VERSION "dbc-export 1 2025.20.8"

NS_ :

BS_:

BU_: ADSP APB APP APS APSB BB BMS CC CMP CMPD CP DAS DI DIF DIR DPB EPAS3P EPAS3S EPASTP EPASTS EPBL EPBR ESP GTW HVP IBST ICR IDB OCS1P ODIN PARK PCS PLG PM PMF PMR PTC RADC RCM RCM2 RCU SCCM SDCR TAS TCU TPMS TRCM UDS UI UIS UMC USM VC VCFRONT VCLEFT VCRIGHT VCSEC

BO_ 1803 VCRIGHT_logging0point1Hz: 8 VCRIGHT
 SG_ VCRIGHT_logging0point1HzIndex M : 0|4@1+ (1,0) [0|15] "" Vector__XXX
 SG_ VCRIGHT_cabinAirFilterLifeRemain m2 : 8|7@1+ (1,0) [0|127] "%" Vector__XXX
 SG_ VCRIGHT_HEPAAirFilterLifeRemaini m2 : 16|7@1+ (1,0) [0|127] "%" Vector__XXX
 SG_ VCRIGHT_leftPTCCompromisedRod m2 : 24|3@1+ (1,0) [0|7] "" Vector__XXX
 SG_ VCRIGHT_rightPTCCompromisedRod m2 : 27|3@1+ (1,0) [0|7] "" Vector__XXX
 SG_ VCRIGHT_hepaFilterHealthScore m2 : 32|7@1+ (1,0) [0|127] "%" Vector__XXX
 SG_ VCRIGHT_cabinFilterHealthScore m2 : 40|7@1+ (1,0) [0|127] "%" Vector__XXX
 SG_ VCRIGHT_cabinTempBreathLevelFOff m2 : 47|8@1+ (0.5,-40) [-40|80] "degC" Vector__XXX
 SG_ VCRIGHT_airDistributionModeAdjus m2 : 55|9@1+ (0.001,1) [1|1.5] "-" Vector__XXX
 SG_ VCRIGHT_hvacLHBleedEndStop m3 : 8|8@1+ (0.02,0) [0|5] "V" Vector__XXX
 SG_ VCRIGHT_hvacRHBleedEndStop m3 : 16|8@1+ (0.02,0) [0|5] "V" Vector__XXX
 SG_ VCRIGHT_hvacLHVaneEndStop m3 : 24|8@1+ (0.02,0) [0|5] "V" Vector__XXX
 SG_ VCRIGHT_hvacRHVaneEndStop m3 : 32|8@1+ (0.02,0) [0|5] "V" Vector__XXX
 SG_ VCRIGHT_hvacUpperModeEndStop m3 : 40|8@1+ (0.02,0) [0|5] "V" Vector__XXX
 SG_ VCRIGHT_hvacLowerModeEndStop m3 : 48|8@1+ (0.02,0) [0|5] "V" Vector__XXX
 SG_ VCRIGHT_hvacIntakeEndStop m3 : 56|8@1+ (0.02,0) [0|5] "V" Vector__XXX
 SG_ VCRIGHT_hvacLHBleedZeroStop m4 : 8|8@1+ (0.02,0) [0|5] "V" Vector__XXX
 SG_ VCRIGHT_hvacRHBleedZeroStop m4 : 16|8@1+ (0.02,0) [0|5] "V" Vector__XXX
 SG_ VCRIGHT_hvacLHVaneZeroStop m4 : 24|8@1+ (0.02,0) [0|5] "V" Vector__XXX
 SG_ VCRIGHT_hvacRHVaneZeroStop m4 : 32|8@1+ (0.02,0) [0|5] "V" Vector__XXX
 SG_ VCRIGHT_hvacUpperModeZeroStop m4 : 40|8@1+ (0.02,0) [0|5] "V" Vector__XXX
 SG_ VCRIGHT_hvacLowerModeZeroStop m4 : 48|8@1+ (0.02,0) [0|5] "V" Vector__XXX
 SG_ VCRIGHT_hvacIntakeZeroStop m4 : 56|8@1+ (0.02,0) [0|5] "V" Vector__XXX
 SG_ VCRIGHT_ambientTempLimp m6 : 8|8@1+ (0.5,-40) [-40|80] "degC" Vector__XXX
 SG_ VCRIGHT_cabinProbeTempLimp m6 : 16|8@1+ (0.5,-40) [-40|80] "degC" Vector__XXX
 SG_ VCRIGHT_thsTempLimp m6 : 24|8@1+ (0.5,-40) [-40|80] "degC" Vector__XXX
 SG_ VCRIGHT_thsCabinWaterMassLimp m6 : 32|8@1+ (0.5,0) [0|124] "g/kg" Vector__XXX
 SG_ VCRIGHT_thsSolarIrradianceLimp m6 : 40|8@1+ (5,0) [0|1270] "W/m2" Vector__XXX
 SG_ VCRIGHT_silentWakeRecordCount m6 : 48|5@1+ (1,0) [0|31] "" Vector__XXX
 SG_ VCRIGHT_evapCondensateMass m7 : 8|8@1+ (2,0) [0|500] "g" Vector__XXX
 SG_ VCRIGHT_airwaveRightLateralTotal m7 : 16|16@1+ (6100,0) [0|399763500] "deg" Vector__XXX
 SG_ VCRIGHT_airwaveLeftLateralTotalT m7 : 32|16@1+ (6100,0) [0|399763500] "deg" Vector__XXX

BO_ 611 VCRIGHT_logging10Hz: 8 VCRIGHT
 SG_ VCRIGHT_logging10HzIndex M : 0|3@1+ (1,0) [0|7] "" Vector__XXX
 SG_ VCRIGHT_hvacLHBleedTarget m0 : 8|8@1+ (0.4,0) [0|100] "%" Vector__XXX
 SG_ VCRIGHT_hvacRHBleedTarget m0 : 16|8@1+ (0.4,0) [0|100] "%" Vector__XXX
 SG_ VCRIGHT_hvacLHVaneTarget m0 : 24|8@1+ (0.4,0) [0|100] "%" Vector__XXX
 SG_ VCRIGHT_hvacRHVaneTarget m0 : 32|8@1+ (0.4,0) [0|100] "%" Vector__XXX
 SG_ VCRIGHT_hvacUpperModeTarget m0 : 40|8@1+ (0.4,0) [0|100] "%" Vector__XXX
 SG_ VCRIGHT_hvacLowerModeTarget m0 : 48|8@1+ (0.4,0) [0|100] "%" Vector__XXX
 SG_ VCRIGHT_hvacIntakeTarget m0 : 56|8@1+ (0.4,0) [0|100] "%" Vector__XXX
 SG_ VCRIGHT_hvacLHBleedPosition m1 : 8|8@1+ (0.4,0) [0|100] "%" Vector__XXX
 SG_ VCRIGHT_hvacRHBleedPosition m1 : 16|8@1+ (0.4,0) [0|100] "%" Vector__XXX
 SG_ VCRIGHT_hvacLHVanePosition m1 : 24|8@1+ (0.4,0) [0|100] "%" Vector__XXX
 SG_ VCRIGHT_hvacRHVanePosition m1 : 32|8@1+ (0.4,0) [0|100] "%" Vector__XXX
 SG_ VCRIGHT_hvacUpperModePosition m1 : 40|8@1+ (0.4,0) [0|100] "%" Vector__XXX
 SG_ VCRIGHT_hvacLowerModePosition m1 : 48|8@1+ (0.4,0) [0|100] "%" Vector__XXX
 SG_ VCRIGHT_hvacIntakePosition m1 : 56|8@1+ (0.4,0) [0|100] "%" Vector__XXX
 SG_ VCRIGHT_hvacLHBleedActuatorState m2 : 3|2@1+ (1,0) [0|3] "" Vector__XXX
 SG_ VCRIGHT_hvacRHBleedActuatorState m2 : 5|2@1+ (1,0) [0|3] "" Vector__XXX
 SG_ VCRIGHT_hvacLHVaneActuatorState m2 : 8|2@1+ (1,0) [0|3] "" Vector__XXX
 SG_ VCRIGHT_hvacRHVaneActuatorState m2 : 10|2@1+ (1,0) [0|3] "" Vector__XXX
 SG_ VCRIGHT_hvacUpperModeActState m2 : 12|2@1+ (1,0) [0|3] "" Vector__XXX
 SG_ VCRIGHT_hvacLowerModeActState m2 : 14|2@1+ (1,0) [0|3] "" Vector__XXX
 SG_ VCRIGHT_hvacIntakeActuatorState m2 : 16|2@1+ (1,0) [0|3] "" Vector__XXX
 SG_ VCRIGHT_EvapPulldownBiasActive m2 : 20|1@1+ (1,0) [0|1] "" Vector__XXX
 SG_ VCRIGHT_tempDatLeftEst m2 : 21|9@1+ (0.5,-22) [-22|200] "degC" Vector__XXX
 SG_ VCRIGHT_tempDatRightEst m2 : 30|9@1+ (0.5,-22) [-22|200] "degC" Vector__XXX
 SG_ VCRIGHT_tempDuctLeftEst m2 : 40|8@1+ (0.5,-22) [-22|105] "degC" Vector__XXX
 SG_ VCRIGHT_tempDuctRightEst m2 : 48|8@1+ (0.5,-22) [-22|105] "degC" Vector__XXX
 SG_ VCRIGHT_ptcHeaterBadRodDetection m2 : 56|4@1+ (1,0) [0|15] "" Vector__XXX
 SG_ VCRIGHT_leftVerticalActuatorDuty m4 : 8|6@1- (4,0) [-100|100] "%" Vector__XXX
 SG_ VCRIGHT_leftLateralActuatorDuty m4 : 16|6@1- (4,0) [-100|100] "%" Vector__XXX
 SG_ VCRIGHT_rightVerticalActuatorDut m4 : 24|6@1- (4,0) [-100|100] "%" Vector__XXX
 SG_ VCRIGHT_rightLateralActuatorDuty m4 : 30|6@1- (4,0) [-100|100] "%" Vector__XXX
 SG_ VCRIGHT_frontLeftSeatTempTargetQ m4 : 36|6@1+ (0.75,20) [20|60] "degC" Vector__XXX
 SG_ VCRIGHT_frontRightSeatTempTarget m4 : 42|6@1+ (1,20) [20|60] "degC" Vector__XXX

BO_ 691 VCRIGHT_logging1Hz: 8 VCRIGHT
 SG_ VCRIGHT_logging1HzIndex M : 0|5@1+ (1,0) [0|31] "" Vector__XXX
 SG_ VCRIGHT_tempIncarCabinProbe m0 : 8|8@1+ (0.5,-40) [-40|85] "degC" Vector__XXX
 SG_ VCRIGHT_tempIncarCabinDeep m0 : 16|8@1+ (0.5,-40) [-40|85] "degC" Vector__XXX
 SG_ VCRIGHT_cabinTempInteriorL2 m0 : 24|8@1+ (0.5,-40) [-40|80] "degC" Vector__XXX
 SG_ VCRIGHT_tempIncarCabinMid m0 : 32|8@1+ (0.5,-40) [-40|85] "degC" Vector__XXX
 SG_ VCRIGHT_cabinTempInteriorSunnyL2 m0 : 40|8@1+ (0.6,-40) [-40|100] "degC" Vector__XXX
 SG_ VCRIGHT_cabinTempInteriorL3 m0 : 48|8@1+ (0.5,-40) [-40|80] "degC" Vector__XXX
 SG_ VCRIGHT_cabinTempInteriorSunnyL3 m0 : 56|8@1+ (0.6,-40) [-40|100] "degC" Vector__XXX
 SG_ VCRIGHT_cabinTempGlassRoof m1 : 8|8@1+ (0.5,-40) [-40|80] "degC" Vector__XXX
 SG_ VCRIGHT_cabinTempWindshield m1 : 16|8@1+ (0.5,-40) [-40|80] "degC" Vector__XXX
 SG_ VCRIGHT_cabinTempInterior m1 : 24|8@1+ (0.5,-40) [-40|80] "degC" Vector__XXX
 SG_ VCRIGHT_cabinTempInteriorSunny m1 : 32|8@1+ (0.6,-40) [-40|100] "degC" Vector__XXX
 SG_ VCRIGHT_cabinTempSideGlassLeft m1 : 40|8@1+ (0.5,-40) [-40|80] "degC" Vector__XXX
 SG_ VCRIGHT_cabinTempSideGlassRight m1 : 48|8@1+ (0.5,-40) [-40|80] "degC" Vector__XXX
 SG_ VCRIGHT_cabinTempBreathLevel m1 : 56|8@1+ (0.5,-40) [-40|80] "degC" Vector__XXX
 SG_ VCRIGHT_pcbaTemperature m2 : 5|11@1+ (0.125,-40) [-40|150] "degC" Vector__XXX
 SG_ VCRIGHT_wattsHeaterLeftTotal m2 : 16|10@1+ (5,0) [0|4000] "W" Vector__XXX
 SG_ VCRIGHT_wattsHeaterRightTotal m2 : 26|10@1+ (5,0) [0|4000] "W" Vector__XXX
 SG_ VCRIGHT_qdotLeftFFUnsat m2 : 36|9@1- (10,0) [-1500|1500] "W" Vector__XXX
 SG_ VCRIGHT_qdotRightFFUnsat m2 : 45|9@1- (10,0) [-1500|1500] "W" Vector__XXX
 SG_ VCRIGHT_nvhLevelDb m2 : 54|9@1+ (0.1,30) [30|80] "dB" Vector__XXX
 SG_ VCRIGHT_hvacSetTempActualLeft m3 : 8|8@1+ (0.1,15) [15|28] "degC" Vector__XXX
 SG_ VCRIGHT_hvacSetTempActualRight m3 : 16|8@1+ (0.1,15) [15|28] "degC" Vector__XXX
 SG_ VCRIGHT_hvacAutoTransitionReason m3 : 24|5@1+ (1,0) [0|31] "" Vector__XXX
 SG_ VCRIGHT_hvacMassflowTarget m3 : 29|8@1+ (1,0) [0|200] "g/s" Vector__XXX
 SG_ VCRIGHT_hvacQdotLimitedLeft m3 : 37|1@1+ (1,0) [0|1] "" Vector__XXX
 SG_ VCRIGHT_hvacQdotLimitedRight m3 : 38|1@1+ (1,0) [0|1] "" Vector__XXX
 SG_ VCRIGHT_LHPanelAirflowBlocked m3 : 39|1@1+ (1,0) [0|1] "" Vector__XXX
 SG_ VCRIGHT_RHPanelAirflowBlocked m3 : 40|1@1+ (1,0) [0|1] "" Vector__XXX
 SG_ VCRIGHT_floorAirflowBlocked m3 : 41|1@1+ (1,0) [0|1] "" Vector__XXX
 SG_ VCRIGHT_defrostAirflowBlocked m3 : 42|1@1+ (1,0) [0|1] "" Vector__XXX
 SG_ VCRIGHT_hvacFilterLifeDetectActi m3 : 43|1@1+ (1,0) [0|1] "" Vector__XXX
 SG_ VCRIGHT_hvacLHBleedOperationMode m3 : 44|1@1+ (1,0) [0|1] "" Vector__XXX
 SG_ VCRIGHT_hvacRHBleedOperationMode m3 : 45|1@1+ (1,0) [0|1] "" Vector__XXX
 SG_ VCRIGHT_hvacLHVaneOperationMode m3 : 46|1@1+ (1,0) [0|1] "" Vector__XXX
 SG_ VCRIGHT_hvacRHVaneOperationMode m3 : 47|1@1+ (1,0) [0|1] "" Vector__XXX
 SG_ VCRIGHT_hvacUpperModeOpMode m3 : 48|1@1+ (1,0) [0|1] "" Vector__XXX
 SG_ VCRIGHT_hvacLowerModeOpMode m3 : 49|1@1+ (1,0) [0|1] "" Vector__XXX
 SG_ VCRIGHT_hvacIntakeOperationMode m3 : 50|1@1+ (1,0) [0|1] "" Vector__XXX
 SG_ VCRIGHT_isProbeFeedbackApplied m3 : 52|3@1+ (1,0) [0|7] "" Vector__XXX
 SG_ VCRIGHT_feedbackPullDownScalar m3 : 55|2@1+ (30,70) [70|130] "-" Vector__XXX
 SG_ VCRIGHT_feedForwardPullDownScala m3 : 57|6@1+ (1,70) [70|130] "-" Vector__XXX
 SG_ VCRIGHT_convectionTargetLeft m4 : 5|9@1+ (4,-1000) [-1000|1000] "W/m2" Vector__XXX
 SG_ VCRIGHT_convectionTargetRight m4 : 14|9@1+ (4,-1000) [-1000|1000] "W/m2" Vector__XXX
 SG_ VCRIGHT_convectionDeliveredLeft m4 : 23|9@1+ (4,-1000) [-1000|1000] "W/m2" Vector__XXX
 SG_ VCRIGHT_convectionDeliveredRight m4 : 32|9@1+ (4,-1000) [-1000|1000] "W/m2" Vector__XXX
 SG_ VCRIGHT_solarLoadRightOccupant m4 : 41|7@1+ (2,0) [0|252] "W/m2" Vector__XXX
 SG_ VCRIGHT_solarLoadLeftOccupant m4 : 48|7@1+ (2,0) [0|252] "W/m2" Vector__XXX
 SG_ VCRIGHT_ptcShutOutletMitigationA m4 : 55|1@1+ (1,0) [0|1] "" Vector__XXX
 SG_ VCRIGHT_solarLoadFromThsTemp m4 : 56|8@1+ (8,-1020) [-1020|1012] "W/m2" Vector__XXX
 SG_ VCRIGHT_ptcHeaterTempDuctHigh m5 : 5|1@1+ (1,0) [0|1] "" Vector__XXX
 SG_ VCRIGHT_ptcHeaterTempDuctFault m5 : 6|1@1+ (1,0) [0|1] "" Vector__XXX
 SG_ VCRIGHT_ptcHeaterNoAirflow m5 : 7|1@1+ (1,0) [0|1] "" Vector__XXX
 SG_ VCRIGHT_ptcHeaterHvacActNotReady m5 : 8|1@1+ (1,0) [0|1] "" Vector__XXX
 SG_ VCRIGHT_ptcHeaterNoUiRequest m5 : 9|1@1+ (1,0) [0|1] "" Vector__XXX
 SG_ VCRIGHT_ptcHeaterNoHighVoltage m5 : 10|1@1+ (1,0) [0|1] "" Vector__XXX
 SG_ VCRIGHT_ptcHeaterLAirPathBlocked m5 : 11|1@1+ (1,0) [0|1] "" Vector__XXX
 SG_ VCRIGHT_ptcHeaterRAirPathBlocked m5 : 12|1@1+ (1,0) [0|1] "" Vector__XXX
 SG_ VCRIGHT_ptcHeaterReqAirpathBlock m5 : 13|1@1+ (1,0) [0|1] "" Vector__XXX
 SG_ VCRIGHT_hvacQdotFeedforward m5 : 16|16@1+ (1,-32767) [-32767|32767] "W" Vector__XXX
 SG_ VCRIGHT_evapLoadInFresh m5 : 32|8@1+ (35,0) [0|8000] "W" Vector__XXX
 SG_ VCRIGHT_evapLoadInRecirc m5 : 40|8@1+ (35,0) [0|8000] "W" Vector__XXX
 SG_ VCRIGHT_cabinTempWshldDefog m5 : 48|8@1+ (0.5,-40) [-40|80] "degC" Vector__XXX
 SG_ VCRIGHT_cabinTempWshldDefogTop m5 : 56|8@1+ (0.5,-40) [-40|80] "degC" Vector__XXX
 SG_ VCRIGHT_hvacLHBleedVoltage m6 : 8|8@1+ (0.02,0) [0|5] "V" Vector__XXX
 SG_ VCRIGHT_hvacRHBleedVoltage m6 : 16|8@1+ (0.02,0) [0|5] "V" Vector__XXX
 SG_ VCRIGHT_hvacLHVaneVoltage m6 : 24|8@1+ (0.02,0) [0|5] "V" Vector__XXX
 SG_ VCRIGHT_hvacRHVaneVoltage m6 : 32|8@1+ (0.02,0) [0|5] "V" Vector__XXX
 SG_ VCRIGHT_hvacUpperModeVoltage m6 : 40|8@1+ (0.02,0) [0|5] "V" Vector__XXX
 SG_ VCRIGHT_hvacLowerModeVoltage m6 : 48|8@1+ (0.02,0) [0|5] "V" Vector__XXX
 SG_ VCRIGHT_hvacIntakeVoltage m6 : 56|8@1+ (0.02,0) [0|5] "V" Vector__XXX
 SG_ VCRIGHT_cabinTempBreathLevelFHea m7 : 8|8@1+ (0.5,-40) [-40|80] "degC" Vector__XXX
 SG_ VCRIGHT_cabinTempBreathLevelFCoo m7 : 16|8@1+ (0.5,-40) [-40|80] "degC" Vector__XXX
 SG_ VCRIGHT_cabinTempBreathLeve_0002 m7 : 24|8@1+ (0.5,-40) [-40|80] "degC" Vector__XXX
 SG_ VCRIGHT_cabinTempBreathLevelF5mi m7 : 32|8@1+ (0.5,-40) [-40|80] "degC" Vector__XXX
 SG_ VCRIGHT_cabinTempBreathLeve_0001 m7 : 40|8@1+ (0.5,-40) [-40|80] "degC" Vector__XXX
 SG_ VCRIGHT_cabinTempBreathLevelF10m m7 : 48|8@1+ (0.5,-40) [-40|80] "degC" Vector__XXX
 SG_ VCRIGHT_cabinTempInteriorFHeatin m7 : 56|8@1+ (0.5,-40) [-40|80] "degC" Vector__XXX
 SG_ VCRIGHT_hvacCabOvrheatProtActive m8 : 5|1@1+ (1,0) [0|1] "" Vector__XXX
 SG_ VCRIGHT_hvacCabinPurgeAllowed m8 : 6|1@1+ (1,0) [0|1] "" Vector__XXX
 SG_ VCRIGHT_hvacCabOvrheatProtAllowe m8 : 7|1@1+ (1,0) [0|1] "" Vector__XXX
 SG_ VCRIGHT_filterLifeBlowerTorque m8 : 8|10@1+ (0.006,-1.5) [-1.5|4.5] "Nm" Vector__XXX
 SG_ VCRIGHT_cabinTempFanCurrent m8 : 18|6@1+ (0.001,-0.01) [-0.01|0.05] "A" Vector__XXX
 SG_ VCRIGHT_cabinTempFanOutput m8 : 24|1@1+ (1,0) [0|1] "" Vector__XXX
 SG_ VCRIGHT_cloudinessEstimatedPct m8 : 25|7@1+ (1,0) [0|100] "%" Vector__XXX
 SG_ VCRIGHT_solarLoadOnVehFiltered m8 : 32|8@1+ (4,0) [0|1016] "W/m2" Vector__XXX
 SG_ VCRIGHT_cabinTempProbeEstimate m8 : 40|8@1+ (0.5,-40) [-40|80] "degC" Vector__XXX
 SG_ VCRIGHT_cabinTempThs m8 : 48|8@1+ (0.5,-40) [-40|80] "degC" Vector__XXX
 SG_ VCRIGHT_cabinTempThsBracket m8 : 56|8@1+ (0.5,-40) [-40|80] "degC" Vector__XXX
 SG_ VCRIGHT_leftHeatOvertempProtect m9 : 5|1@1+ (1,0) [0|1] "" Vector__XXX
 SG_ VCRIGHT_rightHeatOvertempProtect m9 : 6|1@1+ (1,0) [0|1] "" Vector__XXX
 SG_ VCRIGHT_CO2ppm m9 : 7|10@1+ (5,0) [0|4000] "-" Vector__XXX
 SG_ VCRIGHT_timeLeftToCabinModelInit m9 : 17|7@1+ (1,0) [0|127] "" Vector__XXX
 SG_ VCRIGHT_hvacEstimateWindshieldRH m9 : 24|8@1+ (1,0) [0|150] "%" Vector__XXX
 SG_ VCRIGHT_hvacFoggingRiskLevel m9 : 32|7@1+ (1,0) [0|100] "%" Vector__XXX
 SG_ VCRIGHT_hvacCabinHumidityLevel m9 : 39|7@1+ (1,0) [0|100] "%" Vector__XXX
 SG_ VCRIGHT_hvacFlashFoggingDetected m9 : 47|1@1+ (1,0) [0|1] "" Vector__XXX
 SG_ VCRIGHT_solarSensitivityInfr m9 : 48|7@1+ (1,0) [0|100] "-" Vector__XXX
 SG_ VCRIGHT_solarSensitivityInfrCorr m9 : 55|7@1+ (1,0) [0|100] "-" Vector__XXX
 SG_ VCRIGHT_lumbarCurrent m10 : 5|4@1+ (0.2,0) [0|3] "A" Vector__XXX
 SG_ VCRIGHT_ocsCurrent m10 : 9|3@1+ (0.01,0) [0|0.07] "A" Vector__XXX
 SG_ VCRIGHT_rcmCurrent m10 : 12|5@1+ (0.1,0) [0|3.1] "A" Vector__XXX
 SG_ VCRIGHT_radioTunerCurrent m10 : 17|4@1+ (0.1,0) [0|1.5] "A" Vector__XXX
 SG_ VCRIGHT_rearOilPumpCurrent m10 : 21|5@1+ (0.5,0) [0|15.5] "A" Vector__XXX
 SG_ VCRIGHT_rearDefrostCurrent m10 : 26|5@1+ (2,0) [0|62] "A" Vector__XXX
 SG_ VCRIGHT_tailLightCurrent m10 : 31|4@1+ (0.1,0) [0|1.5] "A" Vector__XXX
 SG_ VCRIGHT_turnTailStopLightCurrent m10 : 35|4@1+ (0.1,0) [0|1.5] "A" Vector__XXX
 SG_ VCRIGHT_reverseFogLightsCurrent m10 : 39|4@1+ (0.1,0) [0|1.4] "A" Vector__XXX
 SG_ VCRIGHT_stopReverseTurnLightCurr m10 : 43|4@1+ (0.1,0) [0|1.5] "A" Vector__XXX
 SG_ VCRIGHT_sideMirrorCurrent m10 : 47|5@1+ (0.2,0) [0|6.2] "A" Vector__XXX
 SG_ VCRIGHT_sideMirrorHeaterCurrent m10 : 52|5@1+ (0.2,0) [0|6] "A" Vector__XXX
 SG_ VCRIGHT_frontSeatHeatCushionPwr m10 : 57|7@1+ (1,0) [0|127] "W" Vector__XXX
 SG_ VCRIGHT_trunkInteriorLEDCurrent m11 : 8|4@1+ (5,0) [0|70] "mA" Vector__XXX
 SG_ VCRIGHT_mapPocketLEDsCurrent m11 : 12|4@1+ (5,0) [0|70] "mA" Vector__XXX
 SG_ VCRIGHT_miscEFuseCurrent m11 : 16|5@1+ (0.05,0) [0|1.5] "A" Vector__XXX
 SG_ VCRIGHT_interiorHandleLEDCurrent m11 : 21|4@1+ (2,0) [0|30] "mA" Vector__XXX
 SG_ VCRIGHT_miscInteriorLightsCurren m11 : 25|3@1+ (5,0) [0|30] "mA" Vector__XXX
 SG_ VCRIGHT_frontPuddleLEDCurrent m11 : 28|3@1+ (0.05,0) [0|0.3] "A" Vector__XXX
 SG_ VCRIGHT_rearPuddleLEDCurrent m11 : 31|3@1+ (0.05,0) [0|0.3] "A" Vector__XXX
 SG_ VCRIGHT_liftgateShutfaceLEDCurre m11 : 34|3@1+ (5,0) [0|30] "mA" Vector__XXX
 SG_ VCRIGHT_3rSeatTOSCurrent m11 : 37|4@1+ (5,0) [0|70] "mA" Vector__XXX
 SG_ VCRIGHT_vbatFusedCurrent m11 : 41|4@1+ (0.1,0) [0|1.4] "A" Vector__XXX
 SG_ VCRIGHT_cabinTempGlassGridHeater m11 : 45|8@1+ (0.5,-40) [-40|80] "degC" Vector__XXX
 SG_ VCRIGHT_hvacAirflowReasonRight m11 : 53|5@1+ (1,0) [0|31] "" Vector__XXX
 SG_ VCRIGHT_hvacAirflowReasonLeft m11 : 58|5@1+ (1,0) [0|31] "" Vector__XXX
 SG_ VCRIGHT_hvacMassflowTargetLeft m12 : 5|8@1+ (1,0) [0|200] "g/s" Vector__XXX
 SG_ VCRIGHT_hvacMassflowTargetRight m12 : 13|8@1+ (1,0) [0|200] "g/s" Vector__XXX
 SG_ VCRIGHT_solarLoadLeftOccupantFil m12 : 21|7@1+ (2,0) [0|252] "W/m2" Vector__XXX
 SG_ VCRIGHT_solarLoadRightOccupantFi m12 : 28|7@1+ (2,0) [0|252] "W/m2" Vector__XXX
 SG_ VCRIGHT_windshieldRHCapped m12 : 35|8@1+ (1,0) [0|150] "%" Vector__XXX
 SG_ VCRIGHT_feedbackWarmUpScalar m12 : 43|2@1+ (16,84) [84|116] "-" Vector__XXX
 SG_ VCRIGHT_maxMassflowScalarWarmUp m12 : 45|5@1+ (1,74) [74|100] "-" Vector__XXX
 SG_ VCRIGHT_feedforwardWarmUpScalar m12 : 50|6@1+ (1,80) [80|120] "-" Vector__XXX
 SG_ VCRIGHT_frontSeatHeatBackrestPwr m12 : 56|7@1+ (1,0) [0|127] "W" Vector__XXX
 SG_ VCRIGHT_maxMassflowScalar m13 : 5|6@1+ (1,60) [60|100] "-" Vector__XXX
 SG_ VCRIGHT_massflowTargetAutoInManu m13 : 11|8@1+ (1,0) [0|250] "g/s" Vector__XXX
 SG_ VCRIGHT_airflowReasonAutoInManua m13 : 19|5@1+ (1,0) [0|31] "" Vector__XXX
 SG_ VCRIGHT_airflowReasonAutoIn_0001 m13 : 24|5@1+ (1,0) [0|31] "" Vector__XXX
 SG_ VCRIGHT_airflowReasonAutoIn_0002 m13 : 29|5@1+ (1,0) [0|31] "" Vector__XXX
 SG_ VCRIGHT_cabinTempInteriorFCoolin m13 : 34|8@1+ (0.5,-40) [-40|80] "degC" Vector__XXX
 SG_ VCRIGHT_averageDuctTempFHeating m13 : 42|8@1+ (0.5,-40) [-40|80] "degC" Vector__XXX
 SG_ VCRIGHT_averageDuctTempFCooling m13 : 50|8@1+ (0.5,-40) [-40|80] "degC" Vector__XXX
 SG_ VCRIGHT_hvacBiLevelWhsldRhEst m13 : 58|6@1+ (2,20) [20|120] "%" Vector__XXX
 SG_ VCRIGHT_steeringWheelSurfaceTemp m14 : 5|10@1+ (0.1,-35) [-35|65] "degC" Vector__XXX
 SG_ VCRIGHT_steeringWheelSurfac_0001 m14 : 16|10@1+ (0.1,-35) [-35|65] "degC" Vector__XXX
 SG_ VCRIGHT_timeToComfortHeating m14 : 26|6@1+ (15,-15) [-15|930] "s" Vector__XXX
 SG_ VCRIGHT_timeToComfortCooling m14 : 32|6@1+ (15,-15) [-15|930] "s" Vector__XXX
 SG_ VCRIGHT_cabinWaterMassRaw m14 : 40|8@1+ (0.1,0) [0|25] "g/kg" Vector__XXX
 SG_ VCRIGHT_massflowSingleZoneSplit m14 : 48|7@1+ (1,0) [0|100] "-" Vector__XXX
 SG_ VCRIGHT_VOCPurgeState m14 : 56|3@1+ (1,0) [0|7] "" Vector__XXX
 SG_ VCRIGHT_cameraFoggingMonitorStat m14 : 59|3@1+ (1,0) [0|7] "" Vector__XXX
 SG_ VCRIGHT_cabinOverheatProtectNotR m15 : 5|14@1+ (1,0) [0|16383] "" Vector__XXX
 SG_ VCRIGHT_hvacIntakeReason m15 : 19|5@1+ (1,0) [0|31] "" Vector__XXX
 SG_ VCRIGHT_hvacCabinPurgeActive m15 : 24|1@1+ (1,0) [0|1] "" Vector__XXX
 SG_ VCRIGHT_solarAzimuthCarRef m15 : 25|11@1- (0.5,0) [-511|511.5] "deg" Vector__XXX
 SG_ VCRIGHT_massflowPulldownBias m15 : 36|4@1+ (7,0) [0|100] "%" Vector__XXX
 SG_ VCRIGHT_evapPulldownBias m15 : 40|4@1+ (7,0) [0|100] "%" Vector__XXX
 SG_ VCRIGHT_modeledMassflowFresh m15 : 44|8@1+ (1,0) [0|255] "g/s" Vector__XXX
 SG_ VCRIGHT_modeledMassflowRecirc m15 : 52|8@1+ (1,0) [0|255] "g/s" Vector__XXX
 SG_ VCRIGHT_hvacLimpModeStatus m15 : 60|3@1+ (1,0) [0|7] "" Vector__XXX
 SG_ VCRIGHT_hvacEstimatedCameraWinds m16 : 8|8@1+ (1,0) [0|150] "%" Vector__XXX

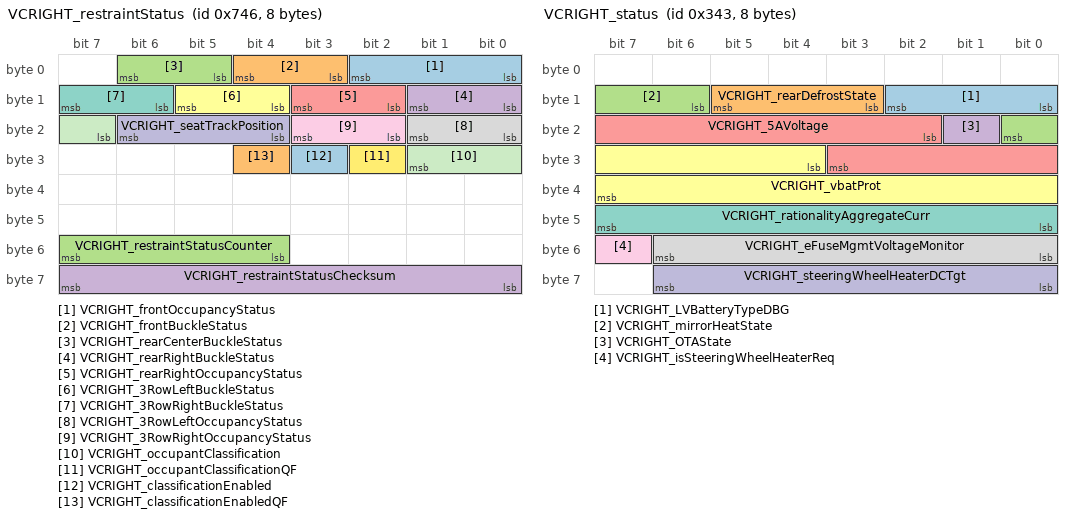
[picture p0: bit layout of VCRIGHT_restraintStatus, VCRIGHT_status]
BO_ 1862 VCRIGHT_restraintStatus: 8 VCRIGHT
 SG_ VCRIGHT_frontOccupancyStatus : 0|3@1+ (1,0) [0|6] "" Vector__XXX
 SG_ VCRIGHT_frontBuckleStatus : 3|2@1+ (1,0) [0|2] "" Vector__XXX
 SG_ VCRIGHT_rearCenterBuckleStatus : 5|2@1+ (1,0) [0|2] "" Vector__XXX
 SG_ VCRIGHT_rearRightBuckleStatus : 8|2@1+ (1,0) [0|2] "" Vector__XXX
 SG_ VCRIGHT_rearRightOccupancyStatus : 10|2@1+ (1,0) [0|2] "" Vector__XXX
 SG_ VCRIGHT_3RowLeftBuckleStatus : 12|2@1+ (1,0) [0|2] "" Vector__XXX
 SG_ VCRIGHT_3RowRightBuckleStatus : 14|2@1+ (1,0) [0|2] "" Vector__XXX
 SG_ VCRIGHT_3RowLeftOccupancyStatus : 16|2@1+ (1,0) [0|2] "" Vector__XXX
 SG_ VCRIGHT_3RowRightOccupancyStatus : 18|2@1+ (1,0) [0|2] "" Vector__XXX
 SG_ VCRIGHT_seatTrackPosition : 20|3@1+ (1,0) [0|6] "" Vector__XXX
 SG_ VCRIGHT_occupantClassification : 23|3@1+ (1,0) [0|6] "" Vector__XXX
 SG_ VCRIGHT_occupantClassificationQF : 26|1@1+ (1,0) [0|1] "" Vector__XXX
 SG_ VCRIGHT_classificationEnabled : 27|1@1+ (1,0) [0|1] "" Vector__XXX
 SG_ VCRIGHT_classificationEnabledQF : 28|1@1+ (1,0) [0|1] "" Vector__XXX
 SG_ VCRIGHT_restraintStatusCounter : 52|4@1+ (1,0) [0|15] "" Vector__XXX
 SG_ VCRIGHT_restraintStatusChecksum : 56|8@1+ (1,0) [0|255] "" Vector__XXX

BO_ 1251 VCRIGHT_seatStatus: 8 VCRIGHT
 SG_ VCRIGHT_seatStatusIndex M : 0|3@1+ (1,0) [0|7] "" Vector__XXX
 SG_ VCRIGHT_frontSeatTrackPos m0 : 8|16@1- (1,0) [-32768|32767] "" Vector__XXX
 SG_ VCRIGHT_frontSeatTrackCurrent m0 : 24|12@1- (0.01,0) [-20.48|20.47] "A" Vector__XXX
 SG_ VCRIGHT_frontSeatTrackDuty m0 : 36|12@1- (0.1,0) [-204.8|204.7] "%" Vector__XXX
 SG_ VCRIGHT_frontSeatTrackState m0 : 48|3@1+ (1,0) [0|7] "" Vector__XXX
 SG_ VCRIGHT_frontSeatTrackCalibrated m0 : 51|1@1+ (1,0) [0|1] "" Vector__XXX
 SG_ VCRIGHT_frontSeatTrackLog m0 : 52|1@1+ (1,0) [0|1] "" Vector__XXX
 SG_ VCRIGHT_frontSeatTrackBridgeSt m0 : 53|2@1+ (1,0) [0|3] "" Vector__XXX
 SG_ VCRIGHT_frontSeatBackPos m1 : 8|16@1- (1,0) [-32768|32767] "" Vector__XXX
 SG_ VCRIGHT_frontSeatBackCurrent m1 : 24|12@1- (0.01,0) [-20.48|20.47] "A" Vector__XXX
 SG_ VCRIGHT_frontSeatBackDuty m1 : 36|12@1- (0.1,0) [-204.8|204.7] "%" Vector__XXX
 SG_ VCRIGHT_frontSeatBackState m1 : 48|3@1+ (1,0) [0|7] "" Vector__XXX
 SG_ VCRIGHT_frontSeatBackCalibrated m1 : 51|1@1+ (1,0) [0|1] "" Vector__XXX
 SG_ VCRIGHT_frontSeatBackLog m1 : 52|1@1+ (1,0) [0|1] "" Vector__XXX
 SG_ VCRIGHT_frontSeatBackBridgeSt m1 : 53|2@1+ (1,0) [0|3] "" Vector__XXX
 SG_ VCRIGHT_frontSeatLiftPos m2 : 8|16@1- (1,0) [-32768|32767] "" Vector__XXX
 SG_ VCRIGHT_frontSeatLiftCurrent m2 : 24|12@1- (0.01,0) [-20.48|20.47] "A" Vector__XXX
 SG_ VCRIGHT_frontSeatLiftDuty m2 : 36|12@1- (0.1,0) [-204.8|204.7] "%" Vector__XXX
 SG_ VCRIGHT_frontSeatLiftState m2 : 48|3@1+ (1,0) [0|7] "" Vector__XXX
 SG_ VCRIGHT_frontSeatLiftCalibrated m2 : 51|1@1+ (1,0) [0|1] "" Vector__XXX
 SG_ VCRIGHT_frontSeatLiftLog m2 : 52|1@1+ (1,0) [0|1] "" Vector__XXX
 SG_ VCRIGHT_frontSeatLiftBridgeSt m2 : 53|2@1+ (1,0) [0|3] "" Vector__XXX
 SG_ VCRIGHT_frontSeatTiltPos m3 : 8|16@1- (1,0) [-32768|32767] "" Vector__XXX
 SG_ VCRIGHT_frontSeatTiltCurrent m3 : 24|12@1- (0.01,0) [-20.48|20.47] "A" Vector__XXX
 SG_ VCRIGHT_frontSeatTiltDuty m3 : 36|12@1- (0.1,0) [-204.8|204.7] "%" Vector__XXX
 SG_ VCRIGHT_frontSeatTiltState m3 : 48|3@1+ (1,0) [0|7] "" Vector__XXX
 SG_ VCRIGHT_frontSeatTiltCalibrated m3 : 51|1@1+ (1,0) [0|1] "" Vector__XXX
 SG_ VCRIGHT_frontSeatTiltLog m3 : 52|1@1+ (1,0) [0|1] "" Vector__XXX
 SG_ VCRIGHT_frontSeatTiltBridgeSt m3 : 53|2@1+ (1,0) [0|3] "" Vector__XXX
 SG_ VCRIGHT_lumbarAState m4 : 3|3@1+ (1,0) [0|7] "" Vector__XXX
 SG_ VCRIGHT_lumbarBState m4 : 6|3@1+ (1,0) [0|7] "" Vector__XXX
 SG_ VCRIGHT_lumbarAPressureHpa m4 : 9|12@1+ (1,0) [0|4095] "" Vector__XXX
 SG_ VCRIGHT_lumbarAPressureHpaFilt m4 : 21|10@1+ (1,0) [0|1023] "" Vector__XXX
 SG_ VCRIGHT_lumbarBPressureHpa m4 : 31|12@1+ (1,0) [0|4095] "" Vector__XXX
 SG_ VCRIGHT_lumbarBPressureHpaFilt m4 : 43|10@1+ (1,0) [0|1023] "" Vector__XXX
 SG_ VCRIGHT_lumbarActiveTooLongErr m4 : 53|1@1+ (1,0) [0|1] "" Vector__XXX
 SG_ VCRIGHT_lumbarMaxPErr m4 : 54|1@1+ (1,0) [0|1] "" Vector__XXX
 SG_ VCRIGHT_lumbarOvercurrentErr m4 : 55|1@1+ (1,0) [0|1] "" Vector__XXX
 SG_ VCRIGHT_lumbarMaxOperatingPErr m4 : 56|1@1+ (1,0) [0|1] "" Vector__XXX
 SG_ VCRIGHT_lumbarMinPErr m4 : 57|1@1+ (1,0) [0|1] "" Vector__XXX
 SG_ VCRIGHT_lumbarGeneralErr m4 : 58|1@1+ (1,0) [0|1] "" Vector__XXX
 SG_ VCRIGHT_lumbarDevMaxPumpPressA m4 : 59|1@1+ (1,0) [0|1] "" Vector__XXX
 SG_ VCRIGHT_lumbarDevMaxPumpPressB m4 : 60|1@1+ (1,0) [0|1] "" Vector__XXX
 SG_ VCRIGHT_frontSeatTrackPosReal m5 : 3|12@1- (1,0) [-2048|2047] "mm" Vector__XXX
 SG_ VCRIGHT_frontSeatBackPosReal m5 : 16|12@1- (0.1,0) [-204.8|204.7] "deg" Vector__XXX
 SG_ VCRIGHT_frontSeatLiftPosReal m5 : 28|12@1- (1,0) [-2048|2047] "mm" Vector__XXX
 SG_ VCRIGHT_frontSeatTiltPosReal m5 : 40|12@1- (0.1,0) [-204.8|204.7] "deg" Vector__XXX
 SG_ VCRIGHT_frontSeatTrackPosOffset m6 : 3|12@1- (1,0) [-2048|2047] "mm" Vector__XXX
 SG_ VCRIGHT_frontSeatBackPosOffset m6 : 16|12@1- (0.1,0) [-204.8|204.7] "deg" Vector__XXX
 SG_ VCRIGHT_frontSeatLiftPosOffset m6 : 28|12@1- (1,0) [-2048|2047] "mm" Vector__XXX
 SG_ VCRIGHT_frontSeatTiltPosOffset m6 : 40|12@1- (0.1,0) [-204.8|204.7] "deg" Vector__XXX

BO_ 739 VCRIGHT_seatStatus2: 7 VCRIGHT
 SG_ VCRIGHT_seatStatus2Index M : 0|4@1+ (1,0) [0|15] "" Vector__XXX
 SG_ VCRIGHT_frontSeatHeatCurrent m0 : 4|12@1+ (0.01,0) [0|40.95] "A" Vector__XXX
 SG_ VCRIGHT_frontSeatHeatDuty m0 : 16|8@1+ (1,0) [0|255] "%" Vector__XXX
 SG_ VCRIGHT_frontSeatHeatTmp m0 : 24|12@1- (0.05,0) [-40|80] "degC" Vector__XXX
 SG_ VCRIGHT_frontSeatHeatTmpTarget m0 : 36|8@1- (0.5,0) [0|60] "degC" Vector__XXX
 SG_ VCRIGHT_frontSeatHeatInhibited m0 : 44|1@1+ (1,0) [0|1] "" Vector__XXX
 SG_ VCRIGHT_frontSeatHeatPowered m0 : 45|1@1+ (1,0) [0|1] "" Vector__XXX
 SG_ VCRIGHT_rearLSeatHeatCurrent m1 : 4|12@1+ (0.01,0) [0|40.95] "A" Vector__XXX
 SG_ VCRIGHT_rearLSeatHeatDuty m1 : 16|8@1+ (1,0) [0|255] "%" Vector__XXX
 SG_ VCRIGHT_rearLSeatHeatTmp m1 : 24|12@1- (0.05,0) [-40|80] "degC" Vector__XXX
 SG_ VCRIGHT_rearLSeatHeatTmpTarget m1 : 36|8@1- (0.5,0) [0|60] "degC" Vector__XXX
 SG_ VCRIGHT_rearLSeatHeatInhibited m1 : 44|1@1+ (1,0) [0|1] "" Vector__XXX
 SG_ VCRIGHT_rearLSeatHeatPowered m1 : 45|1@1+ (1,0) [0|1] "" Vector__XXX
 SG_ VCRIGHT_rearCSeatHeatCurrent m2 : 4|12@1+ (0.01,0) [0|40.95] "A" Vector__XXX
 SG_ VCRIGHT_rearCSeatHeatDuty m2 : 16|8@1+ (1,0) [0|255] "%" Vector__XXX
 SG_ VCRIGHT_rearCSeatHeatTmp m2 : 24|12@1- (0.05,0) [-40|80] "degC" Vector__XXX
 SG_ VCRIGHT_rearCSeatHeatTmpTarget m2 : 36|8@1- (0.5,0) [0|60] "degC" Vector__XXX
 SG_ VCRIGHT_rearCSeatHeatInhibited m2 : 44|1@1+ (1,0) [0|1] "" Vector__XXX
 SG_ VCRIGHT_rearCSeatHeatPowered m2 : 45|1@1+ (1,0) [0|1] "" Vector__XXX
 SG_ VCRIGHT_rearRSeatHeatCurrent m3 : 4|12@1+ (0.01,0) [0|40.95] "A" Vector__XXX
 SG_ VCRIGHT_rearRSeatHeatDuty m3 : 16|8@1+ (1,0) [0|255] "%" Vector__XXX
 SG_ VCRIGHT_rearRSeatHeatTmp m3 : 24|12@1- (0.05,0) [-40|80] "degC" Vector__XXX
 SG_ VCRIGHT_rearRSeatHeatTmpTarget m3 : 36|8@1- (0.5,0) [0|60] "degC" Vector__XXX
 SG_ VCRIGHT_rearRSeatHeatInhibited m3 : 44|1@1+ (1,0) [0|1] "" Vector__XXX
 SG_ VCRIGHT_rearRSeatHeatPowered m3 : 45|1@1+ (1,0) [0|1] "" Vector__XXX
 SG_ VCRIGHT_2RowSeatReclineState m11 : 4|4@1+ (1,0) [0|14] "" Vector__XXX
 SG_ VCRIGHT_2RowSeatReclineDuty m11 : 8|8@1- (1,0) [-100|100] "%" Vector__XXX
 SG_ VCRIGHT_2RowSeatReclineCurrent m11 : 16|12@1- (0.05,0) [-100|100] "A" Vector__XXX
 SG_ VCRIGHT_2RowSeatReclineCalibrate m11 : 28|1@1+ (1,0) [0|1] "" Vector__XXX
 SG_ VCRIGHT_2RowSeatReclinePositionR m11 : 29|12@1- (1,0) [-2048|2047] "" Vector__XXX
 SG_ VCRIGHT_2RowSeatReclineAngle m11 : 41|12@1- (0.1,0) [-204.8|204.7] "deg" Vector__XXX
 SG_ VCRIGHT_2RowSeatReclineAbsPosSwi m11 : 53|2@1+ (1,0) [1|3] "" Vector__XXX
 SG_ VCRIGHT_2RowSeatReclinePositionS m12 : 4|3@1+ (1,0) [0|7] "" Vector__XXX
 SG_ VCRIGHT_2RowSeatReclineAdjustmen m12 : 7|1@1+ (1,0) [0|1] "" Vector__XXX
 SG_ VCRIGHT_2RowSeatReclineFoldAllow m12 : 8|1@1+ (1,0) [0|1] "" Vector__XXX
 SG_ VCRIGHT_2RowSeatReclineUnfoldAll m12 : 9|1@1+ (1,0) [0|1] "" Vector__XXX
 SG_ VCRIGHT_2RowSeatReclineNextToggl m12 : 10|2@1+ (1,0) [0|3] "" Vector__XXX
 SG_ VCRIGHT_2RowSeatReclineChoreoBlo m12 : 12|1@1+ (1,0) [0|1] "" Vector__XXX
 SG_ VCRIGHT_2RowSeat1RClashAvoidance m12 : 13|3@1+ (1,0) [0|7] "" Vector__XXX
 SG_ VCRIGHT_2RowSeat1RClashAvoi_0001 m12 : 16|2@1+ (1,0) [0|3] "" Vector__XXX
 SG_ VCRIGHT_2RowSeatReclineAbsP_0001 m12 : 18|12@1- (0.1,0) [-204.8|204.7] "deg" Vector__XXX

BO_ 835 VCRIGHT_status: 8 VCRIGHT
 SG_ VCRIGHT_LVBatteryTypeDBG : 8|3@1+ (1,0) [0|7] "" Vector__XXX
 SG_ VCRIGHT_rearDefrostState : 11|3@1+ (1,0) [1|7] "" Vector__XXX
 SG_ VCRIGHT_mirrorHeatState : 14|3@1+ (1,0) [1|7] "" Vector__XXX
 SG_ VCRIGHT_OTAState : 17|1@1+ (1,0) [0|1] "" Vector__XXX
 SG_ VCRIGHT_5AVoltage : 18|10@1+ (0.005443676,0) [0|5.568880548] "V" Vector__XXX
 SG_ VCRIGHT_vbatProt : 28|12@1+ (0.005443676,0) [0|22.29185322] "V" Vector__XXX
 SG_ VCRIGHT_rationalityAggregateCurr : 40|8@1+ (0.5,0) [0|127.5] "A" Vector__XXX
 SG_ VCRIGHT_eFuseMgmtVoltageMonitor : 48|7@1+ (0.125,0) [0|15.875] "V" Vector__XXX
 SG_ VCRIGHT_isSteeringWheelHeaterReq : 55|1@1+ (1,0) [0|1] "" Vector__XXX
 SG_ VCRIGHT_steeringWheelHeaterDCTgt : 56|7@1+ (0.01,0) [0|1] "-" Vector__XXX

BO_ 963 VCRIGHT_switchStatus: 8 VCRIGHT
 SG_ VCRIGHT_switchStatusIndex M : 0|1@1+ (1,0) [0|1] "" Vector__XXX
 SG_ VCRIGHT_frontBuckleSwitch m0 : 40|2@1+ (1,0) [0|3] "" Vector__XXX
 SG_ VCRIGHT_rearCenterBuckleSwitch m0 : 44|2@1+ (1,0) [0|3] "" Vector__XXX
 SG_ VCRIGHT_rearRightBuckleSwitch m0 : 46|2@1+ (1,0) [0|3] "" Vector__XXX
 SG_ VCRIGHT_trunkExtReleasePressedPe m1 : 1|1@1+ (1,0) [0|1] "" Vector__XXX
 SG_ VCRIGHT_frontSeatTrackBack m1 : 2|2@1+ (1,0) [1|3] "" Vector__XXX
 SG_ VCRIGHT_frontSeatTrackForward m1 : 4|2@1+ (1,0) [1|3] "" Vector__XXX
 SG_ VCRIGHT_frontSeatTiltDown m1 : 6|2@1+ (1,0) [1|3] "" Vector__XXX
 SG_ VCRIGHT_frontSeatTiltUp m1 : 8|2@1+ (1,0) [1|3] "" Vector__XXX
 SG_ VCRIGHT_frontSeatLiftDown m1 : 10|2@1+ (1,0) [1|3] "" Vector__XXX
 SG_ VCRIGHT_frontSeatLiftUp m1 : 12|2@1+ (1,0) [1|3] "" Vector__XXX
 SG_ VCRIGHT_frontSeatBackrestBack m1 : 14|2@1+ (1,0) [1|3] "" Vector__XXX
 SG_ VCRIGHT_frontSeatBackrestForward m1 : 16|2@1+ (1,0) [1|3] "" Vector__XXX
 SG_ VCRIGHT_frontSeatLumbarDown m1 : 18|2@1+ (1,0) [1|3] "" Vector__XXX
 SG_ VCRIGHT_frontSeatLumbarUp m1 : 20|2@1+ (1,0) [1|3] "" Vector__XXX
 SG_ VCRIGHT_frontSeatLumbarIn m1 : 22|2@1+ (1,0) [1|3] "" Vector__XXX
 SG_ VCRIGHT_frontSeatLumbarOut m1 : 24|2@1+ (1,0) [1|3] "" Vector__XXX
 SG_ VCRIGHT_2RowSeatReclineSwitch m1 : 26|1@1+ (1,0) [0|1] "" Vector__XXX
 SG_ VCRIGHT_2RowSeatBackrestFoldSwit m1 : 27|1@1+ (1,0) [0|1] "" Vector__XXX
 SG_ VCRIGHT_frontHandlePWM m1 : 32|7@1+ (1,0) [0|100] "%" Vector__XXX
 SG_ VCRIGHT_rearHandlePWM m1 : 40|7@1+ (1,0) [0|100] "%" Vector__XXX
 SG_ VCRIGHT_gloveboxLightCurrent m1 : 47|5@1+ (2,0) [0|62] "mA" Vector__XXX
 SG_ VCRIGHT_frontSeatALR m1 : 52|2@1+ (1,0) [1|3] "" Vector__XXX
 SG_ VCRIGHT_frontSeatResistiveOccupa m1 : 54|2@1+ (1,0) [1|3] "" Vector__XXX
 SG_ VCRIGHT_2RowSeatReclineSwitchpac m1 : 56|3@1+ (1,0) [0|7] "" Vector__XXX

BO_ 1545 VCRIGHT_udsResponse: 8 VCRIGHT
 SG_ VCRIGHT_udsResponseData_H : 7|32@0+ (1,0) [0|4294967295] "" Vector__XXX
 SG_ VCRIGHT_udsResponseData_L : 39|32@0+ (1,0) [0|4294967295] "" Vector__XXX

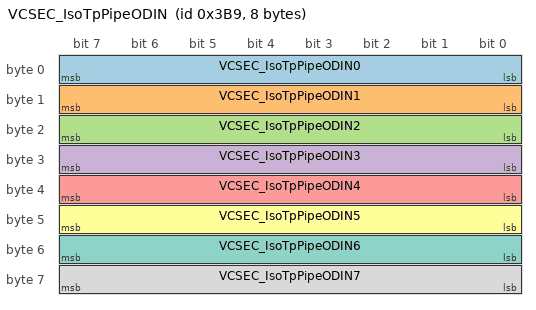
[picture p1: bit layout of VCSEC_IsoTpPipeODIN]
BO_ 953 VCSEC_IsoTpPipeODIN: 8 VCSEC
 SG_ VCSEC_IsoTpPipeODIN0 : 0|8@1+ (1,0) [0|255] "" Vector__XXX
 SG_ VCSEC_IsoTpPipeODIN1 : 8|8@1+ (1,0) [0|255] "" Vector__XXX
 SG_ VCSEC_IsoTpPipeODIN2 : 16|8@1+ (1,0) [0|255] "" Vector__XXX
 SG_ VCSEC_IsoTpPipeODIN3 : 24|8@1+ (1,0) [0|255] "" Vector__XXX
 SG_ VCSEC_IsoTpPipeODIN4 : 32|8@1+ (1,0) [0|255] "" Vector__XXX
 SG_ VCSEC_IsoTpPipeODIN5 : 40|8@1+ (1,0) [0|255] "" Vector__XXX
 SG_ VCSEC_IsoTpPipeODIN6 : 48|8@1+ (1,0) [0|255] "" Vector__XXX
 SG_ VCSEC_IsoTpPipeODIN7 : 56|8@1+ (1,0) [0|255] "" Vector__XXX

BO_ 537 VCSEC_TPMSData: 7 VCSEC
 SG_ VCSEC_TPMSDataIndex M : 0|3@1+ (1,0) [0|7] "" Vector__XXX
 SG_ VCSEC_TPMSCapabilityPressureInAd m0 : 3|1@1+ (1,0) [0|1] "" Vector__XXX
 SG_ VCSEC_TPMSCapabilityConfigurable m0 : 4|1@1+ (1,0) [0|1] "" Vector__XXX
 SG_ VCSEC_TPMSPressureRateOfChange0 m0 : 5|10@1- (0.02,0) [-10.24|10.22] "kPa/S" Vector__XXX
 SG_ VCSEC_TPMSPressure0 m0 : 15|9@1+ (0.025,0) [0|12.75] "bar" Vector__XXX
 SG_ VCSEC_TPMSTemperature0 m0 : 24|8@1+ (1,-40) [-40|214] "degC" Vector__XXX
 SG_ VCSEC_TPMSBatVoltage0 m0 : 32|8@1+ (0.01,1.5) [1.5|4.04] "V" Vector__XXX
 SG_ VCSEC_TPMSLocation0 m0 : 40|3@1+ (1,0) [0|7] "" Vector__XXX
 SG_ VCSEC_TPMSTemperatureCompensated m0 : 43|9@1+ (0.025,0) [0|12.75] "bar" Vector__XXX
 SG_ VCSEC_TPMSCapabilityPressur_0001 m1 : 3|1@1+ (1,0) [0|1] "" Vector__XXX
 SG_ VCSEC_TPMSCapabilityConfigu_0001 m1 : 4|1@1+ (1,0) [0|1] "" Vector__XXX
 SG_ VCSEC_TPMSPressureRateOfChange1 m1 : 5|10@1- (0.02,0) [-10.24|10.22] "kPa/S" Vector__XXX
 SG_ VCSEC_TPMSPressure1 m1 : 15|9@1+ (0.025,0) [0|12.75] "bar" Vector__XXX
 SG_ VCSEC_TPMSTemperature1 m1 : 24|8@1+ (1,-40) [-40|214] "degC" Vector__XXX
 SG_ VCSEC_TPMSBatVoltage1 m1 : 32|8@1+ (0.01,1.5) [1.5|4.04] "V" Vector__XXX
 SG_ VCSEC_TPMSLocation1 m1 : 40|3@1+ (1,0) [0|7] "" Vector__XXX
 SG_ VCSEC_TPMSTemperatureCompen_0001 m1 : 43|9@1+ (0.025,0) [0|12.75] "bar" Vector__XXX
 SG_ VCSEC_TPMSCapabilityPressur_0002 m2 : 3|1@1+ (1,0) [0|1] "" Vector__XXX
 SG_ VCSEC_TPMSCapabilityConfigu_0002 m2 : 4|1@1+ (1,0) [0|1] "" Vector__XXX
 SG_ VCSEC_TPMSPressureRateOfChange2 m2 : 5|10@1- (0.02,0) [-10.24|10.22] "kPa/S" Vector__XXX
 SG_ VCSEC_TPMSPressure2 m2 : 15|9@1+ (0.025,0) [0|12.75] "bar" Vector__XXX
 SG_ VCSEC_TPMSTemperature2 m2 : 24|8@1+ (1,-40) [-40|214] "degC" Vector__XXX
 SG_ VCSEC_TPMSBatVoltage2 m2 : 32|8@1+ (0.01,1.5) [1.5|4.04] "V" Vector__XXX
 SG_ VCSEC_TPMSLocation2 m2 : 40|3@1+ (1,0) [0|7] "" Vector__XXX
 SG_ VCSEC_TPMSTemperatureCompen_0002 m2 : 43|9@1+ (0.025,0) [0|12.75] "bar" Vector__XXX
 SG_ VCSEC_TPMSCapabilityPressur_0003 m3 : 3|1@1+ (1,0) [0|1] "" Vector__XXX
 SG_ VCSEC_TPMSCapabilityConfigu_0003 m3 : 4|1@1+ (1,0) [0|1] "" Vector__XXX
 SG_ VCSEC_TPMSPressureRateOfChange3 m3 : 5|10@1- (0.02,0) [-10.24|10.22] "kPa/S" Vector__XXX
 SG_ VCSEC_TPMSPressure3 m3 : 15|9@1+ (0.025,0) [0|12.75] "bar" Vector__XXX
 SG_ VCSEC_TPMSTemperature3 m3 : 24|8@1+ (1,-40) [-40|214] "degC" Vector__XXX
 SG_ VCSEC_TPMSBatVoltage3 m3 : 32|8@1+ (0.01,1.5) [1.5|4.04] "V" Vector__XXX
 SG_ VCSEC_TPMSLocation3 m3 : 40|3@1+ (1,0) [0|7] "" Vector__XXX
 SG_ VCSEC_TPMSTemperatureCompen_0003 m3 : 43|9@1+ (0.025,0) [0|12.75] "bar" Vector__XXX
 SG_ VCSEC_TPMSRecommendedColdPressur m4 : 8|8@1+ (0.025,0) [0|6.35] "bar" Vector__XXX
 SG_ VCSEC_TPMSRecommendedColdPr_0001 m4 : 16|8@1+ (0.025,0) [0|6.35] "bar" Vector__XXX
 SG_ VCSEC_TPMSFeature0 m4 : 24|3@1+ (1,0) [0|7] "" Vector__XXX
 SG_ VCSEC_TPMSFeature1 m4 : 27|3@1+ (1,0) [0|7] "" Vector__XXX
 SG_ VCSEC_TPMSFeature0Count m4 : 32|4@1+ (1,0) [0|15] "" Vector__XXX
 SG_ VCSEC_TPMSFeature0TimeS m4 : 36|11@1+ (1,0) [0|2047] "" Vector__XXX

BO_ 570 VCSEC_TPMSStatus: 8 VCSEC
 SG_ VCSEC_TPMSStatusIndex M : 0|5@1+ (1,0) [0|31] "" Vector__XXX
 SG_ VCSEC_TPMSSystemState : 5|1@1+ (1,0) [0|1] "" Vector__XXX
 SG_ VCSEC_TPMSSensorMACAddress0 m0 : 8|48@1+ (1,0) [0|281474976710655] "" Vector__XXX
 SG_ VCSEC_TPMSSensorMACAddress1 m1 : 8|48@1+ (1,0) [0|281474976710655] "" Vector__XXX
 SG_ VCSEC_TPMSSensorMACAddress2 m2 : 8|48@1+ (1,0) [0|281474976710655] "" Vector__XXX
 SG_ VCSEC_TPMSSensorMACAddress3 m3 : 8|48@1+ (1,0) [0|281474976710655] "" Vector__XXX
 SG_ VCSEC_BLESuccessfulConnEventCoun m4 : 6|15@1+ (1,0) [0|32767] "" Vector__XXX
 SG_ VCSEC_BLEMissedConnEventCount0 m4 : 21|14@1+ (1,0) [0|16383] "" Vector__XXX
 SG_ VCSEC_BLECRCErrorConnEventCount0 m4 : 35|14@1+ (1,0) [0|16383] "" Vector__XXX
 SG_ VCSEC_BLEOtherFailuresCount0 m4 : 49|5@1+ (1,0) [0|31] "" Vector__XXX
 SG_ VCSEC_BLEUnsuccessfulConnEventRa m4 : 54|10@1+ (0.08,0) [0|81.76] "%" Vector__XXX
 SG_ VCSEC_BLESuccessfulConnEven_0001 m5 : 6|15@1+ (1,0) [0|32767] "" Vector__XXX
 SG_ VCSEC_BLEMissedConnEventCount1 m5 : 21|14@1+ (1,0) [0|16383] "" Vector__XXX
 SG_ VCSEC_BLECRCErrorConnEventCount1 m5 : 35|14@1+ (1,0) [0|16383] "" Vector__XXX
 SG_ VCSEC_BLEOtherFailuresCount1 m5 : 49|5@1+ (1,0) [0|31] "" Vector__XXX
 SG_ VCSEC_BLEUnsuccessfulConnEv_0001 m5 : 54|10@1+ (0.08,0) [0|81.76] "%" Vector__XXX
 SG_ VCSEC_BLESuccessfulConnEven_0002 m6 : 6|15@1+ (1,0) [0|32767] "" Vector__XXX
 SG_ VCSEC_BLEMissedConnEventCount2 m6 : 21|14@1+ (1,0) [0|16383] "" Vector__XXX
 SG_ VCSEC_BLECRCErrorConnEventCount2 m6 : 35|14@1+ (1,0) [0|16383] "" Vector__XXX
 SG_ VCSEC_BLEOtherFailuresCount2 m6 : 49|5@1+ (1,0) [0|31] "" Vector__XXX
 SG_ VCSEC_BLEUnsuccessfulConnEv_0002 m6 : 54|10@1+ (0.08,0) [0|81.76] "%" Vector__XXX
 SG_ VCSEC_BLESuccessfulConnEven_0003 m7 : 6|15@1+ (1,0) [0|32767] "" Vector__XXX
 SG_ VCSEC_BLEMissedConnEventCount3 m7 : 21|14@1+ (1,0) [0|16383] "" Vector__XXX
 SG_ VCSEC_BLECRCErrorConnEventCount3 m7 : 35|14@1+ (1,0) [0|16383] "" Vector__XXX
 SG_ VCSEC_BLEOtherFailuresCount3 m7 : 49|5@1+ (1,0) [0|31] "" Vector__XXX
 SG_ VCSEC_BLEUnsuccessfulConnEv_0003 m7 : 54|10@1+ (0.08,0) [0|81.76] "%" Vector__XXX
 SG_ VCSEC_TPMSSensorTIAppCRC0 m8 : 8|32@1+ (1,0) [1|4294967295] "" Vector__XXX
 SG_ VCSEC_TPMSSensorMLXAppCRC0 m8 : 40|24@1+ (1,0) [1|16777215] "" Vector__XXX
 SG_ VCSEC_TPMSSensorTIAppCRC1 m9 : 8|32@1+ (1,0) [1|4294967295] "" Vector__XXX
 SG_ VCSEC_TPMSSensorMLXAppCRC1 m9 : 40|24@1+ (1,0) [1|16777215] "" Vector__XXX
 SG_ VCSEC_TPMSSensorTIAppCRC2 m10 : 8|32@1+ (1,0) [1|4294967295] "" Vector__XXX
 SG_ VCSEC_TPMSSensorMLXAppCRC2 m10 : 40|24@1+ (1,0) [1|16777215] "" Vector__XXX
 SG_ VCSEC_TPMSSensorTIAppCRC3 m11 : 8|32@1+ (1,0) [1|4294967295] "" Vector__XXX
 SG_ VCSEC_TPMSSensorMLXAppCRC3 m11 : 40|24@1+ (1,0) [1|16777215] "" Vector__XXX
 SG_ VCSEC_TPMStotalAwakeTime0 m16 : 8|32@1+ (1,0) [0|4294967295] "" Vector__XXX
 SG_ VCSEC_TPMSTrimAdjusted0 m16 : 40|1@1+ (1,0) [0|1] "" Vector__XXX
 SG_ VCSEC_TPMSGenealogySensorState0 m16 : 41|3@1+ (1,0) [0|7] "" Vector__XXX
 SG_ VCSEC_TPMSSensorType0 m16 : 44|3@1+ (1,0) [0|7] "" Vector__XXX
 SG_ VCSEC_TPMStotalAwakeTime1 m17 : 8|32@1+ (1,0) [0|4294967295] "" Vector__XXX
 SG_ VCSEC_TPMSTrimAdjusted1 m17 : 40|1@1+ (1,0) [0|1] "" Vector__XXX
 SG_ VCSEC_TPMSGenealogySensorState1 m17 : 41|3@1+ (1,0) [0|7] "" Vector__XXX
 SG_ VCSEC_TPMSSensorType1 m17 : 44|3@1+ (1,0) [0|7] "" Vector__XXX
 SG_ VCSEC_TPMStotalAwakeTime2 m18 : 8|32@1+ (1,0) [0|4294967295] "" Vector__XXX
 SG_ VCSEC_TPMSTrimAdjusted2 m18 : 40|1@1+ (1,0) [0|1] "" Vector__XXX
 SG_ VCSEC_TPMSGenealogySensorState2 m18 : 41|3@1+ (1,0) [0|7] "" Vector__XXX
 SG_ VCSEC_TPMSSensorType2 m18 : 44|3@1+ (1,0) [0|7] "" Vector__XXX
 SG_ VCSEC_TPMStotalAwakeTime3 m19 : 8|32@1+ (1,0) [0|4294967295] "" Vector__XXX
 SG_ VCSEC_TPMSTrimAdjusted3 m19 : 40|1@1+ (1,0) [0|1] "" Vector__XXX
 SG_ VCSEC_TPMSGenealogySensorState3 m19 : 41|3@1+ (1,0) [0|7] "" Vector__XXX
 SG_ VCSEC_TPMSSensorType3 m19 : 44|3@1+ (1,0) [0|7] "" Vector__XXX

BO_ 1067 VCSEC_UWBData: 8 VCSEC
 SG_ VCSEC_UWBEndpointIndex M : 0|2@1+ (1,0) [0|3] "" Vector__XXX
 SG_ VCSEC_UWBRearRightDistance0 m0 : 2|12@1+ (1,0) [0|4094] "cm" Vector__XXX
 SG_ VCSEC_UWBRearRightDistance1 m0 : 16|12@1+ (1,0) [0|4094] "cm" Vector__XXX
 SG_ VCSEC_UWBRearRightDistance2 m0 : 28|12@1+ (1,0) [0|4094] "cm" Vector__XXX
 SG_ VCSEC_UWBLeftDistance2 m1 : 2|12@1+ (1,0) [0|4094] "cm" Vector__XXX
 SG_ VCSEC_UWBRightDistance2 m1 : 16|12@1+ (1,0) [0|4094] "cm" Vector__XXX
 SG_ VCSEC_UWBRearDistance2 m1 : 28|12@1+ (1,0) [0|4094] "cm" Vector__XXX
 SG_ VCSEC_UWBRearLeftDistance2 m1 : 40|12@1+ (1,0) [0|4094] "cm" Vector__XXX
 SG_ VCSEC_UWBCenterDistance2 m1 : 52|12@1+ (1,0) [0|4094] "cm" Vector__XXX
 SG_ VCSEC_UWBLeftDistance1 m2 : 2|12@1+ (1,0) [0|4094] "cm" Vector__XXX
 SG_ VCSEC_UWBRightDistance1 m2 : 16|12@1+ (1,0) [0|4094] "cm" Vector__XXX
 SG_ VCSEC_UWBRearDistance1 m2 : 28|12@1+ (1,0) [0|4094] "cm" Vector__XXX
 SG_ VCSEC_UWBRearLeftDistance1 m2 : 40|12@1+ (1,0) [0|4094] "cm" Vector__XXX
 SG_ VCSEC_UWBCenterDistance1 m2 : 52|12@1+ (1,0) [0|4094] "cm" Vector__XXX
 SG_ VCSEC_UWBLeftDistance0 m3 : 2|12@1+ (1,0) [0|4094] "cm" Vector__XXX
 SG_ VCSEC_UWBRightDistance0 m3 : 16|12@1+ (1,0) [0|4094] "cm" Vector__XXX
 SG_ VCSEC_UWBRearDistance0 m3 : 28|12@1+ (1,0) [0|4094] "cm" Vector__XXX
 SG_ VCSEC_UWBRearLeftDistance0 m3 : 40|12@1+ (1,0) [0|4094] "cm" Vector__XXX
 SG_ VCSEC_UWBCenterDistance0 m3 : 52|12@1+ (1,0) [0|4094] "cm" Vector__XXX

BO_ 761 VCSEC_additionalAuthInfo: 8 VCSEC
 SG_ VCSEC_activeKeyDebug : 2|5@1+ (1,0) [0|31] "" Vector__XXX
 SG_ VCSEC_bleChannelDisconnected : 7|4@1+ (1,0) [0|15] "" Vector__XXX
 SG_ VCSEC_bleDisconnectionReason : 11|8@1+ (1,0) [0|255] "" Vector__XXX
 SG_ VCSEC_bleConnetionAttemptWLEntry : 19|5@1+ (1,0) [0|31] "" Vector__XXX
 SG_ VCSEC_AdditionalAuthInfoIndex M : 27|3@1+ (1,0) [0|7] "" Vector__XXX
 SG_ VCSEC_unsecureNotificationStatus : 30|2@1+ (1,0) [0|3] "" Vector__XXX
 SG_ VCSEC_activeKeyReason m0 : 24|3@1+ (1,0) [0|7] "" Vector__XXX
 SG_ VCSEC_activeKeySHA1 m0 : 32|32@1+ (1,0) [0|4294967295] "" Vector__XXX
 SG_ VCSEC_algoUsedForSummonRange0 m1 : 0|1@1+ (1,0) [0|1] "" Vector__XXX
 SG_ VCSEC_keyWithinSummonRange0 m1 : 32|32@1+ (1,0) [0|4294967295] "" Vector__XXX
 SG_ VCSEC_algoUsedForSummonRange1 m2 : 0|1@1+ (1,0) [0|1] "" Vector__XXX
 SG_ VCSEC_keyWithinSummonRange1 m2 : 32|32@1+ (1,0) [0|4294967295] "" Vector__XXX
 SG_ VCSEC_algoUsedForSummonRange2 m3 : 0|1@1+ (1,0) [0|1] "" Vector__XXX
 SG_ VCSEC_keyWithinSummonRange2 m3 : 32|32@1+ (1,0) [0|4294967295] "" Vector__XXX
 SG_ VCSEC_BLEDeviceWithinSummonRange m4 : 32|32@1+ (1,0) [0|4294967295] "" Vector__XXX
 SG_ VCSEC_WalkupUnlockMitigationKeyI m5 : 32|5@1+ (1,0) [0|31] "" Vector__XXX
 SG_ VCSEC_WalkupUnlockMitigatio_0003 m5 : 37|5@1+ (1,0) [0|31] "" Vector__XXX
 SG_ VCSEC_WalkupUnlockMitigatio_0004 m5 : 42|5@1+ (1,0) [0|31] "" Vector__XXX
 SG_ VCSEC_WalkupUnlockMitigationDesi m5 : 47|2@1+ (1,0) [0|3] "" Vector__XXX
 SG_ VCSEC_WalkupUnlockMitigationReas m5 : 49|1@1+ (1,0) [0|1] "" Vector__XXX
 SG_ VCSEC_WalkupUnlockMitigatio_0001 m5 : 50|2@1+ (1,0) [0|3] "" Vector__XXX
 SG_ VCSEC_WalkupUnlockMitigatio_0005 m5 : 52|1@1+ (1,0) [0|1] "" Vector__XXX
 SG_ VCSEC_WalkupUnlockMitigatio_0002 m5 : 53|2@1+ (1,0) [0|3] "" Vector__XXX
 SG_ VCSEC_WalkupUnlockMitigatio_0006 m5 : 55|1@1+ (1,0) [0|1] "" Vector__XXX
 SG_ VCSEC_NFCAuthFromBPillarFormFact m5 : 56|3@1+ (1,0) [0|7] "" Vector__XXX
 SG_ VCSEC_NFCAuthFromCenterConsoleFo m5 : 59|3@1+ (1,0) [0|7] "" Vector__XXX

BO_TX_BU_ 1803 : VCRIGHT;
BO_TX_BU_ 611 : VCRIGHT;
BO_TX_BU_ 691 : VCRIGHT;
BO_TX_BU_ 1862 : VCRIGHT;
BO_TX_BU_ 1251 : VCRIGHT;
BO_TX_BU_ 739 : VCRIGHT;
BO_TX_BU_ 835 : VCRIGHT;
BO_TX_BU_ 963 : VCRIGHT;
BO_TX_BU_ 1545 : VCRIGHT;
BO_TX_BU_ 953 : VCSEC;
BO_TX_BU_ 537 : VCSEC;
BO_TX_BU_ 570 : VCSEC;
BO_TX_BU_ 1067 : VCSEC;
BO_TX_BU_ 761 : VCSEC;
CM_ BO_ 1803 "Right body controller message: logging0point1 hz";
CM_ SG_ 1803 VCRIGHT_logging0point1HzIndex "Right body controller: logging0point1 hz index";
CM_ SG_ 1803 VCRIGHT_cabinAirFilterLifeRemain "Life remaining on the cabin air filter";
CM_ SG_ 1803 VCRIGHT_HEPAAirFilterLifeRemaini "Life remaining on the cabin air filter";
CM_ SG_ 1803 VCRIGHT_leftPTCCompromisedRod "Right body controller: left PTC compromised rod";
CM_ SG_ 1803 VCRIGHT_rightPTCCompromisedRod "Right body controller: right PTC compromised rod";
CM_ SG_ 1803 VCRIGHT_hepaFilterHealthScore "Right body controller: hepa filter health score";
CM_ SG_ 1803 VCRIGHT_cabinFilterHealthScore "Right body controller: cabin filter health score";
CM_ SG_ 1803 VCRIGHT_cabinTempBreathLevelFOff "Right body controller: cabin temp breath level f off; raw 255 = signal not available (SNA)";
CM_ SG_ 1803 VCRIGHT_airDistributionModeAdjus "Right body controller: air distribution mode adjustment factor";
CM_ SG_ 1803 VCRIGHT_hvacLHBleedEndStop "Right body controller: hvac LH bleed end stop";
CM_ SG_ 1803 VCRIGHT_hvacRHBleedEndStop "Right body controller: hvac RH bleed end stop";
CM_ SG_ 1803 VCRIGHT_hvacLHVaneEndStop "Right body controller: hvac LH vane end stop";
CM_ SG_ 1803 VCRIGHT_hvacRHVaneEndStop "Right body controller: hvac RH vane end stop";
CM_ SG_ 1803 VCRIGHT_hvacUpperModeEndStop "Right body controller: hvac upper mode end stop";
CM_ SG_ 1803 VCRIGHT_hvacLowerModeEndStop "Right body controller: hvac lower mode end stop";
CM_ SG_ 1803 VCRIGHT_hvacIntakeEndStop "Right body controller: hvac intake end stop";
CM_ SG_ 1803 VCRIGHT_hvacLHBleedZeroStop "Right body controller: hvac LH bleed zero stop";
CM_ SG_ 1803 VCRIGHT_hvacRHBleedZeroStop "Right body controller: hvac RH bleed zero stop";
CM_ SG_ 1803 VCRIGHT_hvacLHVaneZeroStop "Right body controller: hvac LH vane zero stop";
CM_ SG_ 1803 VCRIGHT_hvacRHVaneZeroStop "Right body controller: hvac RH vane zero stop";
CM_ SG_ 1803 VCRIGHT_hvacUpperModeZeroStop "Right body controller: hvac upper mode zero stop";
CM_ SG_ 1803 VCRIGHT_hvacLowerModeZeroStop "Right body controller: hvac lower mode zero stop";
CM_ SG_ 1803 VCRIGHT_hvacIntakeZeroStop "Right body controller: hvac intake zero stop";
CM_ SG_ 1803 VCRIGHT_ambientTempLimp "Reports the estimated ambient temperature in limp mode; raw 255 = signal not available (SNA)";
CM_ SG_ 1803 VCRIGHT_cabinProbeTempLimp "Reports the estimated cabin probe temperature in limp mode; raw 255 = signal not available (SNA)";
CM_ SG_ 1803 VCRIGHT_thsTempLimp "Reports the estimated Tesla HVAC Sensor (THS) temperature in limp mode; raw 255 = signal not available (SNA)";
CM_ SG_ 1803 VCRIGHT_thsCabinWaterMassLimp "Reports the estimated Tesla HVAC Sensor (THS) humidity cabin water mass backup in limp mode.";
CM_ SG_ 1803 VCRIGHT_thsSolarIrradianceLimp "Reports the estimated Tesla HVAC Sensor (THS) solar irradiance backup in limp mode; raw 255 = signal not available (SNA)";
CM_ SG_ 1803 VCRIGHT_silentWakeRecordCount "Reports the number of records recorded during silent wake events.";
CM_ SG_ 1803 VCRIGHT_evapCondensateMass "Right body controller: evap condensate mass";
CM_ SG_ 1803 VCRIGHT_airwaveRightLateralTotal "Right body controller: airwave right lateral total travel";
CM_ SG_ 1803 VCRIGHT_airwaveLeftLateralTotalT "Right body controller: airwave left lateral total travel";
CM_ BO_ 611 "Right body controller message: logging10 hz";
CM_ SG_ 611 VCRIGHT_logging10HzIndex "Right body controller: logging10 hz index";
CM_ SG_ 611 VCRIGHT_hvacLHBleedTarget "Right body controller: hvac LH bleed target";
CM_ SG_ 611 VCRIGHT_hvacRHBleedTarget "Right body controller: hvac RH bleed target";
CM_ SG_ 611 VCRIGHT_hvacLHVaneTarget "Right body controller: hvac LH vane target";
CM_ SG_ 611 VCRIGHT_hvacRHVaneTarget "Right body controller: hvac RH vane target";
CM_ SG_ 611 VCRIGHT_hvacUpperModeTarget "Right body controller: hvac upper mode target";
CM_ SG_ 611 VCRIGHT_hvacLowerModeTarget "Right body controller: hvac lower mode target";
CM_ SG_ 611 VCRIGHT_hvacIntakeTarget "Right body controller: hvac intake target";
CM_ SG_ 611 VCRIGHT_hvacLHBleedPosition "Right body controller: hvac LH bleed position";
CM_ SG_ 611 VCRIGHT_hvacRHBleedPosition "Right body controller: hvac RH bleed position";
CM_ SG_ 611 VCRIGHT_hvacLHVanePosition "Right body controller: hvac LH vane position";
CM_ SG_ 611 VCRIGHT_hvacRHVanePosition "Right body controller: hvac RH vane position";
CM_ SG_ 611 VCRIGHT_hvacUpperModePosition "Right body controller: hvac upper mode position";
CM_ SG_ 611 VCRIGHT_hvacLowerModePosition "Right body controller: hvac lower mode position";
CM_ SG_ 611 VCRIGHT_hvacIntakePosition "Right body controller: hvac intake position";
CM_ SG_ 611 VCRIGHT_hvacLHBleedActuatorState "Right body controller: hvac LH bleed actuator state";
CM_ SG_ 611 VCRIGHT_hvacRHBleedActuatorState "Right body controller: hvac RH bleed actuator state";
CM_ SG_ 611 VCRIGHT_hvacLHVaneActuatorState "Right body controller: hvac LH vane actuator state";
CM_ SG_ 611 VCRIGHT_hvacRHVaneActuatorState "Right body controller: hvac RH vane actuator state";
CM_ SG_ 611 VCRIGHT_hvacUpperModeActState "Right body controller: hvac upper mode act state";
CM_ SG_ 611 VCRIGHT_hvacLowerModeActState "Right body controller: hvac lower mode act state";
CM_ SG_ 611 VCRIGHT_hvacIntakeActuatorState "Right body controller: hvac intake actuator state";
CM_ SG_ 611 VCRIGHT_EvapPulldownBiasActive "Indicates if an evap pulldown smell mitigation is active";
CM_ SG_ 611 VCRIGHT_tempDatLeftEst "Right body controller: temp dat left est; raw 255 = signal not available (SNA)";
CM_ SG_ 611 VCRIGHT_tempDatRightEst "Right body controller: temp dat right est; raw 255 = signal not available (SNA)";
CM_ SG_ 611 VCRIGHT_tempDuctLeftEst "Right body controller: temp duct left est; raw 255 = signal not available (SNA)";
CM_ SG_ 611 VCRIGHT_tempDuctRightEst "Right body controller: temp duct right est; raw 255 = signal not available (SNA)";
CM_ SG_ 611 VCRIGHT_ptcHeaterBadRodDetection "Right body controller: ptc heater bad rod detection state";
CM_ SG_ 611 VCRIGHT_leftVerticalActuatorDuty "Reports the HVAC motor duty cycle";
CM_ SG_ 611 VCRIGHT_leftLateralActuatorDuty "Reports the HVAC motor duty cycle";
CM_ SG_ 611 VCRIGHT_rightVerticalActuatorDut "Reports the HVAC motor duty cycle";
CM_ SG_ 611 VCRIGHT_rightLateralActuatorDuty "Reports the HVAC motor duty cycle";
CM_ SG_ 611 VCRIGHT_frontLeftSeatTempTargetQ "Reports the front left seat heating target temperature.";
CM_ SG_ 611 VCRIGHT_frontRightSeatTempTarget "Reports the front right seat heating target temperature.";
CM_ BO_ 691 "Right body controller message: logging1 hz";
CM_ SG_ 691 VCRIGHT_logging1HzIndex "Right body controller: logging1 hz index";
CM_ SG_ 691 VCRIGHT_tempIncarCabinProbe "Right body controller: temp incar cabin probe; raw 255 = signal not available (SNA)";
CM_ SG_ 691 VCRIGHT_tempIncarCabinDeep "Right body controller: temp incar cabin deep; raw 255 = signal not available (SNA)";
CM_ SG_ 691 VCRIGHT_cabinTempInteriorL2 "Right body controller: cabin temp interior L2; raw 255 = signal not available (SNA)";
CM_ SG_ 691 VCRIGHT_tempIncarCabinMid "Right body controller: temp incar cabin mid; raw 250 = signal not available (SNA)";
CM_ SG_ 691 VCRIGHT_cabinTempInteriorSunnyL2 "Right body controller: cabin temp interior sunny L2; raw 255 = signal not available (SNA)";
CM_ SG_ 691 VCRIGHT_cabinTempInteriorL3 "Right body controller: cabin temp interior L3; raw 255 = signal not available (SNA)";
CM_ SG_ 691 VCRIGHT_cabinTempInteriorSunnyL3 "Right body controller: cabin temp interior sunny L3; raw 255 = signal not available (SNA)";
CM_ SG_ 691 VCRIGHT_cabinTempGlassRoof "Modeled cabin temperature near the glass roof; raw 255 = signal not available (SNA)";
CM_ SG_ 691 VCRIGHT_cabinTempWindshield "Windshield temperature estimate; raw 255 = signal not available (SNA)";
CM_ SG_ 691 VCRIGHT_cabinTempInterior "Modeled interior cabin temperature; raw 255 = signal not available (SNA)";
CM_ SG_ 691 VCRIGHT_cabinTempInteriorSunny "Modeled interior surface temperature exposed to direct sunlight; raw 255 = signal not available (SNA)";
CM_ SG_ 691 VCRIGHT_cabinTempSideGlassLeft "Modeled glass temperature left; raw 255 = signal not available (SNA)";
CM_ SG_ 691 VCRIGHT_cabinTempSideGlassRight "Modeled glass temperature right; raw 255 = signal not available (SNA)";
CM_ SG_ 691 VCRIGHT_cabinTempBreathLevel "Modeled cabin temperature near occupant breathing level; raw 255 = signal not available (SNA)";
CM_ SG_ 691 VCRIGHT_pcbaTemperature "Right body controller: pcba temperature";
CM_ SG_ 691 VCRIGHT_wattsHeaterLeftTotal "Right body controller: watts heater left total";
CM_ SG_ 691 VCRIGHT_wattsHeaterRightTotal "Right body controller: watts heater right total";
CM_ SG_ 691 VCRIGHT_qdotLeftFFUnsat "Right body controller: qdot left FF unsat";
CM_ SG_ 691 VCRIGHT_qdotRightFFUnsat "Right body controller: qdot right FF unsat";
CM_ SG_ 691 VCRIGHT_nvhLevelDb "Right body controller: nvh level db";
CM_ SG_ 691 VCRIGHT_hvacSetTempActualLeft "HVAC internal left temperature set point";
CM_ SG_ 691 VCRIGHT_hvacSetTempActualRight "HVAC internal right temperature set point";
CM_ SG_ 691 VCRIGHT_hvacAutoTransitionReason "Reason for airflow mode change when system is operating in auto";
CM_ SG_ 691 VCRIGHT_hvacMassflowTarget "Right body controller: hvac massflow target";
CM_ SG_ 691 VCRIGHT_hvacQdotLimitedLeft "Right body controller: hvac qdot limited left";
CM_ SG_ 691 VCRIGHT_hvacQdotLimitedRight "Right body controller: hvac qdot limited right";
CM_ SG_ 691 VCRIGHT_LHPanelAirflowBlocked "Right body controller: LH panel airflow blocked";
CM_ SG_ 691 VCRIGHT_RHPanelAirflowBlocked "Right body controller: RH panel airflow blocked";
CM_ SG_ 691 VCRIGHT_floorAirflowBlocked "Right body controller: floor airflow blocked";
CM_ SG_ 691 VCRIGHT_defrostAirflowBlocked "Right body controller: defrost airflow blocked";
CM_ SG_ 691 VCRIGHT_hvacFilterLifeDetectActi "Indicates when filter life detection is active";
CM_ SG_ 691 VCRIGHT_hvacLHBleedOperationMode "Right body controller: hvac LH bleed operation mode";
CM_ SG_ 691 VCRIGHT_hvacRHBleedOperationMode "Right body controller: hvac RH bleed operation mode";
CM_ SG_ 691 VCRIGHT_hvacLHVaneOperationMode "Right body controller: hvac LH vane operation mode";
CM_ SG_ 691 VCRIGHT_hvacRHVaneOperationMode "Right body controller: hvac RH vane operation mode";
CM_ SG_ 691 VCRIGHT_hvacUpperModeOpMode "Right body controller: hvac upper mode op mode";
CM_ SG_ 691 VCRIGHT_hvacLowerModeOpMode "Right body controller: hvac lower mode op mode";
CM_ SG_ 691 VCRIGHT_hvacIntakeOperationMode "Right body controller: hvac intake operation mode";
CM_ SG_ 691 VCRIGHT_isProbeFeedbackApplied "Right body controller: is probe feedback applied";
CM_ SG_ 691 VCRIGHT_feedbackPullDownScalar "Right body controller: feedback pull down scalar";
CM_ SG_ 691 VCRIGHT_feedForwardPullDownScala "Right body controller: feed forward pull down scalar";
CM_ SG_ 691 VCRIGHT_convectionTargetLeft "Right body controller: convection target left; raw 511 = signal not available (SNA)";
CM_ SG_ 691 VCRIGHT_convectionTargetRight "Right body controller: convection target right; raw 511 = signal not available (SNA)";
CM_ SG_ 691 VCRIGHT_convectionDeliveredLeft "Right body controller: convection delivered left; raw 511 = signal not available (SNA)";
CM_ SG_ 691 VCRIGHT_convectionDeliveredRight "Right body controller: convection delivered right; raw 511 = signal not available (SNA)";
CM_ SG_ 691 VCRIGHT_solarLoadRightOccupant "Right body controller: solar load right occupant; raw 127 = signal not available (SNA)";
CM_ SG_ 691 VCRIGHT_solarLoadLeftOccupant "Right body controller: solar load left occupant; raw 127 = signal not available (SNA)";
CM_ SG_ 691 VCRIGHT_ptcShutOutletMitigationA "Right body controller: ptc shut outlet mitigation active";
CM_ SG_ 691 VCRIGHT_solarLoadFromThsTemp "Right body controller: solar load from ths temp; raw 255 = signal not available (SNA)";
CM_ SG_ 691 VCRIGHT_ptcHeaterTempDuctHigh "Right body controller: ptc heater temp duct high";
CM_ SG_ 691 VCRIGHT_ptcHeaterTempDuctFault "Right body controller: ptc heater temp duct fault";
CM_ SG_ 691 VCRIGHT_ptcHeaterNoAirflow "Right body controller: ptc heater no airflow";
CM_ SG_ 691 VCRIGHT_ptcHeaterHvacActNotReady "Right body controller: ptc heater hvac act not ready";
CM_ SG_ 691 VCRIGHT_ptcHeaterNoUiRequest "Right body controller: ptc heater no ui request";
CM_ SG_ 691 VCRIGHT_ptcHeaterNoHighVoltage "Right body controller: ptc heater no high voltage";
CM_ SG_ 691 VCRIGHT_ptcHeaterLAirPathBlocked "Right body controller: ptc heater l air path blocked";
CM_ SG_ 691 VCRIGHT_ptcHeaterRAirPathBlocked "Right body controller: ptc heater r air path blocked";
CM_ SG_ 691 VCRIGHT_ptcHeaterReqAirpathBlock "Right body controller: ptc heater req airpath blocked";
CM_ SG_ 691 VCRIGHT_hvacQdotFeedforward "Right body controller: hvac qdot feedforward";
CM_ SG_ 691 VCRIGHT_evapLoadInFresh "Right body controller: evap load in fresh";
CM_ SG_ 691 VCRIGHT_evapLoadInRecirc "Right body controller: evap load in recirc";
CM_ SG_ 691 VCRIGHT_cabinTempWshldDefog "Windshield temperature estimate used for defogging; raw 255 = signal not available (SNA)";
CM_ SG_ 691 VCRIGHT_cabinTempWshldDefogTop "Right body controller: cabin temp wshld defog top; raw 255 = signal not available (SNA)";
CM_ SG_ 691 VCRIGHT_hvacLHBleedVoltage "Right body controller: hvac LH bleed voltage";
CM_ SG_ 691 VCRIGHT_hvacRHBleedVoltage "Right body controller: hvac RH bleed voltage";
CM_ SG_ 691 VCRIGHT_hvacLHVaneVoltage "Right body controller: hvac LH vane voltage";
CM_ SG_ 691 VCRIGHT_hvacRHVaneVoltage "Right body controller: hvac RH vane voltage";
CM_ SG_ 691 VCRIGHT_hvacUpperModeVoltage "Right body controller: hvac upper mode voltage";
CM_ SG_ 691 VCRIGHT_hvacLowerModeVoltage "Right body controller: hvac lower mode voltage";
CM_ SG_ 691 VCRIGHT_hvacIntakeVoltage "Right body controller: hvac intake voltage";
CM_ SG_ 691 VCRIGHT_cabinTempBreathLevelFHea "Right body controller: cabin temp breath level f heating; raw 255 = signal not available (SNA)";
CM_ SG_ 691 VCRIGHT_cabinTempBreathLevelFCoo "Right body controller: cabin temp breath level f cooling; raw 255 = signal not available (SNA)";
CM_ SG_ 691 VCRIGHT_cabinTempBreathLeve_0002 "Right body controller: cabin temp breath level f5min heating; raw 255 = signal not available (SNA)";
CM_ SG_ 691 VCRIGHT_cabinTempBreathLevelF5mi "Right body controller: cabin temp breath level f5min cooling; raw 255 = signal not available (SNA)";
CM_ SG_ 691 VCRIGHT_cabinTempBreathLeve_0001 "Right body controller: cabin temp breath level f10min heating; raw 255 = signal not available (SNA)";
CM_ SG_ 691 VCRIGHT_cabinTempBreathLevelF10m "Right body controller: cabin temp breath level f10min cooling; raw 255 = signal not available (SNA)";
CM_ SG_ 691 VCRIGHT_cabinTempInteriorFHeatin "Right body controller: cabin temp interior f heating; raw 255 = signal not available (SNA)";
CM_ SG_ 691 VCRIGHT_hvacCabOvrheatProtActive "Status of cabin overheat protection";
CM_ SG_ 691 VCRIGHT_hvacCabinPurgeAllowed "Right body controller: hvac cabin purge allowed";
CM_ SG_ 691 VCRIGHT_hvacCabOvrheatProtAllowe "Cabin overheat protection is allowed to run";
CM_ SG_ 691 VCRIGHT_filterLifeBlowerTorque "Right body controller: filter life blower torque; raw 1023 = signal not available (SNA)";
CM_ SG_ 691 VCRIGHT_cabinTempFanCurrent "Right body controller: cabin temp fan current";
CM_ SG_ 691 VCRIGHT_cabinTempFanOutput "Right body controller: cabin temp fan output";
CM_ SG_ 691 VCRIGHT_cloudinessEstimatedPct "Right body controller: cloudiness estimated pct";
CM_ SG_ 691 VCRIGHT_solarLoadOnVehFiltered "Right body controller: solar load on veh filtered; raw 255 = signal not available (SNA)";
CM_ SG_ 691 VCRIGHT_cabinTempProbeEstimate "Right body controller: cabin temp probe estimate; raw 255 = signal not available (SNA)";
CM_ SG_ 691 VCRIGHT_cabinTempThs "Estimated temperature from Tesla HVAC Sensor; raw 255 = signal not available (SNA)";
CM_ SG_ 691 VCRIGHT_cabinTempThsBracket "Right body controller: cabin temp ths bracket; raw 255 = signal not available (SNA)";
CM_ SG_ 691 VCRIGHT_leftHeatOvertempProtect "Right body controller: left heat overtemp protect";
CM_ SG_ 691 VCRIGHT_rightHeatOvertempProtect "Right body controller: right heat overtemp protect";
CM_ SG_ 691 VCRIGHT_CO2ppm "Right body controller: co2ppm; raw 1023 = signal not available (SNA)";
CM_ SG_ 691 VCRIGHT_timeLeftToCabinModelInit "Right body controller: time left to cabin model init";
CM_ SG_ 691 VCRIGHT_hvacEstimateWindshieldRH "Estimated windshield relative humidity";
CM_ SG_ 691 VCRIGHT_hvacFoggingRiskLevel "Control signal of the windshield fogging risk controller";
CM_ SG_ 691 VCRIGHT_hvacCabinHumidityLevel "Control signal of the cabin humidity controller";
CM_ SG_ 691 VCRIGHT_hvacFlashFoggingDetected "Windshield flash fogging risk detected";
CM_ SG_ 691 VCRIGHT_solarSensitivityInfr "Right body controller: solar sensitivity infr";
CM_ SG_ 691 VCRIGHT_solarSensitivityInfrCorr "Right body controller: solar sensitivity infr corr";
CM_ SG_ 691 VCRIGHT_lumbarCurrent "Electrical current of the lumbar ECU";
CM_ SG_ 691 VCRIGHT_ocsCurrent "Electrical current of the OCS ECU";
CM_ SG_ 691 VCRIGHT_rcmCurrent "Electrical current of the RCM ECU";
CM_ SG_ 691 VCRIGHT_radioTunerCurrent "Electrical current of the Radio Tuner";
CM_ SG_ 691 VCRIGHT_rearOilPumpCurrent "Right body controller: rear oil pump current";
CM_ SG_ 691 VCRIGHT_rearDefrostCurrent "Right body controller: rear defrost current";
CM_ SG_ 691 VCRIGHT_tailLightCurrent "Electrical current of the tail and license plate lights";
CM_ SG_ 691 VCRIGHT_turnTailStopLightCurrent "Reports the electrical current of the right rear turn indicator, right rear tail light, or right rear brake light";
CM_ SG_ 691 VCRIGHT_reverseFogLightsCurrent "Electrical current of the trunk fog light; raw 15 = signal not available (SNA)";
CM_ SG_ 691 VCRIGHT_stopReverseTurnLightCurr "Reports the electrical current of the right rear brake light, right rear reverse light, or right rear turn indicator";
CM_ SG_ 691 VCRIGHT_sideMirrorCurrent "Electrical current of side mirror tilt and fold";
CM_ SG_ 691 VCRIGHT_sideMirrorHeaterCurrent "Electrical current of the mirror heater; raw 31 = signal not available (SNA)";
CM_ SG_ 691 VCRIGHT_frontSeatHeatCushionPwr "Right body controller: front seat heat cushion pwr";
CM_ SG_ 691 VCRIGHT_trunkInteriorLEDCurrent "Electrical current of the trunk interior light; raw 15 = signal not available (SNA)";
CM_ SG_ 691 VCRIGHT_mapPocketLEDsCurrent "Electrical current of the map pocket lights; raw 15 = signal not available (SNA)";
CM_ SG_ 691 VCRIGHT_miscEFuseCurrent "Right body controller: misc e fuse current; raw 31 = signal not available (SNA)";
CM_ SG_ 691 VCRIGHT_interiorHandleLEDCurrent "Electrical current of the interior handle LED";
CM_ SG_ 691 VCRIGHT_miscInteriorLightsCurren "Electrical current of the misc interior lights; raw 7 = signal not available (SNA)";
CM_ SG_ 691 VCRIGHT_frontPuddleLEDCurrent "Electrical current of the front puddle LED; raw 7 = signal not available (SNA)";
CM_ SG_ 691 VCRIGHT_rearPuddleLEDCurrent "Electrical current of the rear puddle LED; raw 7 = signal not available (SNA)";
CM_ SG_ 691 VCRIGHT_liftgateShutfaceLEDCurre "Electrical current of the liftgate shutface LED; raw 7 = signal not available (SNA)";
CM_ SG_ 691 VCRIGHT_3rSeatTOSCurrent "Electrical current of the 3R TOS; raw 15 = signal not available (SNA)";
CM_ SG_ 691 VCRIGHT_vbatFusedCurrent "Right body controller: vbat fused current; raw 15 = signal not available (SNA)";
CM_ SG_ 691 VCRIGHT_cabinTempGlassGridHeater "Right body controller: cabin temp glass grid heater; raw 255 = signal not available (SNA)";
CM_ SG_ 691 VCRIGHT_hvacAirflowReasonRight "Right body controller: hvac airflow reason right";
CM_ SG_ 691 VCRIGHT_hvacAirflowReasonLeft "Right body controller: hvac airflow reason left";
CM_ SG_ 691 VCRIGHT_hvacMassflowTargetLeft "Right body controller: hvac massflow target left";
CM_ SG_ 691 VCRIGHT_hvacMassflowTargetRight "Right body controller: hvac massflow target right";
CM_ SG_ 691 VCRIGHT_solarLoadLeftOccupantFil "Right body controller: solar load left occupant filt; raw 127 = signal not available (SNA)";
CM_ SG_ 691 VCRIGHT_solarLoadRightOccupantFi "Right body controller: solar load right occupant filt; raw 127 = signal not available (SNA)";
CM_ SG_ 691 VCRIGHT_windshieldRHCapped "Estimated windshield relative humidity";
CM_ SG_ 691 VCRIGHT_feedbackWarmUpScalar "Right body controller: feedback warm up scalar";
CM_ SG_ 691 VCRIGHT_maxMassflowScalarWarmUp "Right body controller: max massflow scalar warm up";
CM_ SG_ 691 VCRIGHT_feedforwardWarmUpScalar "Right body controller: feedforward warm up scalar";
CM_ SG_ 691 VCRIGHT_frontSeatHeatBackrestPwr "Right body controller: front seat heat backrest pwr";
CM_ SG_ 691 VCRIGHT_maxMassflowScalar "Right body controller: max massflow scalar";
CM_ SG_ 691 VCRIGHT_massflowTargetAutoInManu "Right body controller: massflow target auto in manual mode";
CM_ SG_ 691 VCRIGHT_airflowReasonAutoInManua "Right body controller: airflow reason auto in manual mode";
CM_ SG_ 691 VCRIGHT_airflowReasonAutoIn_0001 "Right body controller: airflow reason auto in manual mode left";
CM_ SG_ 691 VCRIGHT_airflowReasonAutoIn_0002 "Right body controller: airflow reason auto in manual mode right";
CM_ SG_ 691 VCRIGHT_cabinTempInteriorFCoolin "Right body controller: cabin temp interior f cooling; raw 255 = signal not available (SNA)";
CM_ SG_ 691 VCRIGHT_averageDuctTempFHeating "Estimated average duct temp temp 15 min into the drive; raw 255 = signal not available (SNA)";
CM_ SG_ 691 VCRIGHT_averageDuctTempFCooling "Estimated average duct temp temp 15 min into the drive; raw 255 = signal not available (SNA)";
CM_ SG_ 691 VCRIGHT_hvacBiLevelWhsldRhEst "Right body controller: hvac bi level whsld rh est";
CM_ SG_ 691 VCRIGHT_steeringWheelSurfaceTemp "Right body controller: steering wheel surface temp est; raw 1023 = signal not available (SNA)";
CM_ SG_ 691 VCRIGHT_steeringWheelSurfac_0001 "Right body controller: steering wheel surface temp tgt; raw 1023 = signal not available (SNA)";
CM_ SG_ 691 VCRIGHT_timeToComfortHeating "Right body controller: time to comfort heating";
CM_ SG_ 691 VCRIGHT_timeToComfortCooling "Right body controller: time to comfort cooling";
CM_ SG_ 691 VCRIGHT_cabinWaterMassRaw "Right body controller: cabin water mass raw; raw 255 = signal not available (SNA)";
CM_ SG_ 691 VCRIGHT_massflowSingleZoneSplit "Right body controller: massflow single zone split";
CM_ SG_ 691 VCRIGHT_VOCPurgeState "Right body controller: VOC purge state";
CM_ SG_ 691 VCRIGHT_cameraFoggingMonitorStat "Right body controller: camera fogging monitor state";
CM_ SG_ 691 VCRIGHT_cabinOverheatProtectNotR "Reports all reasons cabin overheat protection is not running.";
CM_ SG_ 691 VCRIGHT_hvacIntakeReason "Reason for current intake door position";
CM_ SG_ 691 VCRIGHT_hvacCabinPurgeActive "Indicates if cabin purge is active";
CM_ SG_ 691 VCRIGHT_solarAzimuthCarRef "Right body controller: solar azimuth car ref; raw 1025 = signal not available (SNA)";
CM_ SG_ 691 VCRIGHT_massflowPulldownBias "Right body controller: massflow pulldown bias";
CM_ SG_ 691 VCRIGHT_evapPulldownBias "Right body controller: evap pulldown bias";
CM_ SG_ 691 VCRIGHT_modeledMassflowFresh "Right body controller: modeled massflow fresh";
CM_ SG_ 691 VCRIGHT_modeledMassflowRecirc "Right body controller: modeled massflow recirc";
CM_ SG_ 691 VCRIGHT_hvacLimpModeStatus "Reports the cabin model limp mode status.";
CM_ SG_ 691 VCRIGHT_hvacEstimatedCameraWinds "Right body controller: hvac estimated camera windshield RH";
CM_ BO_ 1862 "Right body controller message: restraint status";
CM_ SG_ 1862 VCRIGHT_frontOccupancyStatus "Right body controller: front occupancy status; raw 7 = signal not available (SNA)";
CM_ SG_ 1862 VCRIGHT_frontBuckleStatus "Status of front right seatbelt buckle; raw 3 = signal not available (SNA)";
CM_ SG_ 1862 VCRIGHT_rearCenterBuckleStatus "Right body controller: rear center buckle status; raw 3 = signal not available (SNA)";
CM_ SG_ 1862 VCRIGHT_rearRightBuckleStatus "Right body controller: rear right buckle status; raw 3 = signal not available (SNA)";
CM_ SG_ 1862 VCRIGHT_rearRightOccupancyStatus "Right body controller: rear right occupancy status; raw 3 = signal not available (SNA)";
CM_ SG_ 1862 VCRIGHT_3RowLeftBuckleStatus "Status of third row left seatbelt buckle; raw 3 = signal not available (SNA)";
CM_ SG_ 1862 VCRIGHT_3RowRightBuckleStatus "Right body controller: 3 row right buckle status; raw 3 = signal not available (SNA)";
CM_ SG_ 1862 VCRIGHT_3RowLeftOccupancyStatus "Right body controller: 3 row left occupancy status; raw 3 = signal not available (SNA)";
CM_ SG_ 1862 VCRIGHT_3RowRightOccupancyStatus "Right body controller: 3 row right occupancy status; raw 3 = signal not available (SNA)";
CM_ SG_ 1862 VCRIGHT_seatTrackPosition "Right body controller: seat track position; raw 7 = signal not available (SNA)";
CM_ SG_ 1862 VCRIGHT_occupantClassification "Right body controller: occupant classification; raw 7 = signal not available (SNA)";
CM_ SG_ 1862 VCRIGHT_occupantClassificationQF "Right body controller: occupant classification QF";
CM_ SG_ 1862 VCRIGHT_classificationEnabled "Indicates whether the RCM should consume VCRIGHT occupant classification rather than another source such as OCS1P";
CM_ SG_ 1862 VCRIGHT_classificationEnabledQF "Indicates whether the VCRIGHT_classificationEnabled signal is valid";
CM_ SG_ 1862 VCRIGHT_restraintStatusCounter "Right body controller: restraint status counter";
CM_ SG_ 1862 VCRIGHT_restraintStatusChecksum "Right body controller: restraint status checksum";
CM_ BO_ 1251 "Right body controller message: seat status";
CM_ SG_ 1251 VCRIGHT_seatStatusIndex "Right body controller: seat status index";
CM_ SG_ 1251 VCRIGHT_frontSeatTrackPos "Motor encoder value representing front left seat track position";
CM_ SG_ 1251 VCRIGHT_frontSeatTrackCurrent "Current drawn by front left seat track motor";
CM_ SG_ 1251 VCRIGHT_frontSeatTrackDuty "Front left seat track motor duty cycle";
CM_ SG_ 1251 VCRIGHT_frontSeatTrackState "State of front right seat track motor";
CM_ SG_ 1251 VCRIGHT_frontSeatTrackCalibrated "Right body controller: front seat track calibrated";
CM_ SG_ 1251 VCRIGHT_frontSeatTrackLog "Right body controller: front seat track log";
CM_ SG_ 1251 VCRIGHT_frontSeatTrackBridgeSt "Bridge state";
CM_ SG_ 1251 VCRIGHT_frontSeatBackPos "Motor encoder value representing front right seat backrest position";
CM_ SG_ 1251 VCRIGHT_frontSeatBackCurrent "Current drawn by front right seat backrest motor";
CM_ SG_ 1251 VCRIGHT_frontSeatBackDuty "Front right seat backrest motor duty cycle";
CM_ SG_ 1251 VCRIGHT_frontSeatBackState "Active state of front right seat backrest";
CM_ SG_ 1251 VCRIGHT_frontSeatBackCalibrated "Right body controller: front seat back calibrated";
CM_ SG_ 1251 VCRIGHT_frontSeatBackLog "Right body controller: front seat back log";
CM_ SG_ 1251 VCRIGHT_frontSeatBackBridgeSt "Bridge state";
CM_ SG_ 1251 VCRIGHT_frontSeatLiftPos "Motor encoder value representing front left seat lift position";
CM_ SG_ 1251 VCRIGHT_frontSeatLiftCurrent "Current drawn by front left seat lift motor";
CM_ SG_ 1251 VCRIGHT_frontSeatLiftDuty "Front left seat lift motor duty cycle";
CM_ SG_ 1251 VCRIGHT_frontSeatLiftState "Status of front left seat motor";
CM_ SG_ 1251 VCRIGHT_frontSeatLiftCalibrated "Right body controller: front seat lift calibrated";
CM_ SG_ 1251 VCRIGHT_frontSeatLiftLog "Right body controller: front seat lift log";
CM_ SG_ 1251 VCRIGHT_frontSeatLiftBridgeSt "Bridge state";
CM_ SG_ 1251 VCRIGHT_frontSeatTiltPos "Motor encoder value representing front left seat tilt position";
CM_ SG_ 1251 VCRIGHT_frontSeatTiltCurrent "Current drawn by front left seat tilt motor";
CM_ SG_ 1251 VCRIGHT_frontSeatTiltDuty "Front left seat tilt motor duty cycle";
CM_ SG_ 1251 VCRIGHT_frontSeatTiltState "State of front right seat tilt motor";
CM_ SG_ 1251 VCRIGHT_frontSeatTiltCalibrated "Right body controller: front seat tilt calibrated";
CM_ SG_ 1251 VCRIGHT_frontSeatTiltLog "Right body controller: front seat tilt log";
CM_ SG_ 1251 VCRIGHT_frontSeatTiltBridgeSt "Bridge state";
CM_ SG_ 1251 VCRIGHT_lumbarAState "State of front right seat lumbar bladder A";
CM_ SG_ 1251 VCRIGHT_lumbarBState "State of front right lumbar bladder B";
CM_ SG_ 1251 VCRIGHT_lumbarAPressureHpa "Right body controller: lumbar a pressure hpa";
CM_ SG_ 1251 VCRIGHT_lumbarAPressureHpaFilt "logs filtered pressure of right seat lumbar bladder A";
CM_ SG_ 1251 VCRIGHT_lumbarBPressureHpa "Right body controller: lumbar b pressure hpa";
CM_ SG_ 1251 VCRIGHT_lumbarBPressureHpaFilt "logs filtered pressure of right seat lumbar bladder B";
CM_ SG_ 1251 VCRIGHT_lumbarActiveTooLongErr "Error reported by lumbar ECU: Valve activated too long";
CM_ SG_ 1251 VCRIGHT_lumbarMaxPErr "Error reported by lumbar ECU: max bladder pressure reached";
CM_ SG_ 1251 VCRIGHT_lumbarOvercurrentErr "Error reported by lumbar ECU: pump overcurrent";
CM_ SG_ 1251 VCRIGHT_lumbarMaxOperatingPErr "Error reported by lumbar ECU: max bladder operating pressure reached";
CM_ SG_ 1251 VCRIGHT_lumbarMinPErr "Error reported by lumbar ECU: min bladder pressure reached";
CM_ SG_ 1251 VCRIGHT_lumbarGeneralErr "Error reported by lumbar ECU: general error";
CM_ SG_ 1251 VCRIGHT_lumbarDevMaxPumpPressA "System has reached Tesla specified maximum pressure for lumbar bladder A";
CM_ SG_ 1251 VCRIGHT_lumbarDevMaxPumpPressB "System has reached Tesla specified maximum pressure for lumbar bladder B";
CM_ SG_ 1251 VCRIGHT_frontSeatTrackPosReal "Front right seat track position in millimeters";
CM_ SG_ 1251 VCRIGHT_frontSeatBackPosReal "Front right seat backrest position in degrees";
CM_ SG_ 1251 VCRIGHT_frontSeatLiftPosReal "Front right seat lift position in millimeters";
CM_ SG_ 1251 VCRIGHT_frontSeatTiltPosReal "Front right seat tilt position in degrees";
CM_ SG_ 1251 VCRIGHT_frontSeatTrackPosOffset "Communicates post calibration position offset of front right seat track in a physical unit";
CM_ SG_ 1251 VCRIGHT_frontSeatBackPosOffset "Communicates post calibration position offset of front right seat backrest in a physical unit";
CM_ SG_ 1251 VCRIGHT_frontSeatLiftPosOffset "Communicates post calibration position offset of front right seat lift in a physical unit";
CM_ SG_ 1251 VCRIGHT_frontSeatTiltPosOffset "Communicates post calibration position offset of front right seat tilt in a physical unit";
CM_ BO_ 739 "Right body controller message: seat status2";
CM_ SG_ 739 VCRIGHT_seatStatus2Index "Right body controller: seat status2 index";
CM_ SG_ 739 VCRIGHT_frontSeatHeatCurrent "Right body controller: front seat heat current; raw 12 = signal not available (SNA)";
CM_ SG_ 739 VCRIGHT_frontSeatHeatDuty "Right body controller: front seat heat duty";
CM_ SG_ 739 VCRIGHT_frontSeatHeatTmp "Right body controller: front seat heat tmp";
CM_ SG_ 739 VCRIGHT_frontSeatHeatTmpTarget "Target temperature for front right seat heater";
CM_ SG_ 739 VCRIGHT_frontSeatHeatInhibited "Front right seat heater duty cycle";
CM_ SG_ 739 VCRIGHT_frontSeatHeatPowered "Right body controller: front seat heat powered";
CM_ SG_ 739 VCRIGHT_rearLSeatHeatCurrent "Current drawn by rear center seat heater";
CM_ SG_ 739 VCRIGHT_rearLSeatHeatDuty "Right body controller: rear l seat heat duty";
CM_ SG_ 739 VCRIGHT_rearLSeatHeatTmp "Right body controller: rear l seat heat tmp";
CM_ SG_ 739 VCRIGHT_rearLSeatHeatTmpTarget "Right body controller: rear l seat heat tmp target";
CM_ SG_ 739 VCRIGHT_rearLSeatHeatInhibited "Right body controller: rear l seat heat inhibited";
CM_ SG_ 739 VCRIGHT_rearLSeatHeatPowered "Right body controller: rear l seat heat powered";
CM_ SG_ 739 VCRIGHT_rearCSeatHeatCurrent "Right body controller: rear c seat heat current";
CM_ SG_ 739 VCRIGHT_rearCSeatHeatDuty "Right body controller: rear c seat heat duty";
CM_ SG_ 739 VCRIGHT_rearCSeatHeatTmp "Right body controller: rear c seat heat tmp";
CM_ SG_ 739 VCRIGHT_rearCSeatHeatTmpTarget "Right body controller: rear c seat heat tmp target";
CM_ SG_ 739 VCRIGHT_rearCSeatHeatInhibited "Right body controller: rear c seat heat inhibited";
CM_ SG_ 739 VCRIGHT_rearCSeatHeatPowered "Right body controller: rear c seat heat powered";
CM_ SG_ 739 VCRIGHT_rearRSeatHeatCurrent "Right body controller: rear r seat heat current";
CM_ SG_ 739 VCRIGHT_rearRSeatHeatDuty "Right body controller: rear r seat heat duty";
CM_ SG_ 739 VCRIGHT_rearRSeatHeatTmp "Right body controller: rear r seat heat tmp";
CM_ SG_ 739 VCRIGHT_rearRSeatHeatTmpTarget "Right body controller: rear r seat heat tmp target";
CM_ SG_ 739 VCRIGHT_rearRSeatHeatInhibited "Right body controller: rear r seat heat inhibited";
CM_ SG_ 739 VCRIGHT_rearRSeatHeatPowered "Right body controller: rear r seat heat powered";
CM_ SG_ 739 VCRIGHT_2RowSeatReclineState "Reports the active state of the 2nd row seat recliner; raw 15 = signal not available (SNA)";
CM_ SG_ 739 VCRIGHT_2RowSeatReclineDuty "Reports the 2nd row seat recliner motor duty cycle";
CM_ SG_ 739 VCRIGHT_2RowSeatReclineCurrent "Reports the 2nd row seat recliner motor current";
CM_ SG_ 739 VCRIGHT_2RowSeatReclineCalibrate "Reports calibration status of the 2nd row seat recliner";
CM_ SG_ 739 VCRIGHT_2RowSeatReclinePositionR "Reports the 2nd row seat recliner raw encoder count";
CM_ SG_ 739 VCRIGHT_2RowSeatReclineAngle "Reports the position of the 2nd row seat recliner in degrees";
CM_ SG_ 739 VCRIGHT_2RowSeatReclineAbsPosSwi "Reports the status of 2nd row seat recline absolute position (comfort zone) switch; raw 0 = signal not available (SNA)";
CM_ SG_ 739 VCRIGHT_2RowSeatReclinePositionS "Reports the active position state of the 2nd row seat recliner; raw 4 = signal not available (SNA)";
CM_ SG_ 739 VCRIGHT_2RowSeatReclineAdjustmen "Indicates whether adjustment requests are currently permitted for the rear seat recliner";
CM_ SG_ 739 VCRIGHT_2RowSeatReclineFoldAllow "Indicates whether auto-fold requests are currently permitted for the rear seat recliner";
CM_ SG_ 739 VCRIGHT_2RowSeatReclineUnfoldAll "Indicates whether auto-unfold requests are currently permitted for the rear seat recliner";
CM_ SG_ 739 VCRIGHT_2RowSeatReclineNextToggl "Right body controller: 2 row seat recline next toggle direction; raw 2 = signal not available (SNA)";
CM_ SG_ 739 VCRIGHT_2RowSeatReclineChoreoBlo "Right body controller: 2 row seat recline choreo blocked by occupancy";
CM_ SG_ 739 VCRIGHT_2RowSeat1RClashAvoidance "Right body controller: 2 row seat1 r clash avoidance blocked reason";
CM_ SG_ 739 VCRIGHT_2RowSeat1RClashAvoi_0001 "Right body controller: 2 row seat1 r clash avoidance state";
CM_ SG_ 739 VCRIGHT_2RowSeatReclineAbsP_0001 "Right body controller: 2 row seat recline abs pos switch trans point";
CM_ BO_ 835 "Right body controller message: status";
CM_ SG_ 835 VCRIGHT_LVBatteryTypeDBG "Right body controller: LV battery type DBG";
CM_ SG_ 835 VCRIGHT_rearDefrostState "Right body controller: rear defrost state; raw 0 = signal not available (SNA)";
CM_ SG_ 835 VCRIGHT_mirrorHeatState "Right body controller: mirror heat state; raw 0 = signal not available (SNA)";
CM_ SG_ 835 VCRIGHT_OTAState "Right body controller: OTA state";
CM_ SG_ 835 VCRIGHT_5AVoltage "Right body controller: 5 a voltage";
CM_ SG_ 835 VCRIGHT_vbatProt "Input voltage monitor to controller";
CM_ SG_ 835 VCRIGHT_rationalityAggregateCurr "Right body controller: rationality aggregate current";
CM_ SG_ 835 VCRIGHT_eFuseMgmtVoltageMonitor "Right body controller: e fuse mgmt voltage monitor";
CM_ SG_ 835 VCRIGHT_isSteeringWheelHeaterReq "Right body controller: is steering wheel heater req";
CM_ SG_ 835 VCRIGHT_steeringWheelHeaterDCTgt "Right body controller: steering wheel heater DC tgt; raw 127 = signal not available (SNA)";
CM_ BO_ 963 "Right body controller message: switch status";
CM_ SG_ 963 VCRIGHT_switchStatusIndex "Right body controller: switch status index";
CM_ SG_ 963 VCRIGHT_frontBuckleSwitch "Right body controller: front buckle switch";
CM_ SG_ 963 VCRIGHT_rearCenterBuckleSwitch "Right body controller: rear center buckle switch";
CM_ SG_ 963 VCRIGHT_rearRightBuckleSwitch "Right body controller: rear right buckle switch";
CM_ SG_ 963 VCRIGHT_trunkExtReleasePressedPe "Right body controller: trunk ext release pressed persist";
CM_ SG_ 963 VCRIGHT_frontSeatTrackBack "Right body controller: front seat track back; raw 0 = signal not available (SNA)";
CM_ SG_ 963 VCRIGHT_frontSeatTrackForward "Right body controller: front seat track forward; raw 0 = signal not available (SNA)";
CM_ SG_ 963 VCRIGHT_frontSeatTiltDown "Right body controller: front seat tilt down; raw 0 = signal not available (SNA)";
CM_ SG_ 963 VCRIGHT_frontSeatTiltUp "Right body controller: front seat tilt up; raw 0 = signal not available (SNA)";
CM_ SG_ 963 VCRIGHT_frontSeatLiftDown "Right body controller: front seat lift down; raw 0 = signal not available (SNA)";
CM_ SG_ 963 VCRIGHT_frontSeatLiftUp "Right body controller: front seat lift up; raw 0 = signal not available (SNA)";
CM_ SG_ 963 VCRIGHT_frontSeatBackrestBack "Right body controller: front seat backrest back; raw 0 = signal not available (SNA)";
CM_ SG_ 963 VCRIGHT_frontSeatBackrestForward "Right body controller: front seat backrest forward; raw 0 = signal not available (SNA)";
CM_ SG_ 963 VCRIGHT_frontSeatLumbarDown "Right body controller: front seat lumbar down; raw 0 = signal not available (SNA)";
CM_ SG_ 963 VCRIGHT_frontSeatLumbarUp "Right body controller: front seat lumbar up; raw 0 = signal not available (SNA)";
CM_ SG_ 963 VCRIGHT_frontSeatLumbarIn "Right body controller: front seat lumbar in; raw 0 = signal not available (SNA)";
CM_ SG_ 963 VCRIGHT_frontSeatLumbarOut "Right body controller: front seat lumbar out; raw 0 = signal not available (SNA)";
CM_ SG_ 963 VCRIGHT_2RowSeatReclineSwitch "Second row seat recline switch";
CM_ SG_ 963 VCRIGHT_2RowSeatBackrestFoldSwit "Second row seat backrest fold switch";
CM_ SG_ 963 VCRIGHT_frontHandlePWM "Right body controller: front handle PWM";
CM_ SG_ 963 VCRIGHT_rearHandlePWM "Right body controller: rear handle PWM";
CM_ SG_ 963 VCRIGHT_gloveboxLightCurrent "Current through the glovebox LED";
CM_ SG_ 963 VCRIGHT_frontSeatALR "Front right seat automatic locking retractor switch; raw 0 = signal not available (SNA)";
CM_ SG_ 963 VCRIGHT_frontSeatResistiveOccupa "Front right seat occupancy status; raw 0 = signal not available (SNA)";
CM_ SG_ 963 VCRIGHT_2RowSeatReclineSwitchpac "State of the right second row powered recline adjustment switchpack";
CM_ BO_ 1545 "Right body controller message: uds response";
CM_ SG_ 1545 VCRIGHT_udsResponseData_H "Right body controller: uds response data h";
CM_ SG_ 1545 VCRIGHT_udsResponseData_L "Right body controller: uds response data l";
CM_ BO_ 953 "Vehicle security controller message";
CM_ SG_ 953 VCSEC_IsoTpPipeODIN0 "Vehicle security controller: iso tp pipe ODIN0";
CM_ SG_ 953 VCSEC_IsoTpPipeODIN1 "Vehicle security controller: iso tp pipe ODIN1";
CM_ SG_ 953 VCSEC_IsoTpPipeODIN2 "Vehicle security controller: iso tp pipe ODIN2";
CM_ SG_ 953 VCSEC_IsoTpPipeODIN3 "Vehicle security controller: iso tp pipe ODIN3";
CM_ SG_ 953 VCSEC_IsoTpPipeODIN4 "Vehicle security controller: iso tp pipe ODIN4";
CM_ SG_ 953 VCSEC_IsoTpPipeODIN5 "Vehicle security controller: iso tp pipe ODIN5";
CM_ SG_ 953 VCSEC_IsoTpPipeODIN6 "Vehicle security controller: iso tp pipe ODIN6";
CM_ SG_ 953 VCSEC_IsoTpPipeODIN7 "Vehicle security controller: iso tp pipe ODIN7";
CM_ BO_ 537 "Vehicle security controller message: TPMS data";
CM_ SG_ 537 VCSEC_TPMSDataIndex "Vehicle security controller: TPMS data index";
CM_ SG_ 537 VCSEC_TPMSCapabilityPressureInAd "Vehicle security controller: TPMS capability pressure in adv0";
CM_ SG_ 537 VCSEC_TPMSCapabilityConfigurable "Vehicle security controller: TPMS capability configurable pressure0";
CM_ SG_ 537 VCSEC_TPMSPressureRateOfChange0 "Reports the raw pressure value of TPMS sensor 0.";
CM_ SG_ 537 VCSEC_TPMSPressure0 "Indicates Absolute pressure measured by wheel unit; raw 511 = signal not available (SNA)";
CM_ SG_ 537 VCSEC_TPMSTemperature0 "Indicates temperature in tire; raw 255 = signal not available (SNA)";
CM_ SG_ 537 VCSEC_TPMSBatVoltage0 "Sensor battery voltage; raw 255 = signal not available (SNA)";
CM_ SG_ 537 VCSEC_TPMSLocation0 "Indicates the localization result";
CM_ SG_ 537 VCSEC_TPMSTemperatureCompensated "Indicates Absolute pressure measured by wheel unit; raw 511 = signal not available (SNA)";
CM_ SG_ 537 VCSEC_TPMSCapabilityPressur_0001 "Vehicle security controller: TPMS capability pressure in adv1";
CM_ SG_ 537 VCSEC_TPMSCapabilityConfigu_0001 "Vehicle security controller: TPMS capability configurable pressure1";
CM_ SG_ 537 VCSEC_TPMSPressureRateOfChange1 "Reports the raw pressure value of TPMS sensor 1.";
CM_ SG_ 537 VCSEC_TPMSPressure1 "Indicates Absolute pressure measured by wheel unit; raw 511 = signal not available (SNA)";
CM_ SG_ 537 VCSEC_TPMSTemperature1 "Indicates temperature in tire; raw 255 = signal not available (SNA)";
CM_ SG_ 537 VCSEC_TPMSBatVoltage1 "Sensor battery voltage; raw 255 = signal not available (SNA)";
CM_ SG_ 537 VCSEC_TPMSLocation1 "Indicates the localization result";
CM_ SG_ 537 VCSEC_TPMSTemperatureCompen_0001 "Indicates Absolute pressure measured by wheel unit; raw 511 = signal not available (SNA)";
CM_ SG_ 537 VCSEC_TPMSCapabilityPressur_0002 "Vehicle security controller: TPMS capability pressure in adv2";
CM_ SG_ 537 VCSEC_TPMSCapabilityConfigu_0002 "Vehicle security controller: TPMS capability configurable pressure2";
CM_ SG_ 537 VCSEC_TPMSPressureRateOfChange2 "Reports the raw pressure value of TPMS sensor 2.";
CM_ SG_ 537 VCSEC_TPMSPressure2 "Indicates Absolute pressure measured by wheel unit; raw 511 = signal not available (SNA)";
CM_ SG_ 537 VCSEC_TPMSTemperature2 "Indicates temperature in tire; raw 255 = signal not available (SNA)";
CM_ SG_ 537 VCSEC_TPMSBatVoltage2 "Sensor battery voltage; raw 255 = signal not available (SNA)";
CM_ SG_ 537 VCSEC_TPMSLocation2 "Indicates the localization result";
CM_ SG_ 537 VCSEC_TPMSTemperatureCompen_0002 "Indicates Absolute pressure measured by wheel unit; raw 511 = signal not available (SNA)";
CM_ SG_ 537 VCSEC_TPMSCapabilityPressur_0003 "Vehicle security controller: TPMS capability pressure in adv3";
CM_ SG_ 537 VCSEC_TPMSCapabilityConfigu_0003 "Vehicle security controller: TPMS capability configurable pressure3";
CM_ SG_ 537 VCSEC_TPMSPressureRateOfChange3 "Reports the raw pressure value of TPMS sensor 3.";
CM_ SG_ 537 VCSEC_TPMSPressure3 "Indicates Absolute pressure measured by wheel unit; raw 511 = signal not available (SNA)";
CM_ SG_ 537 VCSEC_TPMSTemperature3 "Indicates temperature in tire; raw 255 = signal not available (SNA)";
CM_ SG_ 537 VCSEC_TPMSBatVoltage3 "Sensor battery voltage; raw 255 = signal not available (SNA)";
CM_ SG_ 537 VCSEC_TPMSLocation3 "Indicates the localization result";
CM_ SG_ 537 VCSEC_TPMSTemperatureCompen_0003 "Indicates Absolute pressure measured by wheel unit; raw 511 = signal not available (SNA)";
CM_ SG_ 537 VCSEC_TPMSRecommendedColdPressur "Indicates Absolute pressure measured by wheel unit; raw 255 = signal not available (SNA)";
CM_ SG_ 537 VCSEC_TPMSRecommendedColdPr_0001 "Indicates Absolute pressure measured by wheel unit; raw 255 = signal not available (SNA)";
CM_ SG_ 537 VCSEC_TPMSFeature0 "Vehicle security controller: TPMS feature0";
CM_ SG_ 537 VCSEC_TPMSFeature1 "Vehicle security controller: TPMS feature1";
CM_ SG_ 537 VCSEC_TPMSFeature0Count "Vehicle security controller: TPMS feature0 count";
CM_ SG_ 537 VCSEC_TPMSFeature0TimeS "Vehicle security controller: TPMS feature0 time s";
CM_ BO_ 570 "Vehicle security controller message: TPMS status";
CM_ SG_ 570 VCSEC_TPMSStatusIndex "Vehicle security controller: TPMS status index";
CM_ SG_ 570 VCSEC_TPMSSystemState "High level state the TPMS system is in currently";
CM_ SG_ 570 VCSEC_TPMSSensorMACAddress0 "Vehicle security controller: TPMS sensor MAC address0";
CM_ SG_ 570 VCSEC_TPMSSensorMACAddress1 "Vehicle security controller: TPMS sensor MAC address1";
CM_ SG_ 570 VCSEC_TPMSSensorMACAddress2 "Vehicle security controller: TPMS sensor MAC address2";
CM_ SG_ 570 VCSEC_TPMSSensorMACAddress3 "Vehicle security controller: TPMS sensor MAC address3";
CM_ SG_ 570 VCSEC_BLESuccessfulConnEventCoun "Count of successful BLE connection events";
CM_ SG_ 570 VCSEC_BLEMissedConnEventCount0 "Count of missed BLE connection events";
CM_ SG_ 570 VCSEC_BLECRCErrorConnEventCount0 "Count of BLE connection events ended with a CRC error";
CM_ SG_ 570 VCSEC_BLEOtherFailuresCount0 "Count of other radio related failures";
CM_ SG_ 570 VCSEC_BLEUnsuccessfulConnEventRa "Vehicle security controller: BLE unsuccessful conn event rate0; raw 1023 = signal not available (SNA)";
CM_ SG_ 570 VCSEC_BLESuccessfulConnEven_0001 "Count of successful BLE connection events";
CM_ SG_ 570 VCSEC_BLEMissedConnEventCount1 "Count of missed BLE connection events";
CM_ SG_ 570 VCSEC_BLECRCErrorConnEventCount1 "Count of BLE connection events ended with a CRC error";
CM_ SG_ 570 VCSEC_BLEOtherFailuresCount1 "Count of other radio related failures";
CM_ SG_ 570 VCSEC_BLEUnsuccessfulConnEv_0001 "Vehicle security controller: BLE unsuccessful conn event rate1; raw 1023 = signal not available (SNA)";
CM_ SG_ 570 VCSEC_BLESuccessfulConnEven_0002 "Count of successful BLE connection events";
CM_ SG_ 570 VCSEC_BLEMissedConnEventCount2 "Count of missed BLE connection events";
CM_ SG_ 570 VCSEC_BLECRCErrorConnEventCount2 "Count of BLE connection events ended with a CRC error";
CM_ SG_ 570 VCSEC_BLEOtherFailuresCount2 "Count of other radio related failures";
CM_ SG_ 570 VCSEC_BLEUnsuccessfulConnEv_0002 "Vehicle security controller: BLE unsuccessful conn event rate2; raw 1023 = signal not available (SNA)";
CM_ SG_ 570 VCSEC_BLESuccessfulConnEven_0003 "Count of successful BLE connection events";
CM_ SG_ 570 VCSEC_BLEMissedConnEventCount3 "Count of missed BLE connection events";
CM_ SG_ 570 VCSEC_BLECRCErrorConnEventCount3 "Count of BLE connection events ended with a CRC error";
CM_ SG_ 570 VCSEC_BLEOtherFailuresCount3 "Count of other radio related failures";
CM_ SG_ 570 VCSEC_BLEUnsuccessfulConnEv_0003 "Vehicle security controller: BLE unsuccessful conn event rate3; raw 1023 = signal not available (SNA)";
CM_ SG_ 570 VCSEC_TPMSSensorTIAppCRC0 "Vehicle security controller: TPMS sensor TI app CRC0; raw 0 = signal not available (SNA)";
CM_ SG_ 570 VCSEC_TPMSSensorMLXAppCRC0 "Vehicle security controller: TPMS sensor MLX app CRC0; raw 0 = signal not available (SNA)";
CM_ SG_ 570 VCSEC_TPMSSensorTIAppCRC1 "Vehicle security controller: TPMS sensor TI app CRC1; raw 0 = signal not available (SNA)";
CM_ SG_ 570 VCSEC_TPMSSensorMLXAppCRC1 "Vehicle security controller: TPMS sensor MLX app CRC1; raw 0 = signal not available (SNA)";
CM_ SG_ 570 VCSEC_TPMSSensorTIAppCRC2 "Vehicle security controller: TPMS sensor TI app CRC2; raw 0 = signal not available (SNA)";
CM_ SG_ 570 VCSEC_TPMSSensorMLXAppCRC2 "Vehicle security controller: TPMS sensor MLX app CRC2; raw 0 = signal not available (SNA)";
CM_ SG_ 570 VCSEC_TPMSSensorTIAppCRC3 "Vehicle security controller: TPMS sensor TI app CRC3; raw 0 = signal not available (SNA)";
CM_ SG_ 570 VCSEC_TPMSSensorMLXAppCRC3 "Vehicle security controller: TPMS sensor MLX app CRC3; raw 0 = signal not available (SNA)";
CM_ SG_ 570 VCSEC_TPMStotalAwakeTime0 "Sleep and CPU time count";
CM_ SG_ 570 VCSEC_TPMSTrimAdjusted0 "Vehicle security controller: TPMS trim adjusted0";
CM_ SG_ 570 VCSEC_TPMSGenealogySensorState0 "TPMS genealogy state";
CM_ SG_ 570 VCSEC_TPMSSensorType0 "Tesla TPMS type";
CM_ SG_ 570 VCSEC_TPMStotalAwakeTime1 "Sleep and CPU time count";
CM_ SG_ 570 VCSEC_TPMSTrimAdjusted1 "Vehicle security controller: TPMS trim adjusted1";
CM_ SG_ 570 VCSEC_TPMSGenealogySensorState1 "TPMS genealogy state";
CM_ SG_ 570 VCSEC_TPMSSensorType1 "Tesla TPMS type";
CM_ SG_ 570 VCSEC_TPMStotalAwakeTime2 "Sleep and CPU time count";
CM_ SG_ 570 VCSEC_TPMSTrimAdjusted2 "Vehicle security controller: TPMS trim adjusted2";
CM_ SG_ 570 VCSEC_TPMSGenealogySensorState2 "TPMS genealogy state";
CM_ SG_ 570 VCSEC_TPMSSensorType2 "Tesla TPMS type";
CM_ SG_ 570 VCSEC_TPMStotalAwakeTime3 "Sleep and CPU time count";
CM_ SG_ 570 VCSEC_TPMSTrimAdjusted3 "Vehicle security controller: TPMS trim adjusted3";
CM_ SG_ 570 VCSEC_TPMSGenealogySensorState3 "TPMS genealogy state";
CM_ SG_ 570 VCSEC_TPMSSensorType3 "Tesla TPMS type";
CM_ BO_ 1067 "Vehicle security controller message: UWB data";
CM_ SG_ 1067 VCSEC_UWBEndpointIndex "Vehicle security controller: UWB endpoint index";
CM_ SG_ 1067 VCSEC_UWBRearRightDistance0 "Reports distance between the customer's phone and the endpoint; raw 4095 = signal not available (SNA)";
CM_ SG_ 1067 VCSEC_UWBRearRightDistance1 "Reports distance between the customer's phone and the endpoint; raw 4095 = signal not available (SNA)";
CM_ SG_ 1067 VCSEC_UWBRearRightDistance2 "Reports distance between the customer's phone and the endpoint; raw 4095 = signal not available (SNA)";
CM_ SG_ 1067 VCSEC_UWBLeftDistance2 "Reports distance between the customer's phone and the endpoint; raw 4095 = signal not available (SNA)";
CM_ SG_ 1067 VCSEC_UWBRightDistance2 "Reports distance between the customer's phone and the endpoint; raw 4095 = signal not available (SNA)";
CM_ SG_ 1067 VCSEC_UWBRearDistance2 "Reports distance between the customer's phone and the endpoint; raw 4095 = signal not available (SNA)";
CM_ SG_ 1067 VCSEC_UWBRearLeftDistance2 "Reports distance between the customer's phone and the endpoint; raw 4095 = signal not available (SNA)";
CM_ SG_ 1067 VCSEC_UWBCenterDistance2 "Reports distance between the customer's phone and the endpoint; raw 4095 = signal not available (SNA)";
CM_ SG_ 1067 VCSEC_UWBLeftDistance1 "Reports distance between the customer's phone and the endpoint; raw 4095 = signal not available (SNA)";
CM_ SG_ 1067 VCSEC_UWBRightDistance1 "Reports distance between the customer's phone and the endpoint; raw 4095 = signal not available (SNA)";
CM_ SG_ 1067 VCSEC_UWBRearDistance1 "Reports distance between the customer's phone and the endpoint; raw 4095 = signal not available (SNA)";
CM_ SG_ 1067 VCSEC_UWBRearLeftDistance1 "Reports distance between the customer's phone and the endpoint; raw 4095 = signal not available (SNA)";
CM_ SG_ 1067 VCSEC_UWBCenterDistance1 "Reports distance between the customer's phone and the endpoint; raw 4095 = signal not available (SNA)";
CM_ SG_ 1067 VCSEC_UWBLeftDistance0 "Reports distance between the customer's phone and the endpoint; raw 4095 = signal not available (SNA)";
CM_ SG_ 1067 VCSEC_UWBRightDistance0 "Reports distance between the customer's phone and the endpoint; raw 4095 = signal not available (SNA)";
CM_ SG_ 1067 VCSEC_UWBRearDistance0 "Reports distance between the customer's phone and the endpoint; raw 4095 = signal not available (SNA)";
CM_ SG_ 1067 VCSEC_UWBRearLeftDistance0 "Reports distance between the customer's phone and the endpoint; raw 4095 = signal not available (SNA)";
CM_ SG_ 1067 VCSEC_UWBCenterDistance0 "Reports distance between the customer's phone and the endpoint; raw 4095 = signal not available (SNA)";
CM_ BO_ 761 "Vehicle security controller message: additional auth info";
CM_ SG_ 761 VCSEC_activeKeyDebug "Vehicle security controller: active key debug";
CM_ SG_ 761 VCSEC_bleChannelDisconnected "Connection between vehicle and the BLE authentication device is interrupted.";
CM_ SG_ 761 VCSEC_bleDisconnectionReason "Reasons of the disconnection between vehicle and BLE authentication device.";
CM_ SG_ 761 VCSEC_bleConnetionAttemptWLEntry "Vehicle security controller: ble connetion attempt WL entry";
CM_ SG_ 761 VCSEC_AdditionalAuthInfoIndex "Vehicle security controller: additional auth info index";
CM_ SG_ 761 VCSEC_unsecureNotificationStatus "Vehicle security controller: unsecure notification status";
CM_ SG_ 761 VCSEC_activeKeyReason "Reason for picking the currently active key";
CM_ SG_ 761 VCSEC_activeKeySHA1 "Vehicle security controller: active key SHA1";
CM_ SG_ 761 VCSEC_algoUsedForSummonRange0 "Vehicle security controller: algo used for summon range0";
CM_ SG_ 761 VCSEC_keyWithinSummonRange0 "Vehicle security controller: key within summon range0";
CM_ SG_ 761 VCSEC_algoUsedForSummonRange1 "Vehicle security controller: algo used for summon range1";
CM_ SG_ 761 VCSEC_keyWithinSummonRange1 "Vehicle security controller: key within summon range1";
CM_ SG_ 761 VCSEC_algoUsedForSummonRange2 "Vehicle security controller: algo used for summon range2";
CM_ SG_ 761 VCSEC_keyWithinSummonRange2 "Vehicle security controller: key within summon range2";
CM_ SG_ 761 VCSEC_BLEDeviceWithinSummonRange "Vehicle security controller: BLE device within summon range";
CM_ SG_ 761 VCSEC_WalkupUnlockMitigationKeyI "Vehicle security controller: walkup unlock mitigation key index0";
CM_ SG_ 761 VCSEC_WalkupUnlockMitigatio_0003 "Vehicle security controller: walkup unlock mitigation key index1";
CM_ SG_ 761 VCSEC_WalkupUnlockMitigatio_0004 "Vehicle security controller: walkup unlock mitigation key index2";
CM_ SG_ 761 VCSEC_WalkupUnlockMitigationDesi "Vehicle security controller: walkup unlock mitigation desire0";
CM_ SG_ 761 VCSEC_WalkupUnlockMitigationReas "Vehicle security controller: walkup unlock mitigation reason0";
CM_ SG_ 761 VCSEC_WalkupUnlockMitigatio_0001 "Vehicle security controller: walkup unlock mitigation desire1";
CM_ SG_ 761 VCSEC_WalkupUnlockMitigatio_0005 "Vehicle security controller: walkup unlock mitigation reason1";
CM_ SG_ 761 VCSEC_WalkupUnlockMitigatio_0002 "Vehicle security controller: walkup unlock mitigation desire2";
CM_ SG_ 761 VCSEC_WalkupUnlockMitigatio_0006 "Vehicle security controller: walkup unlock mitigation reason2";
CM_ SG_ 761 VCSEC_NFCAuthFromBPillarFormFact "Reports the form factor authentication at B-pillar Near Field Communication (NFC) reader.";
CM_ SG_ 761 VCSEC_NFCAuthFromCenterConsoleFo "Reports the form factor authenticating at center console Near Field Communication (NFC) reader.";
BA_DEF_ BO_ "GenMsgCycleTime" INT 0 3600000;
BA_DEF_ BO_ "GenMsgSendType" ENUM "Cyclic","NotUsed","NotUsed","NotUsed","NotUsed","NotUsed","NotUsed","IfActive","NoMsgSendType","NotUsed";
BA_DEF_ BO_ "VFrameFormat" ENUM "StandardCAN","ExtendedCAN","reserved","J1939PG","reserved","reserved","reserved","reserved","reserved","reserved","reserved","reserved","reserved","reserved","StandardCAN_FD","ExtendedCAN_FD";
BA_DEF_ BO_ "CANFD_BRS" ENUM "0","1";
BA_DEF_ SG_ "GenSigSNA" STRING;
BA_DEF_ SG_ "SystemSignalLongSymbol" STRING;
BA_DEF_ SG_ "Confidence" ENUM "validated","plausible","layout-only","contradicted";
BA_DEF_DEF_ "GenMsgCycleTime" 0;
BA_DEF_DEF_ "GenMsgSendType" "NoMsgSendType";
BA_DEF_DEF_ "VFrameFormat" "StandardCAN";
BA_DEF_DEF_ "CANFD_BRS" "1";
BA_DEF_DEF_ "GenSigSNA" "";
BA_DEF_DEF_ "SystemSignalLongSymbol" "";
BA_DEF_DEF_ "Confidence" "layout-only";
BA_ "GenMsgCycleTime" BO_ 1803 1250;
BA_ "GenMsgSendType" BO_ 1803 0;
BA_ "GenMsgCycleTime" BO_ 611 20;
BA_ "GenMsgSendType" BO_ 611 0;
BA_ "GenMsgCycleTime" BO_ 691 60;
BA_ "GenMsgSendType" BO_ 691 0;
BA_ "GenMsgCycleTime" BO_ 1862 50;
BA_ "GenMsgSendType" BO_ 1862 0;
BA_ "GenMsgCycleTime" BO_ 1251 100;
BA_ "GenMsgSendType" BO_ 1251 0;
BA_ "GenMsgCycleTime" BO_ 739 200;
BA_ "GenMsgSendType" BO_ 739 0;
BA_ "GenMsgCycleTime" BO_ 835 100;
BA_ "GenMsgSendType" BO_ 835 0;
BA_ "GenMsgCycleTime" BO_ 963 100;
BA_ "GenMsgSendType" BO_ 963 0;
BA_ "GenMsgCycleTime" BO_ 537 100;
BA_ "GenMsgSendType" BO_ 537 0;
BA_ "GenMsgCycleTime" BO_ 570 1000;
BA_ "GenMsgSendType" BO_ 570 0;
BA_ "GenMsgCycleTime" BO_ 1067 100;
BA_ "GenMsgSendType" BO_ 1067 0;
BA_ "GenMsgCycleTime" BO_ 761 100;
BA_ "GenMsgSendType" BO_ 761 0;
BA_ "Confidence" SG_ 1803 VCRIGHT_logging0point1HzIndex 1;
BA_ "Confidence" SG_ 1803 VCRIGHT_cabinAirFilterLifeRemain 1;
BA_ "SystemSignalLongSymbol" SG_ 1803 VCRIGHT_cabinAirFilterLifeRemain "VCRIGHT_cabinAirFilterLifeRemaining";
BA_ "Confidence" SG_ 1803 VCRIGHT_HEPAAirFilterLifeRemaini 1;
BA_ "SystemSignalLongSymbol" SG_ 1803 VCRIGHT_HEPAAirFilterLifeRemaini "VCRIGHT_HEPAAirFilterLifeRemaining";
BA_ "Confidence" SG_ 1803 VCRIGHT_leftPTCCompromisedRod 0;
BA_ "Confidence" SG_ 1803 VCRIGHT_rightPTCCompromisedRod 0;
BA_ "Confidence" SG_ 1803 VCRIGHT_hepaFilterHealthScore 0;
BA_ "Confidence" SG_ 1803 VCRIGHT_cabinFilterHealthScore 0;
BA_ "Confidence" SG_ 1803 VCRIGHT_cabinTempBreathLevelFOff 0;
BA_ "GenSigSNA" SG_ 1803 VCRIGHT_cabinTempBreathLevelFOff "255";
BA_ "Confidence" SG_ 1803 VCRIGHT_airDistributionModeAdjus 0;
BA_ "SystemSignalLongSymbol" SG_ 1803 VCRIGHT_airDistributionModeAdjus "VCRIGHT_airDistributionModeAdjustmentFactor";
BA_ "Confidence" SG_ 1803 VCRIGHT_hvacLHBleedEndStop 0;
BA_ "Confidence" SG_ 1803 VCRIGHT_hvacRHBleedEndStop 0;
BA_ "Confidence" SG_ 1803 VCRIGHT_hvacLHVaneEndStop 0;
BA_ "Confidence" SG_ 1803 VCRIGHT_hvacRHVaneEndStop 0;
BA_ "Confidence" SG_ 1803 VCRIGHT_hvacUpperModeEndStop 0;
BA_ "Confidence" SG_ 1803 VCRIGHT_hvacLowerModeEndStop 0;
BA_ "Confidence" SG_ 1803 VCRIGHT_hvacIntakeEndStop 0;
BA_ "Confidence" SG_ 1803 VCRIGHT_hvacLHBleedZeroStop 0;
BA_ "Confidence" SG_ 1803 VCRIGHT_hvacRHBleedZeroStop 0;
BA_ "Confidence" SG_ 1803 VCRIGHT_hvacLHVaneZeroStop 0;
BA_ "Confidence" SG_ 1803 VCRIGHT_hvacRHVaneZeroStop 0;
BA_ "Confidence" SG_ 1803 VCRIGHT_hvacUpperModeZeroStop 0;
BA_ "Confidence" SG_ 1803 VCRIGHT_hvacLowerModeZeroStop 0;
BA_ "Confidence" SG_ 1803 VCRIGHT_hvacIntakeZeroStop 0;
BA_ "Confidence" SG_ 1803 VCRIGHT_ambientTempLimp 0;
BA_ "GenSigSNA" SG_ 1803 VCRIGHT_ambientTempLimp "255";
BA_ "Confidence" SG_ 1803 VCRIGHT_cabinProbeTempLimp 0;
BA_ "GenSigSNA" SG_ 1803 VCRIGHT_cabinProbeTempLimp "255";
BA_ "Confidence" SG_ 1803 VCRIGHT_thsTempLimp 0;
BA_ "GenSigSNA" SG_ 1803 VCRIGHT_thsTempLimp "255";
BA_ "Confidence" SG_ 1803 VCRIGHT_thsCabinWaterMassLimp 0;
BA_ "Confidence" SG_ 1803 VCRIGHT_thsSolarIrradianceLimp 0;
BA_ "GenSigSNA" SG_ 1803 VCRIGHT_thsSolarIrradianceLimp "255";
BA_ "Confidence" SG_ 1803 VCRIGHT_silentWakeRecordCount 0;
BA_ "Confidence" SG_ 1803 VCRIGHT_evapCondensateMass 0;
BA_ "Confidence" SG_ 1803 VCRIGHT_airwaveRightLateralTotal 0;
BA_ "SystemSignalLongSymbol" SG_ 1803 VCRIGHT_airwaveRightLateralTotal "VCRIGHT_airwaveRightLateralTotalTravel";
BA_ "Confidence" SG_ 1803 VCRIGHT_airwaveLeftLateralTotalT 0;
BA_ "SystemSignalLongSymbol" SG_ 1803 VCRIGHT_airwaveLeftLateralTotalT "VCRIGHT_airwaveLeftLateralTotalTravel";
BA_ "Confidence" SG_ 611 VCRIGHT_logging10HzIndex 1;
BA_ "Confidence" SG_ 611 VCRIGHT_hvacLHBleedTarget 1;
BA_ "Confidence" SG_ 611 VCRIGHT_hvacRHBleedTarget 1;
BA_ "Confidence" SG_ 611 VCRIGHT_hvacLHVaneTarget 1;
BA_ "Confidence" SG_ 611 VCRIGHT_hvacRHVaneTarget 1;
BA_ "Confidence" SG_ 611 VCRIGHT_hvacUpperModeTarget 1;
BA_ "Confidence" SG_ 611 VCRIGHT_hvacLowerModeTarget 1;
BA_ "Confidence" SG_ 611 VCRIGHT_hvacIntakeTarget 1;
BA_ "Confidence" SG_ 611 VCRIGHT_hvacLHBleedPosition 1;
BA_ "Confidence" SG_ 611 VCRIGHT_hvacRHBleedPosition 1;
BA_ "Confidence" SG_ 611 VCRIGHT_hvacLHVanePosition 1;
BA_ "Confidence" SG_ 611 VCRIGHT_hvacRHVanePosition 1;
BA_ "Confidence" SG_ 611 VCRIGHT_hvacUpperModePosition 1;
BA_ "Confidence" SG_ 611 VCRIGHT_hvacLowerModePosition 1;
BA_ "Confidence" SG_ 611 VCRIGHT_hvacIntakePosition 1;
BA_ "Confidence" SG_ 611 VCRIGHT_hvacLHBleedActuatorState 0;
BA_ "Confidence" SG_ 611 VCRIGHT_hvacRHBleedActuatorState 0;
BA_ "Confidence" SG_ 611 VCRIGHT_hvacLHVaneActuatorState 0;
BA_ "Confidence" SG_ 611 VCRIGHT_hvacRHVaneActuatorState 0;
BA_ "Confidence" SG_ 611 VCRIGHT_hvacUpperModeActState 0;
BA_ "Confidence" SG_ 611 VCRIGHT_hvacLowerModeActState 0;
BA_ "Confidence" SG_ 611 VCRIGHT_hvacIntakeActuatorState 0;
BA_ "Confidence" SG_ 611 VCRIGHT_EvapPulldownBiasActive 0;
BA_ "Confidence" SG_ 611 VCRIGHT_tempDatLeftEst 0;
BA_ "GenSigSNA" SG_ 611 VCRIGHT_tempDatLeftEst "255";
BA_ "Confidence" SG_ 611 VCRIGHT_tempDatRightEst 0;
BA_ "GenSigSNA" SG_ 611 VCRIGHT_tempDatRightEst "255";
BA_ "Confidence" SG_ 611 VCRIGHT_tempDuctLeftEst 0;
BA_ "GenSigSNA" SG_ 611 VCRIGHT_tempDuctLeftEst "255";
BA_ "Confidence" SG_ 611 VCRIGHT_tempDuctRightEst 0;
BA_ "GenSigSNA" SG_ 611 VCRIGHT_tempDuctRightEst "255";
BA_ "Confidence" SG_ 611 VCRIGHT_ptcHeaterBadRodDetection 0;
BA_ "SystemSignalLongSymbol" SG_ 611 VCRIGHT_ptcHeaterBadRodDetection "VCRIGHT_ptcHeaterBadRodDetectionState";
BA_ "Confidence" SG_ 611 VCRIGHT_leftVerticalActuatorDuty 0;
BA_ "Confidence" SG_ 611 VCRIGHT_leftLateralActuatorDuty 0;
BA_ "Confidence" SG_ 611 VCRIGHT_rightVerticalActuatorDut 0;
BA_ "SystemSignalLongSymbol" SG_ 611 VCRIGHT_rightVerticalActuatorDut "VCRIGHT_rightVerticalActuatorDuty";
BA_ "Confidence" SG_ 611 VCRIGHT_rightLateralActuatorDuty 0;
BA_ "Confidence" SG_ 611 VCRIGHT_frontLeftSeatTempTargetQ 0;
BA_ "SystemSignalLongSymbol" SG_ 611 VCRIGHT_frontLeftSeatTempTargetQ "VCRIGHT_frontLeftSeatTempTargetQuasiSS";
BA_ "Confidence" SG_ 611 VCRIGHT_frontRightSeatTempTarget 0;
BA_ "SystemSignalLongSymbol" SG_ 611 VCRIGHT_frontRightSeatTempTarget "VCRIGHT_frontRightSeatTempTargetQuasiSS";
BA_ "Confidence" SG_ 691 VCRIGHT_logging1HzIndex 1;
BA_ "Confidence" SG_ 691 VCRIGHT_tempIncarCabinProbe 0;
BA_ "GenSigSNA" SG_ 691 VCRIGHT_tempIncarCabinProbe "255";
BA_ "Confidence" SG_ 691 VCRIGHT_tempIncarCabinDeep 1;
BA_ "GenSigSNA" SG_ 691 VCRIGHT_tempIncarCabinDeep "255";
BA_ "Confidence" SG_ 691 VCRIGHT_cabinTempInteriorL2 1;
BA_ "GenSigSNA" SG_ 691 VCRIGHT_cabinTempInteriorL2 "255";
BA_ "Confidence" SG_ 691 VCRIGHT_tempIncarCabinMid 0;
BA_ "GenSigSNA" SG_ 691 VCRIGHT_tempIncarCabinMid "250";
BA_ "Confidence" SG_ 691 VCRIGHT_cabinTempInteriorSunnyL2 1;
BA_ "GenSigSNA" SG_ 691 VCRIGHT_cabinTempInteriorSunnyL2 "255";
BA_ "Confidence" SG_ 691 VCRIGHT_cabinTempInteriorL3 1;
BA_ "GenSigSNA" SG_ 691 VCRIGHT_cabinTempInteriorL3 "255";
BA_ "Confidence" SG_ 691 VCRIGHT_cabinTempInteriorSunnyL3 1;
BA_ "GenSigSNA" SG_ 691 VCRIGHT_cabinTempInteriorSunnyL3 "255";
BA_ "Confidence" SG_ 691 VCRIGHT_cabinTempGlassRoof 0;
BA_ "GenSigSNA" SG_ 691 VCRIGHT_cabinTempGlassRoof "255";
BA_ "Confidence" SG_ 691 VCRIGHT_cabinTempWindshield 0;
BA_ "GenSigSNA" SG_ 691 VCRIGHT_cabinTempWindshield "255";
BA_ "Confidence" SG_ 691 VCRIGHT_cabinTempInterior 0;
BA_ "GenSigSNA" SG_ 691 VCRIGHT_cabinTempInterior "255";
BA_ "Confidence" SG_ 691 VCRIGHT_cabinTempInteriorSunny 0;
BA_ "GenSigSNA" SG_ 691 VCRIGHT_cabinTempInteriorSunny "255";
BA_ "Confidence" SG_ 691 VCRIGHT_cabinTempSideGlassLeft 0;
BA_ "GenSigSNA" SG_ 691 VCRIGHT_cabinTempSideGlassLeft "255";
BA_ "Confidence" SG_ 691 VCRIGHT_cabinTempSideGlassRight 0;
BA_ "GenSigSNA" SG_ 691 VCRIGHT_cabinTempSideGlassRight "255";
BA_ "Confidence" SG_ 691 VCRIGHT_cabinTempBreathLevel 0;
BA_ "GenSigSNA" SG_ 691 VCRIGHT_cabinTempBreathLevel "255";
BA_ "Confidence" SG_ 691 VCRIGHT_pcbaTemperature 0;
BA_ "Confidence" SG_ 691 VCRIGHT_wattsHeaterLeftTotal 0;
BA_ "Confidence" SG_ 691 VCRIGHT_wattsHeaterRightTotal 0;
BA_ "Confidence" SG_ 691 VCRIGHT_qdotLeftFFUnsat 0;
BA_ "Confidence" SG_ 691 VCRIGHT_qdotRightFFUnsat 0;
BA_ "Confidence" SG_ 691 VCRIGHT_nvhLevelDb 0;
BA_ "Confidence" SG_ 691 VCRIGHT_hvacSetTempActualLeft 0;
BA_ "Confidence" SG_ 691 VCRIGHT_hvacSetTempActualRight 0;
BA_ "Confidence" SG_ 691 VCRIGHT_hvacAutoTransitionReason 0;
BA_ "Confidence" SG_ 691 VCRIGHT_hvacMassflowTarget 0;
BA_ "Confidence" SG_ 691 VCRIGHT_hvacQdotLimitedLeft 0;
BA_ "Confidence" SG_ 691 VCRIGHT_hvacQdotLimitedRight 0;
BA_ "Confidence" SG_ 691 VCRIGHT_LHPanelAirflowBlocked 0;
BA_ "Confidence" SG_ 691 VCRIGHT_RHPanelAirflowBlocked 0;
BA_ "Confidence" SG_ 691 VCRIGHT_floorAirflowBlocked 0;
BA_ "Confidence" SG_ 691 VCRIGHT_defrostAirflowBlocked 0;
BA_ "Confidence" SG_ 691 VCRIGHT_hvacFilterLifeDetectActi 0;
BA_ "SystemSignalLongSymbol" SG_ 691 VCRIGHT_hvacFilterLifeDetectActi "VCRIGHT_hvacFilterLifeDetectActive";
BA_ "Confidence" SG_ 691 VCRIGHT_hvacLHBleedOperationMode 0;
BA_ "Confidence" SG_ 691 VCRIGHT_hvacRHBleedOperationMode 0;
BA_ "Confidence" SG_ 691 VCRIGHT_hvacLHVaneOperationMode 0;
BA_ "Confidence" SG_ 691 VCRIGHT_hvacRHVaneOperationMode 0;
BA_ "Confidence" SG_ 691 VCRIGHT_hvacUpperModeOpMode 0;
BA_ "Confidence" SG_ 691 VCRIGHT_hvacLowerModeOpMode 0;
BA_ "Confidence" SG_ 691 VCRIGHT_hvacIntakeOperationMode 0;
BA_ "Confidence" SG_ 691 VCRIGHT_isProbeFeedbackApplied 0;
BA_ "Confidence" SG_ 691 VCRIGHT_feedbackPullDownScalar 0;
BA_ "Confidence" SG_ 691 VCRIGHT_feedForwardPullDownScala 0;
BA_ "SystemSignalLongSymbol" SG_ 691 VCRIGHT_feedForwardPullDownScala "VCRIGHT_feedForwardPullDownScalar";
BA_ "Confidence" SG_ 691 VCRIGHT_convectionTargetLeft 0;
BA_ "GenSigSNA" SG_ 691 VCRIGHT_convectionTargetLeft "511";
BA_ "Confidence" SG_ 691 VCRIGHT_convectionTargetRight 0;
BA_ "GenSigSNA" SG_ 691 VCRIGHT_convectionTargetRight "511";
BA_ "Confidence" SG_ 691 VCRIGHT_convectionDeliveredLeft 0;
BA_ "GenSigSNA" SG_ 691 VCRIGHT_convectionDeliveredLeft "511";
BA_ "Confidence" SG_ 691 VCRIGHT_convectionDeliveredRight 0;
BA_ "GenSigSNA" SG_ 691 VCRIGHT_convectionDeliveredRight "511";
BA_ "Confidence" SG_ 691 VCRIGHT_solarLoadRightOccupant 0;
BA_ "GenSigSNA" SG_ 691 VCRIGHT_solarLoadRightOccupant "127";
BA_ "Confidence" SG_ 691 VCRIGHT_solarLoadLeftOccupant 0;
BA_ "GenSigSNA" SG_ 691 VCRIGHT_solarLoadLeftOccupant "127";
BA_ "Confidence" SG_ 691 VCRIGHT_ptcShutOutletMitigationA 0;
BA_ "SystemSignalLongSymbol" SG_ 691 VCRIGHT_ptcShutOutletMitigationA "VCRIGHT_ptcShutOutletMitigationActive";
BA_ "Confidence" SG_ 691 VCRIGHT_solarLoadFromThsTemp 0;
BA_ "GenSigSNA" SG_ 691 VCRIGHT_solarLoadFromThsTemp "255";
BA_ "Confidence" SG_ 691 VCRIGHT_ptcHeaterTempDuctHigh 1;
BA_ "Confidence" SG_ 691 VCRIGHT_ptcHeaterTempDuctFault 1;
BA_ "Confidence" SG_ 691 VCRIGHT_ptcHeaterNoAirflow 1;
BA_ "Confidence" SG_ 691 VCRIGHT_ptcHeaterHvacActNotReady 1;
BA_ "Confidence" SG_ 691 VCRIGHT_ptcHeaterNoUiRequest 1;
BA_ "Confidence" SG_ 691 VCRIGHT_ptcHeaterNoHighVoltage 1;
BA_ "Confidence" SG_ 691 VCRIGHT_ptcHeaterLAirPathBlocked 1;
BA_ "Confidence" SG_ 691 VCRIGHT_ptcHeaterRAirPathBlocked 1;
BA_ "Confidence" SG_ 691 VCRIGHT_ptcHeaterReqAirpathBlock 1;
BA_ "SystemSignalLongSymbol" SG_ 691 VCRIGHT_ptcHeaterReqAirpathBlock "VCRIGHT_ptcHeaterReqAirpathBlocked";
BA_ "Confidence" SG_ 691 VCRIGHT_hvacQdotFeedforward 1;
BA_ "Confidence" SG_ 691 VCRIGHT_evapLoadInFresh 1;
BA_ "Confidence" SG_ 691 VCRIGHT_evapLoadInRecirc 1;
BA_ "Confidence" SG_ 691 VCRIGHT_cabinTempWshldDefog 0;
BA_ "GenSigSNA" SG_ 691 VCRIGHT_cabinTempWshldDefog "255";
BA_ "Confidence" SG_ 691 VCRIGHT_cabinTempWshldDefogTop 0;
BA_ "GenSigSNA" SG_ 691 VCRIGHT_cabinTempWshldDefogTop "255";
BA_ "Confidence" SG_ 691 VCRIGHT_hvacLHBleedVoltage 0;
BA_ "Confidence" SG_ 691 VCRIGHT_hvacRHBleedVoltage 0;
BA_ "Confidence" SG_ 691 VCRIGHT_hvacLHVaneVoltage 0;
BA_ "Confidence" SG_ 691 VCRIGHT_hvacRHVaneVoltage 0;
BA_ "Confidence" SG_ 691 VCRIGHT_hvacUpperModeVoltage 0;
BA_ "Confidence" SG_ 691 VCRIGHT_hvacLowerModeVoltage 0;
BA_ "Confidence" SG_ 691 VCRIGHT_hvacIntakeVoltage 0;
BA_ "Confidence" SG_ 691 VCRIGHT_cabinTempBreathLevelFHea 1;
BA_ "GenSigSNA" SG_ 691 VCRIGHT_cabinTempBreathLevelFHea "255";
BA_ "SystemSignalLongSymbol" SG_ 691 VCRIGHT_cabinTempBreathLevelFHea "VCRIGHT_cabinTempBreathLevelFHeating";
BA_ "Confidence" SG_ 691 VCRIGHT_cabinTempBreathLevelFCoo 1;
BA_ "GenSigSNA" SG_ 691 VCRIGHT_cabinTempBreathLevelFCoo "255";
BA_ "SystemSignalLongSymbol" SG_ 691 VCRIGHT_cabinTempBreathLevelFCoo "VCRIGHT_cabinTempBreathLevelFCooling";
BA_ "Confidence" SG_ 691 VCRIGHT_cabinTempBreathLeve_0002 1;
BA_ "GenSigSNA" SG_ 691 VCRIGHT_cabinTempBreathLeve_0002 "255";
BA_ "SystemSignalLongSymbol" SG_ 691 VCRIGHT_cabinTempBreathLeve_0002 "VCRIGHT_cabinTempBreathLevelF5minHeating";
BA_ "Confidence" SG_ 691 VCRIGHT_cabinTempBreathLevelF5mi 1;
BA_ "GenSigSNA" SG_ 691 VCRIGHT_cabinTempBreathLevelF5mi "255";
BA_ "SystemSignalLongSymbol" SG_ 691 VCRIGHT_cabinTempBreathLevelF5mi "VCRIGHT_cabinTempBreathLevelF5minCooling";
BA_ "Confidence" SG_ 691 VCRIGHT_cabinTempBreathLeve_0001 1;
BA_ "GenSigSNA" SG_ 691 VCRIGHT_cabinTempBreathLeve_0001 "255";
BA_ "SystemSignalLongSymbol" SG_ 691 VCRIGHT_cabinTempBreathLeve_0001 "VCRIGHT_cabinTempBreathLevelF10minHeating";
BA_ "Confidence" SG_ 691 VCRIGHT_cabinTempBreathLevelF10m 1;
BA_ "GenSigSNA" SG_ 691 VCRIGHT_cabinTempBreathLevelF10m "255";
BA_ "SystemSignalLongSymbol" SG_ 691 VCRIGHT_cabinTempBreathLevelF10m "VCRIGHT_cabinTempBreathLevelF10minCooling";
BA_ "Confidence" SG_ 691 VCRIGHT_cabinTempInteriorFHeatin 1;
BA_ "GenSigSNA" SG_ 691 VCRIGHT_cabinTempInteriorFHeatin "255";
BA_ "SystemSignalLongSymbol" SG_ 691 VCRIGHT_cabinTempInteriorFHeatin "VCRIGHT_cabinTempInteriorFHeating";
BA_ "Confidence" SG_ 691 VCRIGHT_hvacCabOvrheatProtActive 0;
BA_ "Confidence" SG_ 691 VCRIGHT_hvacCabinPurgeAllowed 0;
BA_ "Confidence" SG_ 691 VCRIGHT_hvacCabOvrheatProtAllowe 0;
BA_ "SystemSignalLongSymbol" SG_ 691 VCRIGHT_hvacCabOvrheatProtAllowe "VCRIGHT_hvacCabOvrheatProtAllowed";
BA_ "Confidence" SG_ 691 VCRIGHT_filterLifeBlowerTorque 1;
BA_ "GenSigSNA" SG_ 691 VCRIGHT_filterLifeBlowerTorque "1023";
BA_ "Confidence" SG_ 691 VCRIGHT_cabinTempFanCurrent 0;
BA_ "Confidence" SG_ 691 VCRIGHT_cabinTempFanOutput 0;
BA_ "Confidence" SG_ 691 VCRIGHT_cloudinessEstimatedPct 0;
BA_ "Confidence" SG_ 691 VCRIGHT_solarLoadOnVehFiltered 0;
BA_ "GenSigSNA" SG_ 691 VCRIGHT_solarLoadOnVehFiltered "255";
BA_ "Confidence" SG_ 691 VCRIGHT_cabinTempProbeEstimate 0;
BA_ "GenSigSNA" SG_ 691 VCRIGHT_cabinTempProbeEstimate "255";
BA_ "Confidence" SG_ 691 VCRIGHT_cabinTempThs 0;
BA_ "GenSigSNA" SG_ 691 VCRIGHT_cabinTempThs "255";
BA_ "Confidence" SG_ 691 VCRIGHT_cabinTempThsBracket 0;
BA_ "GenSigSNA" SG_ 691 VCRIGHT_cabinTempThsBracket "255";
BA_ "Confidence" SG_ 691 VCRIGHT_leftHeatOvertempProtect 0;
BA_ "Confidence" SG_ 691 VCRIGHT_rightHeatOvertempProtect 0;
BA_ "Confidence" SG_ 691 VCRIGHT_CO2ppm 0;
BA_ "GenSigSNA" SG_ 691 VCRIGHT_CO2ppm "1023";
BA_ "Confidence" SG_ 691 VCRIGHT_timeLeftToCabinModelInit 0;
BA_ "Confidence" SG_ 691 VCRIGHT_hvacEstimateWindshieldRH 0;
BA_ "Confidence" SG_ 691 VCRIGHT_hvacFoggingRiskLevel 0;
BA_ "Confidence" SG_ 691 VCRIGHT_hvacCabinHumidityLevel 0;
BA_ "Confidence" SG_ 691 VCRIGHT_hvacFlashFoggingDetected 0;
BA_ "Confidence" SG_ 691 VCRIGHT_solarSensitivityInfr 0;
BA_ "Confidence" SG_ 691 VCRIGHT_solarSensitivityInfrCorr 0;
BA_ "Confidence" SG_ 691 VCRIGHT_lumbarCurrent 0;
BA_ "Confidence" SG_ 691 VCRIGHT_ocsCurrent 0;
BA_ "Confidence" SG_ 691 VCRIGHT_rcmCurrent 0;
BA_ "Confidence" SG_ 691 VCRIGHT_radioTunerCurrent 0;
BA_ "Confidence" SG_ 691 VCRIGHT_rearOilPumpCurrent 0;
BA_ "Confidence" SG_ 691 VCRIGHT_rearDefrostCurrent 0;
BA_ "Confidence" SG_ 691 VCRIGHT_tailLightCurrent 0;
BA_ "Confidence" SG_ 691 VCRIGHT_turnTailStopLightCurrent 0;
BA_ "Confidence" SG_ 691 VCRIGHT_reverseFogLightsCurrent 0;
BA_ "GenSigSNA" SG_ 691 VCRIGHT_reverseFogLightsCurrent "15";
BA_ "Confidence" SG_ 691 VCRIGHT_stopReverseTurnLightCurr 0;
BA_ "SystemSignalLongSymbol" SG_ 691 VCRIGHT_stopReverseTurnLightCurr "VCRIGHT_stopReverseTurnLightCurrent";
BA_ "Confidence" SG_ 691 VCRIGHT_sideMirrorCurrent 0;
BA_ "Confidence" SG_ 691 VCRIGHT_sideMirrorHeaterCurrent 0;
BA_ "GenSigSNA" SG_ 691 VCRIGHT_sideMirrorHeaterCurrent "31";
BA_ "Confidence" SG_ 691 VCRIGHT_frontSeatHeatCushionPwr 0;
BA_ "Confidence" SG_ 691 VCRIGHT_trunkInteriorLEDCurrent 0;
BA_ "GenSigSNA" SG_ 691 VCRIGHT_trunkInteriorLEDCurrent "15";
BA_ "Confidence" SG_ 691 VCRIGHT_mapPocketLEDsCurrent 0;
BA_ "GenSigSNA" SG_ 691 VCRIGHT_mapPocketLEDsCurrent "15";
BA_ "Confidence" SG_ 691 VCRIGHT_miscEFuseCurrent 0;
BA_ "GenSigSNA" SG_ 691 VCRIGHT_miscEFuseCurrent "31";
BA_ "Confidence" SG_ 691 VCRIGHT_interiorHandleLEDCurrent 0;
BA_ "Confidence" SG_ 691 VCRIGHT_miscInteriorLightsCurren 0;
BA_ "GenSigSNA" SG_ 691 VCRIGHT_miscInteriorLightsCurren "7";
BA_ "SystemSignalLongSymbol" SG_ 691 VCRIGHT_miscInteriorLightsCurren "VCRIGHT_miscInteriorLightsCurrent";
BA_ "Confidence" SG_ 691 VCRIGHT_frontPuddleLEDCurrent 0;
BA_ "GenSigSNA" SG_ 691 VCRIGHT_frontPuddleLEDCurrent "7";
BA_ "Confidence" SG_ 691 VCRIGHT_rearPuddleLEDCurrent 0;
BA_ "GenSigSNA" SG_ 691 VCRIGHT_rearPuddleLEDCurrent "7";
BA_ "Confidence" SG_ 691 VCRIGHT_liftgateShutfaceLEDCurre 0;
BA_ "GenSigSNA" SG_ 691 VCRIGHT_liftgateShutfaceLEDCurre "7";
BA_ "SystemSignalLongSymbol" SG_ 691 VCRIGHT_liftgateShutfaceLEDCurre "VCRIGHT_liftgateShutfaceLEDCurrent";
BA_ "Confidence" SG_ 691 VCRIGHT_3rSeatTOSCurrent 0;
BA_ "GenSigSNA" SG_ 691 VCRIGHT_3rSeatTOSCurrent "15";
BA_ "Confidence" SG_ 691 VCRIGHT_vbatFusedCurrent 0;
BA_ "GenSigSNA" SG_ 691 VCRIGHT_vbatFusedCurrent "15";
BA_ "Confidence" SG_ 691 VCRIGHT_cabinTempGlassGridHeater 0;
BA_ "GenSigSNA" SG_ 691 VCRIGHT_cabinTempGlassGridHeater "255";
BA_ "Confidence" SG_ 691 VCRIGHT_hvacAirflowReasonRight 0;
BA_ "Confidence" SG_ 691 VCRIGHT_hvacAirflowReasonLeft 0;
BA_ "Confidence" SG_ 691 VCRIGHT_hvacMassflowTargetLeft 0;
BA_ "Confidence" SG_ 691 VCRIGHT_hvacMassflowTargetRight 0;
BA_ "Confidence" SG_ 691 VCRIGHT_solarLoadLeftOccupantFil 0;
BA_ "GenSigSNA" SG_ 691 VCRIGHT_solarLoadLeftOccupantFil "127";
BA_ "SystemSignalLongSymbol" SG_ 691 VCRIGHT_solarLoadLeftOccupantFil "VCRIGHT_solarLoadLeftOccupantFilt";
BA_ "Confidence" SG_ 691 VCRIGHT_solarLoadRightOccupantFi 0;
BA_ "GenSigSNA" SG_ 691 VCRIGHT_solarLoadRightOccupantFi "127";
BA_ "SystemSignalLongSymbol" SG_ 691 VCRIGHT_solarLoadRightOccupantFi "VCRIGHT_solarLoadRightOccupantFilt";
BA_ "Confidence" SG_ 691 VCRIGHT_windshieldRHCapped 0;
BA_ "Confidence" SG_ 691 VCRIGHT_feedbackWarmUpScalar 0;
BA_ "Confidence" SG_ 691 VCRIGHT_maxMassflowScalarWarmUp 0;
BA_ "Confidence" SG_ 691 VCRIGHT_feedforwardWarmUpScalar 0;
BA_ "Confidence" SG_ 691 VCRIGHT_frontSeatHeatBackrestPwr 0;
BA_ "Confidence" SG_ 691 VCRIGHT_maxMassflowScalar 0;
BA_ "Confidence" SG_ 691 VCRIGHT_massflowTargetAutoInManu 0;
BA_ "SystemSignalLongSymbol" SG_ 691 VCRIGHT_massflowTargetAutoInManu "VCRIGHT_massflowTargetAutoInManualMode";
BA_ "Confidence" SG_ 691 VCRIGHT_airflowReasonAutoInManua 0;
BA_ "SystemSignalLongSymbol" SG_ 691 VCRIGHT_airflowReasonAutoInManua "VCRIGHT_airflowReasonAutoInManualMode";
BA_ "Confidence" SG_ 691 VCRIGHT_airflowReasonAutoIn_0001 0;
BA_ "SystemSignalLongSymbol" SG_ 691 VCRIGHT_airflowReasonAutoIn_0001 "VCRIGHT_airflowReasonAutoInManualModeLeft";
BA_ "Confidence" SG_ 691 VCRIGHT_airflowReasonAutoIn_0002 0;
BA_ "SystemSignalLongSymbol" SG_ 691 VCRIGHT_airflowReasonAutoIn_0002 "VCRIGHT_airflowReasonAutoInManualModeRight";
BA_ "Confidence" SG_ 691 VCRIGHT_cabinTempInteriorFCoolin 1;
BA_ "GenSigSNA" SG_ 691 VCRIGHT_cabinTempInteriorFCoolin "255";
BA_ "SystemSignalLongSymbol" SG_ 691 VCRIGHT_cabinTempInteriorFCoolin "VCRIGHT_cabinTempInteriorFCooling";
BA_ "Confidence" SG_ 691 VCRIGHT_averageDuctTempFHeating 1;
BA_ "GenSigSNA" SG_ 691 VCRIGHT_averageDuctTempFHeating "255";
BA_ "Confidence" SG_ 691 VCRIGHT_averageDuctTempFCooling 1;
BA_ "GenSigSNA" SG_ 691 VCRIGHT_averageDuctTempFCooling "255";
BA_ "Confidence" SG_ 691 VCRIGHT_hvacBiLevelWhsldRhEst 0;
BA_ "Confidence" SG_ 691 VCRIGHT_steeringWheelSurfaceTemp 0;
BA_ "GenSigSNA" SG_ 691 VCRIGHT_steeringWheelSurfaceTemp "1023";
BA_ "SystemSignalLongSymbol" SG_ 691 VCRIGHT_steeringWheelSurfaceTemp "VCRIGHT_steeringWheelSurfaceTempEst";
BA_ "Confidence" SG_ 691 VCRIGHT_steeringWheelSurfac_0001 0;
BA_ "GenSigSNA" SG_ 691 VCRIGHT_steeringWheelSurfac_0001 "1023";
BA_ "SystemSignalLongSymbol" SG_ 691 VCRIGHT_steeringWheelSurfac_0001 "VCRIGHT_steeringWheelSurfaceTempTgt";
BA_ "Confidence" SG_ 691 VCRIGHT_timeToComfortHeating 0;
BA_ "Confidence" SG_ 691 VCRIGHT_timeToComfortCooling 0;
BA_ "Confidence" SG_ 691 VCRIGHT_cabinWaterMassRaw 1;
BA_ "GenSigSNA" SG_ 691 VCRIGHT_cabinWaterMassRaw "255";
BA_ "Confidence" SG_ 691 VCRIGHT_massflowSingleZoneSplit 1;
BA_ "Confidence" SG_ 691 VCRIGHT_VOCPurgeState 1;
BA_ "Confidence" SG_ 691 VCRIGHT_cameraFoggingMonitorStat 1;
BA_ "SystemSignalLongSymbol" SG_ 691 VCRIGHT_cameraFoggingMonitorStat "VCRIGHT_cameraFoggingMonitorState";
BA_ "Confidence" SG_ 691 VCRIGHT_cabinOverheatProtectNotR 0;
BA_ "SystemSignalLongSymbol" SG_ 691 VCRIGHT_cabinOverheatProtectNotR "VCRIGHT_cabinOverheatProtectNotRunningReasonRaw";
BA_ "Confidence" SG_ 691 VCRIGHT_hvacIntakeReason 0;
BA_ "Confidence" SG_ 691 VCRIGHT_hvacCabinPurgeActive 0;
BA_ "Confidence" SG_ 691 VCRIGHT_solarAzimuthCarRef 0;
BA_ "GenSigSNA" SG_ 691 VCRIGHT_solarAzimuthCarRef "1025";
BA_ "Confidence" SG_ 691 VCRIGHT_massflowPulldownBias 0;
BA_ "Confidence" SG_ 691 VCRIGHT_evapPulldownBias 0;
BA_ "Confidence" SG_ 691 VCRIGHT_modeledMassflowFresh 0;
BA_ "Confidence" SG_ 691 VCRIGHT_modeledMassflowRecirc 0;
BA_ "Confidence" SG_ 691 VCRIGHT_hvacLimpModeStatus 0;
BA_ "Confidence" SG_ 691 VCRIGHT_hvacEstimatedCameraWinds 1;
BA_ "SystemSignalLongSymbol" SG_ 691 VCRIGHT_hvacEstimatedCameraWinds "VCRIGHT_hvacEstimatedCameraWindshieldRH";
BA_ "Confidence" SG_ 1862 VCRIGHT_frontOccupancyStatus 0;
BA_ "GenSigSNA" SG_ 1862 VCRIGHT_frontOccupancyStatus "7";
BA_ "Confidence" SG_ 1862 VCRIGHT_frontBuckleStatus 0;
BA_ "GenSigSNA" SG_ 1862 VCRIGHT_frontBuckleStatus "3";
BA_ "Confidence" SG_ 1862 VCRIGHT_rearCenterBuckleStatus 0;
BA_ "GenSigSNA" SG_ 1862 VCRIGHT_rearCenterBuckleStatus "3";
BA_ "Confidence" SG_ 1862 VCRIGHT_rearRightBuckleStatus 0;
BA_ "GenSigSNA" SG_ 1862 VCRIGHT_rearRightBuckleStatus "3";
BA_ "Confidence" SG_ 1862 VCRIGHT_rearRightOccupancyStatus 0;
BA_ "GenSigSNA" SG_ 1862 VCRIGHT_rearRightOccupancyStatus "3";
BA_ "Confidence" SG_ 1862 VCRIGHT_3RowLeftBuckleStatus 0;
BA_ "GenSigSNA" SG_ 1862 VCRIGHT_3RowLeftBuckleStatus "3";
BA_ "Confidence" SG_ 1862 VCRIGHT_3RowRightBuckleStatus 0;
BA_ "GenSigSNA" SG_ 1862 VCRIGHT_3RowRightBuckleStatus "3";
BA_ "Confidence" SG_ 1862 VCRIGHT_3RowLeftOccupancyStatus 0;
BA_ "GenSigSNA" SG_ 1862 VCRIGHT_3RowLeftOccupancyStatus "3";
BA_ "Confidence" SG_ 1862 VCRIGHT_3RowRightOccupancyStatus 0;
BA_ "GenSigSNA" SG_ 1862 VCRIGHT_3RowRightOccupancyStatus "3";
BA_ "Confidence" SG_ 1862 VCRIGHT_seatTrackPosition 0;
BA_ "GenSigSNA" SG_ 1862 VCRIGHT_seatTrackPosition "7";
BA_ "Confidence" SG_ 1862 VCRIGHT_occupantClassification 0;
BA_ "GenSigSNA" SG_ 1862 VCRIGHT_occupantClassification "7";
BA_ "Confidence" SG_ 1862 VCRIGHT_occupantClassificationQF 0;
BA_ "Confidence" SG_ 1862 VCRIGHT_classificationEnabled 0;
BA_ "Confidence" SG_ 1862 VCRIGHT_classificationEnabledQF 0;
BA_ "Confidence" SG_ 1862 VCRIGHT_restraintStatusCounter 0;
BA_ "Confidence" SG_ 1862 VCRIGHT_restraintStatusChecksum 0;
BA_ "Confidence" SG_ 1251 VCRIGHT_seatStatusIndex 1;
BA_ "Confidence" SG_ 1251 VCRIGHT_frontSeatTrackPos 0;
BA_ "Confidence" SG_ 1251 VCRIGHT_frontSeatTrackCurrent 0;
BA_ "Confidence" SG_ 1251 VCRIGHT_frontSeatTrackDuty 0;
BA_ "Confidence" SG_ 1251 VCRIGHT_frontSeatTrackState 0;
BA_ "Confidence" SG_ 1251 VCRIGHT_frontSeatTrackCalibrated 0;
BA_ "Confidence" SG_ 1251 VCRIGHT_frontSeatTrackLog 0;
BA_ "Confidence" SG_ 1251 VCRIGHT_frontSeatTrackBridgeSt 0;
BA_ "Confidence" SG_ 1251 VCRIGHT_frontSeatBackPos 0;
BA_ "Confidence" SG_ 1251 VCRIGHT_frontSeatBackCurrent 0;
BA_ "Confidence" SG_ 1251 VCRIGHT_frontSeatBackDuty 0;
BA_ "Confidence" SG_ 1251 VCRIGHT_frontSeatBackState 0;
BA_ "Confidence" SG_ 1251 VCRIGHT_frontSeatBackCalibrated 0;
BA_ "Confidence" SG_ 1251 VCRIGHT_frontSeatBackLog 0;
BA_ "Confidence" SG_ 1251 VCRIGHT_frontSeatBackBridgeSt 0;
BA_ "Confidence" SG_ 1251 VCRIGHT_frontSeatLiftPos 0;
BA_ "Confidence" SG_ 1251 VCRIGHT_frontSeatLiftCurrent 0;
BA_ "Confidence" SG_ 1251 VCRIGHT_frontSeatLiftDuty 0;
BA_ "Confidence" SG_ 1251 VCRIGHT_frontSeatLiftState 0;
BA_ "Confidence" SG_ 1251 VCRIGHT_frontSeatLiftCalibrated 0;
BA_ "Confidence" SG_ 1251 VCRIGHT_frontSeatLiftLog 0;
BA_ "Confidence" SG_ 1251 VCRIGHT_frontSeatLiftBridgeSt 0;
BA_ "Confidence" SG_ 1251 VCRIGHT_frontSeatTiltPos 0;
BA_ "Confidence" SG_ 1251 VCRIGHT_frontSeatTiltCurrent 0;
BA_ "Confidence" SG_ 1251 VCRIGHT_frontSeatTiltDuty 0;
BA_ "Confidence" SG_ 1251 VCRIGHT_frontSeatTiltState 0;
BA_ "Confidence" SG_ 1251 VCRIGHT_frontSeatTiltCalibrated 0;
BA_ "Confidence" SG_ 1251 VCRIGHT_frontSeatTiltLog 0;
BA_ "Confidence" SG_ 1251 VCRIGHT_frontSeatTiltBridgeSt 0;
BA_ "Confidence" SG_ 1251 VCRIGHT_lumbarAState 0;
BA_ "Confidence" SG_ 1251 VCRIGHT_lumbarBState 0;
BA_ "Confidence" SG_ 1251 VCRIGHT_lumbarAPressureHpa 0;
BA_ "Confidence" SG_ 1251 VCRIGHT_lumbarAPressureHpaFilt 0;
BA_ "Confidence" SG_ 1251 VCRIGHT_lumbarBPressureHpa 0;
BA_ "Confidence" SG_ 1251 VCRIGHT_lumbarBPressureHpaFilt 0;
BA_ "Confidence" SG_ 1251 VCRIGHT_lumbarActiveTooLongErr 0;
BA_ "Confidence" SG_ 1251 VCRIGHT_lumbarMaxPErr 0;
BA_ "Confidence" SG_ 1251 VCRIGHT_lumbarOvercurrentErr 0;
BA_ "Confidence" SG_ 1251 VCRIGHT_lumbarMaxOperatingPErr 0;
BA_ "Confidence" SG_ 1251 VCRIGHT_lumbarMinPErr 0;
BA_ "Confidence" SG_ 1251 VCRIGHT_lumbarGeneralErr 0;
BA_ "Confidence" SG_ 1251 VCRIGHT_lumbarDevMaxPumpPressA 0;
BA_ "Confidence" SG_ 1251 VCRIGHT_lumbarDevMaxPumpPressB 0;
BA_ "Confidence" SG_ 1251 VCRIGHT_frontSeatTrackPosReal 0;
BA_ "Confidence" SG_ 1251 VCRIGHT_frontSeatBackPosReal 0;
BA_ "Confidence" SG_ 1251 VCRIGHT_frontSeatLiftPosReal 0;
BA_ "Confidence" SG_ 1251 VCRIGHT_frontSeatTiltPosReal 0;
BA_ "Confidence" SG_ 1251 VCRIGHT_frontSeatTrackPosOffset 0;
BA_ "Confidence" SG_ 1251 VCRIGHT_frontSeatBackPosOffset 0;
BA_ "Confidence" SG_ 1251 VCRIGHT_frontSeatLiftPosOffset 0;
BA_ "Confidence" SG_ 1251 VCRIGHT_frontSeatTiltPosOffset 0;
BA_ "Confidence" SG_ 739 VCRIGHT_seatStatus2Index 1;
BA_ "Confidence" SG_ 739 VCRIGHT_frontSeatHeatCurrent 0;
BA_ "GenSigSNA" SG_ 739 VCRIGHT_frontSeatHeatCurrent "12";
BA_ "Confidence" SG_ 739 VCRIGHT_frontSeatHeatDuty 0;
BA_ "Confidence" SG_ 739 VCRIGHT_frontSeatHeatTmp 0;
BA_ "Confidence" SG_ 739 VCRIGHT_frontSeatHeatTmpTarget 0;
BA_ "Confidence" SG_ 739 VCRIGHT_frontSeatHeatInhibited 0;
BA_ "Confidence" SG_ 739 VCRIGHT_frontSeatHeatPowered 0;
BA_ "Confidence" SG_ 739 VCRIGHT_rearLSeatHeatCurrent 0;
BA_ "Confidence" SG_ 739 VCRIGHT_rearLSeatHeatDuty 0;
BA_ "Confidence" SG_ 739 VCRIGHT_rearLSeatHeatTmp 0;
BA_ "Confidence" SG_ 739 VCRIGHT_rearLSeatHeatTmpTarget 0;
BA_ "Confidence" SG_ 739 VCRIGHT_rearLSeatHeatInhibited 0;
BA_ "Confidence" SG_ 739 VCRIGHT_rearLSeatHeatPowered 0;
BA_ "Confidence" SG_ 739 VCRIGHT_rearCSeatHeatCurrent 0;
BA_ "Confidence" SG_ 739 VCRIGHT_rearCSeatHeatDuty 0;
BA_ "Confidence" SG_ 739 VCRIGHT_rearCSeatHeatTmp 0;
BA_ "Confidence" SG_ 739 VCRIGHT_rearCSeatHeatTmpTarget 0;
BA_ "Confidence" SG_ 739 VCRIGHT_rearCSeatHeatInhibited 0;
BA_ "Confidence" SG_ 739 VCRIGHT_rearCSeatHeatPowered 0;
BA_ "Confidence" SG_ 739 VCRIGHT_rearRSeatHeatCurrent 0;
BA_ "Confidence" SG_ 739 VCRIGHT_rearRSeatHeatDuty 0;
BA_ "Confidence" SG_ 739 VCRIGHT_rearRSeatHeatTmp 0;
BA_ "Confidence" SG_ 739 VCRIGHT_rearRSeatHeatTmpTarget 0;
BA_ "Confidence" SG_ 739 VCRIGHT_rearRSeatHeatInhibited 0;
BA_ "Confidence" SG_ 739 VCRIGHT_rearRSeatHeatPowered 0;
BA_ "Confidence" SG_ 739 VCRIGHT_2RowSeatReclineState 0;
BA_ "GenSigSNA" SG_ 739 VCRIGHT_2RowSeatReclineState "15";
BA_ "Confidence" SG_ 739 VCRIGHT_2RowSeatReclineDuty 0;
BA_ "Confidence" SG_ 739 VCRIGHT_2RowSeatReclineCurrent 0;
BA_ "Confidence" SG_ 739 VCRIGHT_2RowSeatReclineCalibrate 0;
BA_ "SystemSignalLongSymbol" SG_ 739 VCRIGHT_2RowSeatReclineCalibrate "VCRIGHT_2RowSeatReclineCalibrated";
BA_ "Confidence" SG_ 739 VCRIGHT_2RowSeatReclinePositionR 0;
BA_ "SystemSignalLongSymbol" SG_ 739 VCRIGHT_2RowSeatReclinePositionR "VCRIGHT_2RowSeatReclinePositionRaw";
BA_ "Confidence" SG_ 739 VCRIGHT_2RowSeatReclineAngle 0;
BA_ "Confidence" SG_ 739 VCRIGHT_2RowSeatReclineAbsPosSwi 0;
BA_ "GenSigSNA" SG_ 739 VCRIGHT_2RowSeatReclineAbsPosSwi "0";
BA_ "SystemSignalLongSymbol" SG_ 739 VCRIGHT_2RowSeatReclineAbsPosSwi "VCRIGHT_2RowSeatReclineAbsPosSwitchState";
BA_ "Confidence" SG_ 739 VCRIGHT_2RowSeatReclinePositionS 0;
BA_ "GenSigSNA" SG_ 739 VCRIGHT_2RowSeatReclinePositionS "4";
BA_ "SystemSignalLongSymbol" SG_ 739 VCRIGHT_2RowSeatReclinePositionS "VCRIGHT_2RowSeatReclinePositionState";
BA_ "Confidence" SG_ 739 VCRIGHT_2RowSeatReclineAdjustmen 0;
BA_ "SystemSignalLongSymbol" SG_ 739 VCRIGHT_2RowSeatReclineAdjustmen "VCRIGHT_2RowSeatReclineAdjustmentAllowed";
BA_ "Confidence" SG_ 739 VCRIGHT_2RowSeatReclineFoldAllow 0;
BA_ "SystemSignalLongSymbol" SG_ 739 VCRIGHT_2RowSeatReclineFoldAllow "VCRIGHT_2RowSeatReclineFoldAllowed";
BA_ "Confidence" SG_ 739 VCRIGHT_2RowSeatReclineUnfoldAll 0;
BA_ "SystemSignalLongSymbol" SG_ 739 VCRIGHT_2RowSeatReclineUnfoldAll "VCRIGHT_2RowSeatReclineUnfoldAllowed";
BA_ "Confidence" SG_ 739 VCRIGHT_2RowSeatReclineNextToggl 0;
BA_ "GenSigSNA" SG_ 739 VCRIGHT_2RowSeatReclineNextToggl "2";
BA_ "SystemSignalLongSymbol" SG_ 739 VCRIGHT_2RowSeatReclineNextToggl "VCRIGHT_2RowSeatReclineNextToggleDirection";
BA_ "Confidence" SG_ 739 VCRIGHT_2RowSeatReclineChoreoBlo 0;
BA_ "SystemSignalLongSymbol" SG_ 739 VCRIGHT_2RowSeatReclineChoreoBlo "VCRIGHT_2RowSeatReclineChoreoBlockedByOccupancy";
BA_ "Confidence" SG_ 739 VCRIGHT_2RowSeat1RClashAvoidance 0;
BA_ "SystemSignalLongSymbol" SG_ 739 VCRIGHT_2RowSeat1RClashAvoidance "VCRIGHT_2RowSeat1RClashAvoidanceBlockedReason";
BA_ "Confidence" SG_ 739 VCRIGHT_2RowSeat1RClashAvoi_0001 0;
BA_ "SystemSignalLongSymbol" SG_ 739 VCRIGHT_2RowSeat1RClashAvoi_0001 "VCRIGHT_2RowSeat1RClashAvoidanceState";
BA_ "Confidence" SG_ 739 VCRIGHT_2RowSeatReclineAbsP_0001 0;
BA_ "SystemSignalLongSymbol" SG_ 739 VCRIGHT_2RowSeatReclineAbsP_0001 "VCRIGHT_2RowSeatReclineAbsPosSwitchTransPoint";
BA_ "Confidence" SG_ 835 VCRIGHT_LVBatteryTypeDBG 0;
BA_ "Confidence" SG_ 835 VCRIGHT_rearDefrostState 0;
BA_ "GenSigSNA" SG_ 835 VCRIGHT_rearDefrostState "0";
BA_ "Confidence" SG_ 835 VCRIGHT_mirrorHeatState 0;
BA_ "GenSigSNA" SG_ 835 VCRIGHT_mirrorHeatState "0";
BA_ "Confidence" SG_ 835 VCRIGHT_OTAState 0;
BA_ "Confidence" SG_ 835 VCRIGHT_5AVoltage 0;
BA_ "Confidence" SG_ 835 VCRIGHT_vbatProt 0;
BA_ "Confidence" SG_ 835 VCRIGHT_rationalityAggregateCurr 0;
BA_ "SystemSignalLongSymbol" SG_ 835 VCRIGHT_rationalityAggregateCurr "VCRIGHT_rationalityAggregateCurrent";
BA_ "Confidence" SG_ 835 VCRIGHT_eFuseMgmtVoltageMonitor 0;
BA_ "Confidence" SG_ 835 VCRIGHT_isSteeringWheelHeaterReq 0;
BA_ "Confidence" SG_ 835 VCRIGHT_steeringWheelHeaterDCTgt 0;
BA_ "GenSigSNA" SG_ 835 VCRIGHT_steeringWheelHeaterDCTgt "127";
BA_ "Confidence" SG_ 963 VCRIGHT_switchStatusIndex 1;
BA_ "Confidence" SG_ 963 VCRIGHT_frontBuckleSwitch 1;
BA_ "Confidence" SG_ 963 VCRIGHT_rearCenterBuckleSwitch 1;
BA_ "Confidence" SG_ 963 VCRIGHT_rearRightBuckleSwitch 1;
BA_ "Confidence" SG_ 963 VCRIGHT_trunkExtReleasePressedPe 0;
BA_ "SystemSignalLongSymbol" SG_ 963 VCRIGHT_trunkExtReleasePressedPe "VCRIGHT_trunkExtReleasePressedPersist";
BA_ "Confidence" SG_ 963 VCRIGHT_frontSeatTrackBack 0;
BA_ "GenSigSNA" SG_ 963 VCRIGHT_frontSeatTrackBack "0";
BA_ "Confidence" SG_ 963 VCRIGHT_frontSeatTrackForward 0;
BA_ "GenSigSNA" SG_ 963 VCRIGHT_frontSeatTrackForward "0";
BA_ "Confidence" SG_ 963 VCRIGHT_frontSeatTiltDown 0;
BA_ "GenSigSNA" SG_ 963 VCRIGHT_frontSeatTiltDown "0";
BA_ "Confidence" SG_ 963 VCRIGHT_frontSeatTiltUp 0;
BA_ "GenSigSNA" SG_ 963 VCRIGHT_frontSeatTiltUp "0";
BA_ "Confidence" SG_ 963 VCRIGHT_frontSeatLiftDown 0;
BA_ "GenSigSNA" SG_ 963 VCRIGHT_frontSeatLiftDown "0";
BA_ "Confidence" SG_ 963 VCRIGHT_frontSeatLiftUp 0;
BA_ "GenSigSNA" SG_ 963 VCRIGHT_frontSeatLiftUp "0";
BA_ "Confidence" SG_ 963 VCRIGHT_frontSeatBackrestBack 0;
BA_ "GenSigSNA" SG_ 963 VCRIGHT_frontSeatBackrestBack "0";
BA_ "Confidence" SG_ 963 VCRIGHT_frontSeatBackrestForward 0;
BA_ "GenSigSNA" SG_ 963 VCRIGHT_frontSeatBackrestForward "0";
BA_ "Confidence" SG_ 963 VCRIGHT_frontSeatLumbarDown 0;
BA_ "GenSigSNA" SG_ 963 VCRIGHT_frontSeatLumbarDown "0";
BA_ "Confidence" SG_ 963 VCRIGHT_frontSeatLumbarUp 0;
BA_ "GenSigSNA" SG_ 963 VCRIGHT_frontSeatLumbarUp "0";
BA_ "Confidence" SG_ 963 VCRIGHT_frontSeatLumbarIn 0;
BA_ "GenSigSNA" SG_ 963 VCRIGHT_frontSeatLumbarIn "0";
BA_ "Confidence" SG_ 963 VCRIGHT_frontSeatLumbarOut 0;
BA_ "GenSigSNA" SG_ 963 VCRIGHT_frontSeatLumbarOut "0";
BA_ "Confidence" SG_ 963 VCRIGHT_2RowSeatReclineSwitch 0;
BA_ "Confidence" SG_ 963 VCRIGHT_2RowSeatBackrestFoldSwit 0;
BA_ "SystemSignalLongSymbol" SG_ 963 VCRIGHT_2RowSeatBackrestFoldSwit "VCRIGHT_2RowSeatBackrestFoldSwitch";
BA_ "Confidence" SG_ 963 VCRIGHT_frontHandlePWM 0;
BA_ "Confidence" SG_ 963 VCRIGHT_rearHandlePWM 0;
BA_ "Confidence" SG_ 963 VCRIGHT_gloveboxLightCurrent 0;
BA_ "Confidence" SG_ 963 VCRIGHT_frontSeatALR 0;
BA_ "GenSigSNA" SG_ 963 VCRIGHT_frontSeatALR "0";
BA_ "Confidence" SG_ 963 VCRIGHT_frontSeatResistiveOccupa 0;
BA_ "GenSigSNA" SG_ 963 VCRIGHT_frontSeatResistiveOccupa "0";
BA_ "SystemSignalLongSymbol" SG_ 963 VCRIGHT_frontSeatResistiveOccupa "VCRIGHT_frontSeatResistiveOccupancy";
BA_ "Confidence" SG_ 963 VCRIGHT_2RowSeatReclineSwitchpac 0;
BA_ "SystemSignalLongSymbol" SG_ 963 VCRIGHT_2RowSeatReclineSwitchpac "VCRIGHT_2RowSeatReclineSwitchpackState";
BA_ "Confidence" SG_ 1545 VCRIGHT_udsResponseData_H 1;
BA_ "Confidence" SG_ 1545 VCRIGHT_udsResponseData_L 1;
BA_ "Confidence" SG_ 953 VCSEC_IsoTpPipeODIN0 1;
BA_ "Confidence" SG_ 953 VCSEC_IsoTpPipeODIN1 1;
BA_ "Confidence" SG_ 953 VCSEC_IsoTpPipeODIN2 1;
BA_ "Confidence" SG_ 953 VCSEC_IsoTpPipeODIN3 1;
BA_ "Confidence" SG_ 953 VCSEC_IsoTpPipeODIN4 1;
BA_ "Confidence" SG_ 953 VCSEC_IsoTpPipeODIN5 1;
BA_ "Confidence" SG_ 953 VCSEC_IsoTpPipeODIN6 1;
BA_ "Confidence" SG_ 953 VCSEC_IsoTpPipeODIN7 1;
BA_ "Confidence" SG_ 537 VCSEC_TPMSDataIndex 1;
BA_ "Confidence" SG_ 537 VCSEC_TPMSCapabilityPressureInAd 0;
BA_ "SystemSignalLongSymbol" SG_ 537 VCSEC_TPMSCapabilityPressureInAd "VCSEC_TPMSCapabilityPressureInAdv0";
BA_ "Confidence" SG_ 537 VCSEC_TPMSCapabilityConfigurable 0;
BA_ "SystemSignalLongSymbol" SG_ 537 VCSEC_TPMSCapabilityConfigurable "VCSEC_TPMSCapabilityConfigurablePressure0";
BA_ "Confidence" SG_ 537 VCSEC_TPMSPressureRateOfChange0 0;
BA_ "Confidence" SG_ 537 VCSEC_TPMSPressure0 0;
BA_ "GenSigSNA" SG_ 537 VCSEC_TPMSPressure0 "511";
BA_ "Confidence" SG_ 537 VCSEC_TPMSTemperature0 0;
BA_ "GenSigSNA" SG_ 537 VCSEC_TPMSTemperature0 "255";
BA_ "Confidence" SG_ 537 VCSEC_TPMSBatVoltage0 0;
BA_ "GenSigSNA" SG_ 537 VCSEC_TPMSBatVoltage0 "255";
BA_ "Confidence" SG_ 537 VCSEC_TPMSLocation0 0;
BA_ "Confidence" SG_ 537 VCSEC_TPMSTemperatureCompensated 0;
BA_ "GenSigSNA" SG_ 537 VCSEC_TPMSTemperatureCompensated "511";
BA_ "SystemSignalLongSymbol" SG_ 537 VCSEC_TPMSTemperatureCompensated "VCSEC_TPMSTemperatureCompensatedPressure0";
BA_ "Confidence" SG_ 537 VCSEC_TPMSCapabilityPressur_0001 0;
BA_ "SystemSignalLongSymbol" SG_ 537 VCSEC_TPMSCapabilityPressur_0001 "VCSEC_TPMSCapabilityPressureInAdv1";
BA_ "Confidence" SG_ 537 VCSEC_TPMSCapabilityConfigu_0001 0;
BA_ "SystemSignalLongSymbol" SG_ 537 VCSEC_TPMSCapabilityConfigu_0001 "VCSEC_TPMSCapabilityConfigurablePressure1";
BA_ "Confidence" SG_ 537 VCSEC_TPMSPressureRateOfChange1 0;
BA_ "Confidence" SG_ 537 VCSEC_TPMSPressure1 0;
BA_ "GenSigSNA" SG_ 537 VCSEC_TPMSPressure1 "511";
BA_ "Confidence" SG_ 537 VCSEC_TPMSTemperature1 0;
BA_ "GenSigSNA" SG_ 537 VCSEC_TPMSTemperature1 "255";
BA_ "Confidence" SG_ 537 VCSEC_TPMSBatVoltage1 0;
BA_ "GenSigSNA" SG_ 537 VCSEC_TPMSBatVoltage1 "255";
BA_ "Confidence" SG_ 537 VCSEC_TPMSLocation1 0;
BA_ "Confidence" SG_ 537 VCSEC_TPMSTemperatureCompen_0001 0;
BA_ "GenSigSNA" SG_ 537 VCSEC_TPMSTemperatureCompen_0001 "511";
BA_ "SystemSignalLongSymbol" SG_ 537 VCSEC_TPMSTemperatureCompen_0001 "VCSEC_TPMSTemperatureCompensatedPressure1";
BA_ "Confidence" SG_ 537 VCSEC_TPMSCapabilityPressur_0002 0;
BA_ "SystemSignalLongSymbol" SG_ 537 VCSEC_TPMSCapabilityPressur_0002 "VCSEC_TPMSCapabilityPressureInAdv2";
BA_ "Confidence" SG_ 537 VCSEC_TPMSCapabilityConfigu_0002 0;
BA_ "SystemSignalLongSymbol" SG_ 537 VCSEC_TPMSCapabilityConfigu_0002 "VCSEC_TPMSCapabilityConfigurablePressure2";
BA_ "Confidence" SG_ 537 VCSEC_TPMSPressureRateOfChange2 0;
BA_ "Confidence" SG_ 537 VCSEC_TPMSPressure2 0;
BA_ "GenSigSNA" SG_ 537 VCSEC_TPMSPressure2 "511";
BA_ "Confidence" SG_ 537 VCSEC_TPMSTemperature2 0;
BA_ "GenSigSNA" SG_ 537 VCSEC_TPMSTemperature2 "255";
BA_ "Confidence" SG_ 537 VCSEC_TPMSBatVoltage2 0;
BA_ "GenSigSNA" SG_ 537 VCSEC_TPMSBatVoltage2 "255";
BA_ "Confidence" SG_ 537 VCSEC_TPMSLocation2 0;
BA_ "Confidence" SG_ 537 VCSEC_TPMSTemperatureCompen_0002 0;
BA_ "GenSigSNA" SG_ 537 VCSEC_TPMSTemperatureCompen_0002 "511";
BA_ "SystemSignalLongSymbol" SG_ 537 VCSEC_TPMSTemperatureCompen_0002 "VCSEC_TPMSTemperatureCompensatedPressure2";
BA_ "Confidence" SG_ 537 VCSEC_TPMSCapabilityPressur_0003 0;
BA_ "SystemSignalLongSymbol" SG_ 537 VCSEC_TPMSCapabilityPressur_0003 "VCSEC_TPMSCapabilityPressureInAdv3";
BA_ "Confidence" SG_ 537 VCSEC_TPMSCapabilityConfigu_0003 0;
BA_ "SystemSignalLongSymbol" SG_ 537 VCSEC_TPMSCapabilityConfigu_0003 "VCSEC_TPMSCapabilityConfigurablePressure3";
BA_ "Confidence" SG_ 537 VCSEC_TPMSPressureRateOfChange3 0;
BA_ "Confidence" SG_ 537 VCSEC_TPMSPressure3 0;
BA_ "GenSigSNA" SG_ 537 VCSEC_TPMSPressure3 "511";
BA_ "Confidence" SG_ 537 VCSEC_TPMSTemperature3 0;
BA_ "GenSigSNA" SG_ 537 VCSEC_TPMSTemperature3 "255";
BA_ "Confidence" SG_ 537 VCSEC_TPMSBatVoltage3 0;
BA_ "GenSigSNA" SG_ 537 VCSEC_TPMSBatVoltage3 "255";
BA_ "Confidence" SG_ 537 VCSEC_TPMSLocation3 0;
BA_ "Confidence" SG_ 537 VCSEC_TPMSTemperatureCompen_0003 0;
BA_ "GenSigSNA" SG_ 537 VCSEC_TPMSTemperatureCompen_0003 "511";
BA_ "SystemSignalLongSymbol" SG_ 537 VCSEC_TPMSTemperatureCompen_0003 "VCSEC_TPMSTemperatureCompensatedPressure3";
BA_ "Confidence" SG_ 537 VCSEC_TPMSRecommendedColdPressur 0;
BA_ "GenSigSNA" SG_ 537 VCSEC_TPMSRecommendedColdPressur "255";
BA_ "SystemSignalLongSymbol" SG_ 537 VCSEC_TPMSRecommendedColdPressur "VCSEC_TPMSRecommendedColdPressureFront";
BA_ "Confidence" SG_ 537 VCSEC_TPMSRecommendedColdPr_0001 0;
BA_ "GenSigSNA" SG_ 537 VCSEC_TPMSRecommendedColdPr_0001 "255";
BA_ "SystemSignalLongSymbol" SG_ 537 VCSEC_TPMSRecommendedColdPr_0001 "VCSEC_TPMSRecommendedColdPressureRear";
BA_ "Confidence" SG_ 537 VCSEC_TPMSFeature0 0;
BA_ "Confidence" SG_ 537 VCSEC_TPMSFeature1 0;
BA_ "Confidence" SG_ 537 VCSEC_TPMSFeature0Count 0;
BA_ "Confidence" SG_ 537 VCSEC_TPMSFeature0TimeS 0;
BA_ "Confidence" SG_ 570 VCSEC_TPMSStatusIndex 1;
BA_ "Confidence" SG_ 570 VCSEC_TPMSSystemState 1;
BA_ "Confidence" SG_ 570 VCSEC_TPMSSensorMACAddress0 0;
BA_ "Confidence" SG_ 570 VCSEC_TPMSSensorMACAddress1 0;
BA_ "Confidence" SG_ 570 VCSEC_TPMSSensorMACAddress2 0;
BA_ "Confidence" SG_ 570 VCSEC_TPMSSensorMACAddress3 0;
BA_ "Confidence" SG_ 570 VCSEC_BLESuccessfulConnEventCoun 1;
BA_ "SystemSignalLongSymbol" SG_ 570 VCSEC_BLESuccessfulConnEventCoun "VCSEC_BLESuccessfulConnEventCount0";
BA_ "Confidence" SG_ 570 VCSEC_BLEMissedConnEventCount0 1;
BA_ "Confidence" SG_ 570 VCSEC_BLECRCErrorConnEventCount0 1;
BA_ "Confidence" SG_ 570 VCSEC_BLEOtherFailuresCount0 1;
BA_ "Confidence" SG_ 570 VCSEC_BLEUnsuccessfulConnEventRa 1;
BA_ "GenSigSNA" SG_ 570 VCSEC_BLEUnsuccessfulConnEventRa "1023";
BA_ "SystemSignalLongSymbol" SG_ 570 VCSEC_BLEUnsuccessfulConnEventRa "VCSEC_BLEUnsuccessfulConnEventRate0";
BA_ "Confidence" SG_ 570 VCSEC_BLESuccessfulConnEven_0001 1;
BA_ "SystemSignalLongSymbol" SG_ 570 VCSEC_BLESuccessfulConnEven_0001 "VCSEC_BLESuccessfulConnEventCount1";
BA_ "Confidence" SG_ 570 VCSEC_BLEMissedConnEventCount1 1;
BA_ "Confidence" SG_ 570 VCSEC_BLECRCErrorConnEventCount1 1;
BA_ "Confidence" SG_ 570 VCSEC_BLEOtherFailuresCount1 1;
BA_ "Confidence" SG_ 570 VCSEC_BLEUnsuccessfulConnEv_0001 1;
BA_ "GenSigSNA" SG_ 570 VCSEC_BLEUnsuccessfulConnEv_0001 "1023";
BA_ "SystemSignalLongSymbol" SG_ 570 VCSEC_BLEUnsuccessfulConnEv_0001 "VCSEC_BLEUnsuccessfulConnEventRate1";
BA_ "Confidence" SG_ 570 VCSEC_BLESuccessfulConnEven_0002 1;
BA_ "SystemSignalLongSymbol" SG_ 570 VCSEC_BLESuccessfulConnEven_0002 "VCSEC_BLESuccessfulConnEventCount2";
BA_ "Confidence" SG_ 570 VCSEC_BLEMissedConnEventCount2 1;
BA_ "Confidence" SG_ 570 VCSEC_BLECRCErrorConnEventCount2 1;
BA_ "Confidence" SG_ 570 VCSEC_BLEOtherFailuresCount2 1;
BA_ "Confidence" SG_ 570 VCSEC_BLEUnsuccessfulConnEv_0002 1;
BA_ "GenSigSNA" SG_ 570 VCSEC_BLEUnsuccessfulConnEv_0002 "1023";
BA_ "SystemSignalLongSymbol" SG_ 570 VCSEC_BLEUnsuccessfulConnEv_0002 "VCSEC_BLEUnsuccessfulConnEventRate2";
BA_ "Confidence" SG_ 570 VCSEC_BLESuccessfulConnEven_0003 1;
BA_ "SystemSignalLongSymbol" SG_ 570 VCSEC_BLESuccessfulConnEven_0003 "VCSEC_BLESuccessfulConnEventCount3";
BA_ "Confidence" SG_ 570 VCSEC_BLEMissedConnEventCount3 1;
BA_ "Confidence" SG_ 570 VCSEC_BLECRCErrorConnEventCount3 1;
BA_ "Confidence" SG_ 570 VCSEC_BLEOtherFailuresCount3 1;
BA_ "Confidence" SG_ 570 VCSEC_BLEUnsuccessfulConnEv_0003 1;
BA_ "GenSigSNA" SG_ 570 VCSEC_BLEUnsuccessfulConnEv_0003 "1023";
BA_ "SystemSignalLongSymbol" SG_ 570 VCSEC_BLEUnsuccessfulConnEv_0003 "VCSEC_BLEUnsuccessfulConnEventRate3";
BA_ "Confidence" SG_ 570 VCSEC_TPMSSensorTIAppCRC0 0;
BA_ "GenSigSNA" SG_ 570 VCSEC_TPMSSensorTIAppCRC0 "0";
BA_ "Confidence" SG_ 570 VCSEC_TPMSSensorMLXAppCRC0 0;
BA_ "GenSigSNA" SG_ 570 VCSEC_TPMSSensorMLXAppCRC0 "0";
BA_ "Confidence" SG_ 570 VCSEC_TPMSSensorTIAppCRC1 0;
BA_ "GenSigSNA" SG_ 570 VCSEC_TPMSSensorTIAppCRC1 "0";
BA_ "Confidence" SG_ 570 VCSEC_TPMSSensorMLXAppCRC1 0;
BA_ "GenSigSNA" SG_ 570 VCSEC_TPMSSensorMLXAppCRC1 "0";
BA_ "Confidence" SG_ 570 VCSEC_TPMSSensorTIAppCRC2 0;
BA_ "GenSigSNA" SG_ 570 VCSEC_TPMSSensorTIAppCRC2 "0";
BA_ "Confidence" SG_ 570 VCSEC_TPMSSensorMLXAppCRC2 0;
BA_ "GenSigSNA" SG_ 570 VCSEC_TPMSSensorMLXAppCRC2 "0";
BA_ "Confidence" SG_ 570 VCSEC_TPMSSensorTIAppCRC3 0;
BA_ "GenSigSNA" SG_ 570 VCSEC_TPMSSensorTIAppCRC3 "0";
BA_ "Confidence" SG_ 570 VCSEC_TPMSSensorMLXAppCRC3 0;
BA_ "GenSigSNA" SG_ 570 VCSEC_TPMSSensorMLXAppCRC3 "0";
BA_ "Confidence" SG_ 570 VCSEC_TPMStotalAwakeTime0 0;
BA_ "Confidence" SG_ 570 VCSEC_TPMSTrimAdjusted0 0;
BA_ "Confidence" SG_ 570 VCSEC_TPMSGenealogySensorState0 0;
BA_ "Confidence" SG_ 570 VCSEC_TPMSSensorType0 0;
BA_ "Confidence" SG_ 570 VCSEC_TPMStotalAwakeTime1 0;
BA_ "Confidence" SG_ 570 VCSEC_TPMSTrimAdjusted1 0;
BA_ "Confidence" SG_ 570 VCSEC_TPMSGenealogySensorState1 0;
BA_ "Confidence" SG_ 570 VCSEC_TPMSSensorType1 0;
BA_ "Confidence" SG_ 570 VCSEC_TPMStotalAwakeTime2 0;
BA_ "Confidence" SG_ 570 VCSEC_TPMSTrimAdjusted2 0;
BA_ "Confidence" SG_ 570 VCSEC_TPMSGenealogySensorState2 0;
BA_ "Confidence" SG_ 570 VCSEC_TPMSSensorType2 0;
BA_ "Confidence" SG_ 570 VCSEC_TPMStotalAwakeTime3 0;
BA_ "Confidence" SG_ 570 VCSEC_TPMSTrimAdjusted3 0;
BA_ "Confidence" SG_ 570 VCSEC_TPMSGenealogySensorState3 0;
BA_ "Confidence" SG_ 570 VCSEC_TPMSSensorType3 0;
BA_ "Confidence" SG_ 1067 VCSEC_UWBEndpointIndex 1;
BA_ "Confidence" SG_ 1067 VCSEC_UWBRearRightDistance0 1;
BA_ "GenSigSNA" SG_ 1067 VCSEC_UWBRearRightDistance0 "4095";
BA_ "Confidence" SG_ 1067 VCSEC_UWBRearRightDistance1 1;
BA_ "GenSigSNA" SG_ 1067 VCSEC_UWBRearRightDistance1 "4095";
BA_ "Confidence" SG_ 1067 VCSEC_UWBRearRightDistance2 1;
BA_ "GenSigSNA" SG_ 1067 VCSEC_UWBRearRightDistance2 "4095";
BA_ "Confidence" SG_ 1067 VCSEC_UWBLeftDistance2 1;
BA_ "GenSigSNA" SG_ 1067 VCSEC_UWBLeftDistance2 "4095";
BA_ "Confidence" SG_ 1067 VCSEC_UWBRightDistance2 0;
BA_ "GenSigSNA" SG_ 1067 VCSEC_UWBRightDistance2 "4095";
BA_ "Confidence" SG_ 1067 VCSEC_UWBRearDistance2 0;
BA_ "GenSigSNA" SG_ 1067 VCSEC_UWBRearDistance2 "4095";
BA_ "Confidence" SG_ 1067 VCSEC_UWBRearLeftDistance2 0;
BA_ "GenSigSNA" SG_ 1067 VCSEC_UWBRearLeftDistance2 "4095";
BA_ "Confidence" SG_ 1067 VCSEC_UWBCenterDistance2 0;
BA_ "GenSigSNA" SG_ 1067 VCSEC_UWBCenterDistance2 "4095";
BA_ "Confidence" SG_ 1067 VCSEC_UWBLeftDistance1 1;
BA_ "GenSigSNA" SG_ 1067 VCSEC_UWBLeftDistance1 "4095";
BA_ "Confidence" SG_ 1067 VCSEC_UWBRightDistance1 0;
BA_ "GenSigSNA" SG_ 1067 VCSEC_UWBRightDistance1 "4095";
BA_ "Confidence" SG_ 1067 VCSEC_UWBRearDistance1 0;
BA_ "GenSigSNA" SG_ 1067 VCSEC_UWBRearDistance1 "4095";
BA_ "Confidence" SG_ 1067 VCSEC_UWBRearLeftDistance1 0;
BA_ "GenSigSNA" SG_ 1067 VCSEC_UWBRearLeftDistance1 "4095";
BA_ "Confidence" SG_ 1067 VCSEC_UWBCenterDistance1 0;
BA_ "GenSigSNA" SG_ 1067 VCSEC_UWBCenterDistance1 "4095";
BA_ "Confidence" SG_ 1067 VCSEC_UWBLeftDistance0 1;
BA_ "GenSigSNA" SG_ 1067 VCSEC_UWBLeftDistance0 "4095";
BA_ "Confidence" SG_ 1067 VCSEC_UWBRightDistance0 0;
BA_ "GenSigSNA" SG_ 1067 VCSEC_UWBRightDistance0 "4095";
BA_ "Confidence" SG_ 1067 VCSEC_UWBRearDistance0 0;
BA_ "GenSigSNA" SG_ 1067 VCSEC_UWBRearDistance0 "4095";
BA_ "Confidence" SG_ 1067 VCSEC_UWBRearLeftDistance0 0;
BA_ "GenSigSNA" SG_ 1067 VCSEC_UWBRearLeftDistance0 "4095";
BA_ "Confidence" SG_ 1067 VCSEC_UWBCenterDistance0 0;
BA_ "GenSigSNA" SG_ 1067 VCSEC_UWBCenterDistance0 "4095";
BA_ "Confidence" SG_ 761 VCSEC_activeKeyDebug 0;
BA_ "Confidence" SG_ 761 VCSEC_bleChannelDisconnected 0;
BA_ "Confidence" SG_ 761 VCSEC_bleDisconnectionReason 0;
BA_ "Confidence" SG_ 761 VCSEC_bleConnetionAttemptWLEntry 0;
BA_ "Confidence" SG_ 761 VCSEC_AdditionalAuthInfoIndex 1;
BA_ "Confidence" SG_ 761 VCSEC_unsecureNotificationStatus 1;
BA_ "Confidence" SG_ 761 VCSEC_activeKeyReason 0;
BA_ "Confidence" SG_ 761 VCSEC_activeKeySHA1 0;
BA_ "Confidence" SG_ 761 VCSEC_algoUsedForSummonRange0 0;
BA_ "Confidence" SG_ 761 VCSEC_keyWithinSummonRange0 0;
BA_ "Confidence" SG_ 761 VCSEC_algoUsedForSummonRange1 0;
BA_ "Confidence" SG_ 761 VCSEC_keyWithinSummonRange1 0;
BA_ "Confidence" SG_ 761 VCSEC_algoUsedForSummonRange2 0;
BA_ "Confidence" SG_ 761 VCSEC_keyWithinSummonRange2 0;
BA_ "Confidence" SG_ 761 VCSEC_BLEDeviceWithinSummonRange 0;
BA_ "SystemSignalLongSymbol" SG_ 761 VCSEC_WalkupUnlockMitigationKeyI "VCSEC_WalkupUnlockMitigationKeyIndex0";
BA_ "SystemSignalLongSymbol" SG_ 761 VCSEC_WalkupUnlockMitigatio_0003 "VCSEC_WalkupUnlockMitigationKeyIndex1";
BA_ "SystemSignalLongSymbol" SG_ 761 VCSEC_WalkupUnlockMitigatio_0004 "VCSEC_WalkupUnlockMitigationKeyIndex2";
BA_ "Confidence" SG_ 761 VCSEC_WalkupUnlockMitigationDesi 1;
BA_ "SystemSignalLongSymbol" SG_ 761 VCSEC_WalkupUnlockMitigationDesi "VCSEC_WalkupUnlockMitigationDesire0";
BA_ "Confidence" SG_ 761 VCSEC_WalkupUnlockMitigationReas 1;
BA_ "SystemSignalLongSymbol" SG_ 761 VCSEC_WalkupUnlockMitigationReas "VCSEC_WalkupUnlockMitigationReason0";
BA_ "Confidence" SG_ 761 VCSEC_WalkupUnlockMitigatio_0001 1;
BA_ "SystemSignalLongSymbol" SG_ 761 VCSEC_WalkupUnlockMitigatio_0001 "VCSEC_WalkupUnlockMitigationDesire1";
BA_ "Confidence" SG_ 761 VCSEC_WalkupUnlockMitigatio_0005 1;
BA_ "SystemSignalLongSymbol" SG_ 761 VCSEC_WalkupUnlockMitigatio_0005 "VCSEC_WalkupUnlockMitigationReason1";
BA_ "Confidence" SG_ 761 VCSEC_WalkupUnlockMitigatio_0002 1;
BA_ "SystemSignalLongSymbol" SG_ 761 VCSEC_WalkupUnlockMitigatio_0002 "VCSEC_WalkupUnlockMitigationDesire2";
BA_ "Confidence" SG_ 761 VCSEC_WalkupUnlockMitigatio_0006 1;
BA_ "SystemSignalLongSymbol" SG_ 761 VCSEC_WalkupUnlockMitigatio_0006 "VCSEC_WalkupUnlockMitigationReason2";
BA_ "Confidence" SG_ 761 VCSEC_NFCAuthFromBPillarFormFact 1;
BA_ "SystemSignalLongSymbol" SG_ 761 VCSEC_NFCAuthFromBPillarFormFact "VCSEC_NFCAuthFromBPillarFormFactor";
BA_ "Confidence" SG_ 761 VCSEC_NFCAuthFromCenterConsoleFo 1;
BA_ "SystemSignalLongSymbol" SG_ 761 VCSEC_NFCAuthFromCenterConsoleFo "VCSEC_NFCAuthFromCenterConsoleFormFactor";
VAL_ 1803 VCRIGHT_logging0point1HzIndex 8 "END" 7 "HVAC_3" 6 "HVAC_2" 5 "LIGHT_CURRENTS_2" 4 "HVAC_ACTUATOR_ZEROSTOP" 3 "HVAC_ACTUATOR_ENDSTOP" 2 "HVAC" 1 "LIGHT_CURRENTS_1" 0 "LIGHT_CURRENTS_0" ;
VAL_ 1803 VCRIGHT_leftPTCCompromisedRod 7 "CENTER_INNER" 6 "OUTER_CENTER" 5 "OUTER_INNER" 4 "OUTER" 3 "CENTER" 2 "INNER" 1 "ALL" 0 "NONE" ;
VAL_ 1803 VCRIGHT_rightPTCCompromisedRod 7 "CENTER_INNER" 6 "OUTER_CENTER" 5 "OUTER_INNER" 4 "OUTER" 3 "CENTER" 2 "INNER" 1 "ALL" 0 "NONE" ;
VAL_ 1803 VCRIGHT_cabinTempBreathLevelFOff 255 "SNA" ;
VAL_ 1803 VCRIGHT_ambientTempLimp 255 "SNA" ;
VAL_ 1803 VCRIGHT_cabinProbeTempLimp 255 "SNA" ;
VAL_ 1803 VCRIGHT_thsTempLimp 255 "SNA" ;
VAL_ 1803 VCRIGHT_thsSolarIrradianceLimp 255 "SNA" ;
VAL_ 611 VCRIGHT_logging10HzIndex 5 "END" 4 "HVAC_ACTUATOR_BRUSHED_DUTY" 3 "HVAC_ACTUATOR_BRUSHED" 2 "HVAC_ACTUATOR_STATE" 1 "HVAC_ACTUATOR_POSITIONS" 0 "HVAC_ACTUATOR_TARGETS" ;
VAL_ 611 VCRIGHT_hvacLHBleedActuatorState 2 "HVACACTUATOR_STATE_COASTING" 1 "HVACACTUATOR_STATE_RUNNING" 0 "HVACACTUATOR_STATE_BRAKING" ;
VAL_ 611 VCRIGHT_hvacRHBleedActuatorState 2 "HVACACTUATOR_STATE_COASTING" 1 "HVACACTUATOR_STATE_RUNNING" 0 "HVACACTUATOR_STATE_BRAKING" ;
VAL_ 611 VCRIGHT_hvacLHVaneActuatorState 2 "HVACACTUATOR_STATE_COASTING" 1 "HVACACTUATOR_STATE_RUNNING" 0 "HVACACTUATOR_STATE_BRAKING" ;
VAL_ 611 VCRIGHT_hvacRHVaneActuatorState 2 "HVACACTUATOR_STATE_COASTING" 1 "HVACACTUATOR_STATE_RUNNING" 0 "HVACACTUATOR_STATE_BRAKING" ;
VAL_ 611 VCRIGHT_hvacUpperModeActState 2 "HVACACTUATOR_STATE_COASTING" 1 "HVACACTUATOR_STATE_RUNNING" 0 "HVACACTUATOR_STATE_BRAKING" ;
VAL_ 611 VCRIGHT_hvacLowerModeActState 2 "HVACACTUATOR_STATE_COASTING" 1 "HVACACTUATOR_STATE_RUNNING" 0 "HVACACTUATOR_STATE_BRAKING" ;
VAL_ 611 VCRIGHT_hvacIntakeActuatorState 2 "HVACACTUATOR_STATE_COASTING" 1 "HVACACTUATOR_STATE_RUNNING" 0 "HVACACTUATOR_STATE_BRAKING" ;
VAL_ 611 VCRIGHT_tempDatLeftEst 255 "SNA" ;
VAL_ 611 VCRIGHT_tempDatRightEst 255 "SNA" ;
VAL_ 611 VCRIGHT_tempDuctLeftEst 255 "SNA" ;
VAL_ 611 VCRIGHT_tempDuctRightEst 255 "SNA" ;
VAL_ 611 VCRIGHT_ptcHeaterBadRodDetection 11 "UNAVAILABLE" 10 "CLEAR_FAULT_RESTART" 9 "CLEAR_FAULT" 8 "CHECK_RIGHT_INNER" 7 "CHECK_RIGHT_CENTER" 6 "CHECK_RIGHT_OUTER" 5 "CHECK_LEFT_INNER" 4 "CHECK_LEFT_CENTER" 3 "CHECK_LEFT_OUTER" 2 "DETECTED" 1 "IDLE" 0 "INIT" ;
VAL_ 611 VCRIGHT_frontLeftSeatTempTargetQ 0 "OFF" ;
VAL_ 611 VCRIGHT_frontRightSeatTempTarget 0 "OFF" ;
VAL_ 691 VCRIGHT_logging1HzIndex 17 "END" 16 "HVAC_MISCELLANEOUS_4" 15 "HVAC_MISCELLANEOUS_3" 14 "STEERING_WHEEL_HEAT" 13 "HVAC_COMFORT_SOLAR_3" 12 "HVAC_COMFORT_SOLAR_2" 11 "HSD_CURRENTS_2" 10 "HSD_CURRENTS_1" 9 "HVAC_MISCELLANEOUS_2" 8 "HVAC_MISCELLANEOUS_1" 7 "HVAC_TEMP_SENSORS_AND_ESTIMATES_3" 6 "HVAC_ACTUATOR_VOLTAGES" 5 "HEATER_AND_DUCT_TARGETS" 4 "HVAC_COMFORT_SOLAR" 3 "HVAC_STATUS_AIRFLOW" 2 "HVAC_HUMIDITY_HEATER_TEMP" 1 "HVAC_TEMP_SENSORS_AND_ESTIMATES_2" 0 "HVAC_TEMP_SENSORS_AND_ESTIMATES_1" ;
VAL_ 691 VCRIGHT_tempIncarCabinProbe 255 "SNA" ;
VAL_ 691 VCRIGHT_tempIncarCabinDeep 255 "SNA" ;
VAL_ 691 VCRIGHT_cabinTempInteriorL2 255 "SNA" ;
VAL_ 691 VCRIGHT_tempIncarCabinMid 250 "SNA" ;
VAL_ 691 VCRIGHT_cabinTempInteriorSunnyL2 255 "SNA" ;
VAL_ 691 VCRIGHT_cabinTempInteriorL3 255 "SNA" ;
VAL_ 691 VCRIGHT_cabinTempInteriorSunnyL3 255 "SNA" ;
VAL_ 691 VCRIGHT_cabinTempGlassRoof 255 "SNA" ;
VAL_ 691 VCRIGHT_cabinTempWindshield 255 "SNA" ;
VAL_ 691 VCRIGHT_cabinTempInterior 255 "SNA" ;
VAL_ 691 VCRIGHT_cabinTempInteriorSunny 255 "SNA" ;
VAL_ 691 VCRIGHT_cabinTempSideGlassLeft 255 "SNA" ;
VAL_ 691 VCRIGHT_cabinTempSideGlassRight 255 "SNA" ;
VAL_ 691 VCRIGHT_cabinTempBreathLevel 255 "SNA" ;
VAL_ 691 VCRIGHT_hvacAutoTransitionReason 23 "END" 22 "VOC_PURGE" 21 "RETURN_FROM_DEFOG_OVERRIDE" 20 "HVAC_AIR_HUMID" 19 "BIODEFENSE" 18 "DUCT_TARGETS_INVALID" 17 "HVAC_OFF" 16 "EVAP_OIL_PURGE" 15 "EVAP_DRYING" 14 "CABIN_PURGE" 13 "SET_TEMP_HI" 12 "SET_TEMP_LO" 11 "DEFOG_OVERRIDE" 10 "BI_LEVEL_LANDING" 9 "DUCTS_COLD" 8 "TEMP_TARGET_LOW" 7 "OCCUPANT_CONVECTION_REQUIREMENT" 6 "EXCESS_OCCUPANT_CONVECTION" 5 "TEMP_TARGET_ABOVE_THRESHOLD" 4 "TEMP_TARGET_BELOW_THRESHOLD" 3 "HUMIDITY_LOW" 2 "HUMIDITY_MODERATE" 1 "HUMIDITY_HIGH" 0 "NONE" ;
VAL_ 691 VCRIGHT_hvacLHBleedOperationMode 1 "HVACACTUATOR_OPERATION_MODE_CALIBRATION" 0 "HVACACTUATOR_OPERATION_MODE_NORMAL" ;
VAL_ 691 VCRIGHT_hvacRHBleedOperationMode 1 "HVACACTUATOR_OPERATION_MODE_CALIBRATION" 0 "HVACACTUATOR_OPERATION_MODE_NORMAL" ;
VAL_ 691 VCRIGHT_hvacLHVaneOperationMode 1 "HVACACTUATOR_OPERATION_MODE_CALIBRATION" 0 "HVACACTUATOR_OPERATION_MODE_NORMAL" ;
VAL_ 691 VCRIGHT_hvacRHVaneOperationMode 1 "HVACACTUATOR_OPERATION_MODE_CALIBRATION" 0 "HVACACTUATOR_OPERATION_MODE_NORMAL" ;
VAL_ 691 VCRIGHT_hvacUpperModeOpMode 1 "HVACACTUATOR_OPERATION_MODE_CALIBRATION" 0 "HVACACTUATOR_OPERATION_MODE_NORMAL" ;
VAL_ 691 VCRIGHT_hvacLowerModeOpMode 1 "HVACACTUATOR_OPERATION_MODE_CALIBRATION" 0 "HVACACTUATOR_OPERATION_MODE_NORMAL" ;
VAL_ 691 VCRIGHT_hvacIntakeOperationMode 1 "HVACACTUATOR_OPERATION_MODE_CALIBRATION" 0 "HVACACTUATOR_OPERATION_MODE_NORMAL" ;
VAL_ 691 VCRIGHT_isProbeFeedbackApplied 4 "NEGATIVEHIGH" 3 "POSITIVEHIGH" 2 "NEGATIVE" 1 "POSITIVE" 0 "OFF" ;
VAL_ 691 VCRIGHT_convectionTargetLeft 511 "SNA" ;
VAL_ 691 VCRIGHT_convectionTargetRight 511 "SNA" ;
VAL_ 691 VCRIGHT_convectionDeliveredLeft 511 "SNA" ;
VAL_ 691 VCRIGHT_convectionDeliveredRight 511 "SNA" ;
VAL_ 691 VCRIGHT_solarLoadRightOccupant 127 "SNA" ;
VAL_ 691 VCRIGHT_solarLoadLeftOccupant 127 "SNA" ;
VAL_ 691 VCRIGHT_solarLoadFromThsTemp 255 "SNA" ;
VAL_ 691 VCRIGHT_cabinTempWshldDefog 255 "SNA" ;
VAL_ 691 VCRIGHT_cabinTempWshldDefogTop 255 "SNA" ;
VAL_ 691 VCRIGHT_cabinTempBreathLevelFHea 255 "SNA" ;
VAL_ 691 VCRIGHT_cabinTempBreathLevelFCoo 255 "SNA" ;
VAL_ 691 VCRIGHT_cabinTempBreathLeve_0002 255 "SNA" ;
VAL_ 691 VCRIGHT_cabinTempBreathLevelF5mi 255 "SNA" ;
VAL_ 691 VCRIGHT_cabinTempBreathLeve_0001 255 "SNA" ;
VAL_ 691 VCRIGHT_cabinTempBreathLevelF10m 255 "SNA" ;
VAL_ 691 VCRIGHT_cabinTempInteriorFHeatin 255 "SNA" ;
VAL_ 691 VCRIGHT_filterLifeBlowerTorque 1023 "SNA" ;
VAL_ 691 VCRIGHT_solarLoadOnVehFiltered 255 "SNA" ;
VAL_ 691 VCRIGHT_cabinTempProbeEstimate 255 "SNA" ;
VAL_ 691 VCRIGHT_cabinTempThs 255 "SNA" ;
VAL_ 691 VCRIGHT_cabinTempThsBracket 255 "SNA" ;
VAL_ 691 VCRIGHT_CO2ppm 1023 "SNA" ;
VAL_ 691 VCRIGHT_reverseFogLightsCurrent 15 "SNA" ;
VAL_ 691 VCRIGHT_sideMirrorHeaterCurrent 31 "SNA" ;
VAL_ 691 VCRIGHT_trunkInteriorLEDCurrent 15 "SNA" ;
VAL_ 691 VCRIGHT_mapPocketLEDsCurrent 15 "SNA" ;
VAL_ 691 VCRIGHT_miscEFuseCurrent 31 "SNA" ;
VAL_ 691 VCRIGHT_miscInteriorLightsCurren 7 "SNA" ;
VAL_ 691 VCRIGHT_frontPuddleLEDCurrent 7 "SNA" ;
VAL_ 691 VCRIGHT_rearPuddleLEDCurrent 7 "SNA" ;
VAL_ 691 VCRIGHT_liftgateShutfaceLEDCurre 7 "SNA" ;
VAL_ 691 VCRIGHT_3rSeatTOSCurrent 15 "SNA" ;
VAL_ 691 VCRIGHT_vbatFusedCurrent 15 "SNA" ;
VAL_ 691 VCRIGHT_cabinTempGlassGridHeater 255 "SNA" ;
VAL_ 691 VCRIGHT_hvacAirflowReasonRight 21 "NONE" 20 "ODOR_ROUTINE" 19 "DRIVERLESS_SELF_TEST" 18 "VOC_PURGE" 17 "STRATIFICATION_TOP_PAD_AREA" 16 "HOT_DUCT_LOCKOUT" 15 "COLD_DUCT_LOCKOUT" 14 "BIOWEAPON_DEFENSE" 13 "EVAP_OIL_PURGE" 12 "EVAP_DRYING" 11 "SCREEN_PROTECTION" 10 "CABIN_OVERHEAT_PROTECT" 9 "CABIN_PURGE" 8 "OUTLET_TEMP_LIMIT" 7 "OCCUPANT_CONVECTION_REQUIREMENT" 6 "STRATIFICATION_INTERIOR_SURFACES" 5 "STRATIFICATION_GLASS_ROOF" 4 "MINIMUM_AUTO_AIRFLOW" 3 "CABIN_TEMPERATURE_CONTROL" 2 "UI_SHORTCUT" 1 "MANUAL_FAN_SPEED" 0 "HVAC_OFF" ;
VAL_ 691 VCRIGHT_hvacAirflowReasonLeft 21 "NONE" 20 "ODOR_ROUTINE" 19 "DRIVERLESS_SELF_TEST" 18 "VOC_PURGE" 17 "STRATIFICATION_TOP_PAD_AREA" 16 "HOT_DUCT_LOCKOUT" 15 "COLD_DUCT_LOCKOUT" 14 "BIOWEAPON_DEFENSE" 13 "EVAP_OIL_PURGE" 12 "EVAP_DRYING" 11 "SCREEN_PROTECTION" 10 "CABIN_OVERHEAT_PROTECT" 9 "CABIN_PURGE" 8 "OUTLET_TEMP_LIMIT" 7 "OCCUPANT_CONVECTION_REQUIREMENT" 6 "STRATIFICATION_INTERIOR_SURFACES" 5 "STRATIFICATION_GLASS_ROOF" 4 "MINIMUM_AUTO_AIRFLOW" 3 "CABIN_TEMPERATURE_CONTROL" 2 "UI_SHORTCUT" 1 "MANUAL_FAN_SPEED" 0 "HVAC_OFF" ;
VAL_ 691 VCRIGHT_solarLoadLeftOccupantFil 127 "SNA" ;
VAL_ 691 VCRIGHT_solarLoadRightOccupantFi 127 "SNA" ;
VAL_ 691 VCRIGHT_airflowReasonAutoInManua 21 "NONE" 20 "ODOR_ROUTINE" 19 "DRIVERLESS_SELF_TEST" 18 "VOC_PURGE" 17 "STRATIFICATION_TOP_PAD_AREA" 16 "HOT_DUCT_LOCKOUT" 15 "COLD_DUCT_LOCKOUT" 14 "BIOWEAPON_DEFENSE" 13 "EVAP_OIL_PURGE" 12 "EVAP_DRYING" 11 "SCREEN_PROTECTION" 10 "CABIN_OVERHEAT_PROTECT" 9 "CABIN_PURGE" 8 "OUTLET_TEMP_LIMIT" 7 "OCCUPANT_CONVECTION_REQUIREMENT" 6 "STRATIFICATION_INTERIOR_SURFACES" 5 "STRATIFICATION_GLASS_ROOF" 4 "MINIMUM_AUTO_AIRFLOW" 3 "CABIN_TEMPERATURE_CONTROL" 2 "UI_SHORTCUT" 1 "MANUAL_FAN_SPEED" 0 "HVAC_OFF" ;
VAL_ 691 VCRIGHT_airflowReasonAutoIn_0001 21 "NONE" 20 "ODOR_ROUTINE" 19 "DRIVERLESS_SELF_TEST" 18 "VOC_PURGE" 17 "STRATIFICATION_TOP_PAD_AREA" 16 "HOT_DUCT_LOCKOUT" 15 "COLD_DUCT_LOCKOUT" 14 "BIOWEAPON_DEFENSE" 13 "EVAP_OIL_PURGE" 12 "EVAP_DRYING" 11 "SCREEN_PROTECTION" 10 "CABIN_OVERHEAT_PROTECT" 9 "CABIN_PURGE" 8 "OUTLET_TEMP_LIMIT" 7 "OCCUPANT_CONVECTION_REQUIREMENT" 6 "STRATIFICATION_INTERIOR_SURFACES" 5 "STRATIFICATION_GLASS_ROOF" 4 "MINIMUM_AUTO_AIRFLOW" 3 "CABIN_TEMPERATURE_CONTROL" 2 "UI_SHORTCUT" 1 "MANUAL_FAN_SPEED" 0 "HVAC_OFF" ;
VAL_ 691 VCRIGHT_airflowReasonAutoIn_0002 21 "NONE" 20 "ODOR_ROUTINE" 19 "DRIVERLESS_SELF_TEST" 18 "VOC_PURGE" 17 "STRATIFICATION_TOP_PAD_AREA" 16 "HOT_DUCT_LOCKOUT" 15 "COLD_DUCT_LOCKOUT" 14 "BIOWEAPON_DEFENSE" 13 "EVAP_OIL_PURGE" 12 "EVAP_DRYING" 11 "SCREEN_PROTECTION" 10 "CABIN_OVERHEAT_PROTECT" 9 "CABIN_PURGE" 8 "OUTLET_TEMP_LIMIT" 7 "OCCUPANT_CONVECTION_REQUIREMENT" 6 "STRATIFICATION_INTERIOR_SURFACES" 5 "STRATIFICATION_GLASS_ROOF" 4 "MINIMUM_AUTO_AIRFLOW" 3 "CABIN_TEMPERATURE_CONTROL" 2 "UI_SHORTCUT" 1 "MANUAL_FAN_SPEED" 0 "HVAC_OFF" ;
VAL_ 691 VCRIGHT_cabinTempInteriorFCoolin 255 "SNA" ;
VAL_ 691 VCRIGHT_averageDuctTempFHeating 255 "SNA" ;
VAL_ 691 VCRIGHT_averageDuctTempFCooling 255 "SNA" ;
VAL_ 691 VCRIGHT_steeringWheelSurfaceTemp 1023 "SNA" ;
VAL_ 691 VCRIGHT_steeringWheelSurfac_0001 1023 "SNA" ;
VAL_ 691 VCRIGHT_timeToComfortHeating 63 "HVAC_OFF" 62 "UNATTAINABLE" 0 "IN_COMFORT_BAND" ;
VAL_ 691 VCRIGHT_timeToComfortCooling 63 "HVAC_OFF" 62 "UNATTAINABLE" 0 "IN_COMFORT_BAND" ;
VAL_ 691 VCRIGHT_cabinWaterMassRaw 255 "SNA" ;
VAL_ 691 VCRIGHT_VOCPurgeState 5 "PURGING_AND_DRYING" 4 "WAITING" 3 "PURGING" 2 "IDLE" 1 "INACTIVE" 0 "INIT" ;
VAL_ 691 VCRIGHT_cameraFoggingMonitorStat 6 "PRE_RUN_PURGE" 5 "IDLE" 4 "INACTIVE" 3 "RUNNING" 2 "WAKEUP" 1 "MONITORING" 0 "INIT" ;
VAL_ 691 VCRIGHT_hvacIntakeReason 26 "INTAKE_REASON_ODOR_ROUTINE" 25 "INTAKE_REASON_HVAC_OFF_IN_MOTION" 24 "INTAKE_REASON_LIFTGATE_CLOSING" 23 "INTAKE_REASON_DRIVERLESS_SELF_TEST" 22 "INTAKE_REASON_VOC_PURGE" 21 "INTAKE_REASON_STEAMING" 20 "INTAKE_REASON_PULLDOWN_IN_FRESH" 19 "INTAKE_REASON_RECIRC_NVH" 18 "INTAKE_REASON_CO2_PURGE" 17 "INTAKE_REASON_HVAC_OFF" 16 "INTAKE_REASON_PARK_POSITION" 15 "INTAKE_REASON_EVAP_DRYING" 14 "INTAKE_REASON_OIL_PURGE" 13 "INTAKE_REASON_CABIN_PURGE" 12 "INTAKE_REASON_COP" 11 "INTAKE_REASON_ENHANCED_FILTERATION" 10 "INTAKE_REASON_CHARGE_PORT_THAW" 9 "INTAKE_REASON_PRECON_OVERRIDE" 8 "INTAKE_REASON_HUMIDITY" 7 "INTAKE_REASON_BIO_WEAPON_STEADY" 6 "INTAKE_REASON_BIO_WEAPON_INIT" 5 "INTAKE_REASON_TEMPERATURE_CONTROL" 4 "INTAKE_REASON_MANUAL_RECIRC" 3 "INTAKE_REASON_MANUAL_FRESH" 2 "INTAKE_REASON_CAR_WASH" 1 "INTAKE_REASON_UDS" 0 "INTAKE_REASON_NONE" ;
VAL_ 691 VCRIGHT_solarAzimuthCarRef -1023 "SNA" ;
VAL_ 691 VCRIGHT_hvacLimpModeStatus 4 "LIMP_MODE_FAULTED" 3 "LIMP_MODE_ACTIVE" 2 "LIMP_MODE_READY" 1 "LIMP_MODE_WAITING_FOR_SENSORS" 0 "LIMP_MODE_NOT_NEEDED" ;
VAL_ 1862 VCRIGHT_frontOccupancyStatus 7 "SEAT_OCCUPANCY_SNA" 3 "SEAT_NOT_CONFIGURED" 2 "SEAT_OCCUPANCY_FAULTED" 1 "SEAT_OCCUPIED" 0 "SEAT_UNOCCUPIED" ;
VAL_ 1862 VCRIGHT_frontBuckleStatus 3 "SEAT_BELT_BUCKLE_NOT_CONFIGURED" 2 "SEAT_BELT_BUCKLE_STATUS_FAULTED" 1 "SEAT_BELT_BUCKLE_STATUS_LATCHED" 0 "SEAT_BELT_BUCKLE_STATUS_UNLATCHED" ;
VAL_ 1862 VCRIGHT_rearCenterBuckleStatus 3 "SEAT_BELT_BUCKLE_NOT_CONFIGURED" 2 "SEAT_BELT_BUCKLE_STATUS_FAULTED" 1 "SEAT_BELT_BUCKLE_STATUS_LATCHED" 0 "SEAT_BELT_BUCKLE_STATUS_UNLATCHED" ;
VAL_ 1862 VCRIGHT_rearRightBuckleStatus 3 "SEAT_BELT_BUCKLE_NOT_CONFIGURED" 2 "SEAT_BELT_BUCKLE_STATUS_FAULTED" 1 "SEAT_BELT_BUCKLE_STATUS_LATCHED" 0 "SEAT_BELT_BUCKLE_STATUS_UNLATCHED" ;
VAL_ 1862 VCRIGHT_rearRightOccupancyStatus 3 "SEAT_NOT_CONFIGURED" 2 "SEAT_OCCUPANCY_FAULTED" 1 "SEAT_OCCUPIED" 0 "SEAT_UNOCCUPIED" ;
VAL_ 1862 VCRIGHT_3RowLeftBuckleStatus 3 "SEAT_BELT_BUCKLE_NOT_CONFIGURED" 2 "SEAT_BELT_BUCKLE_STATUS_FAULTED" 1 "SEAT_BELT_BUCKLE_STATUS_LATCHED" 0 "SEAT_BELT_BUCKLE_STATUS_UNLATCHED" ;
VAL_ 1862 VCRIGHT_3RowRightBuckleStatus 3 "SEAT_BELT_BUCKLE_NOT_CONFIGURED" 2 "SEAT_BELT_BUCKLE_STATUS_FAULTED" 1 "SEAT_BELT_BUCKLE_STATUS_LATCHED" 0 "SEAT_BELT_BUCKLE_STATUS_UNLATCHED" ;
VAL_ 1862 VCRIGHT_3RowLeftOccupancyStatus 3 "SEAT_NOT_CONFIGURED" 2 "SEAT_OCCUPANCY_FAULTED" 1 "SEAT_OCCUPIED" 0 "SEAT_UNOCCUPIED" ;
VAL_ 1862 VCRIGHT_3RowRightOccupancyStatus 3 "SEAT_NOT_CONFIGURED" 2 "SEAT_OCCUPANCY_FAULTED" 1 "SEAT_OCCUPIED" 0 "SEAT_UNOCCUPIED" ;
VAL_ 1862 VCRIGHT_seatTrackPosition 7 "SEAT_TRACK_POSITION_SNA" 3 "SEAT_TRACK_POSITION_FAULTED" 2 "SEAT_TRACK_POSITION_NOT_CONFIGURED" 1 "SEAT_TRACK_POSITION_REARWARD" 0 "SEAT_TRACK_POSITION_FORWARD" ;
VAL_ 1862 VCRIGHT_occupantClassification 7 "SEAT_OCCUPANT_CLASSIFICATON_SNA" 6 "SEAT_OCCUPANT_CLASSIFICATON_OUT_OF_POSITION" 5 "SEAT_OCCUPANT_CLASSIFICATON_NOT_CONFIGURED" 4 "SEAT_OCCUPANT_CLASSIFICATON_INIT" 3 "SEAT_OCCUPANT_CLASSIFICATON_LARGE" 2 "SEAT_OCCUPANT_CLASSIFICATON_SMALL" 1 "SEAT_OCCUPANT_CLASSIFICATON_INHIBIT" 0 "SEAT_OCCUPANT_CLASSIFICATON_EMPTY" ;
VAL_ 1862 VCRIGHT_occupantClassificationQF 1 "SEAT_OCCUPANT_CLASSIFICATON_NOT_FAULTED" 0 "SEAT_OCCUPANT_CLASSIFICATON_FAULTED" ;
VAL_ 1862 VCRIGHT_classificationEnabled 1 "VCRIGHT_CLASSIFICATION_SOURCE" 0 "OCS1P_CLASSIFICATION_SOURCE" ;
VAL_ 1862 VCRIGHT_classificationEnabledQF 1 "CLASSIFICATION_ENABLED_NOT_FAULTED" 0 "CLASSIFICATION_ENABLED_FAULTED" ;
VAL_ 1251 VCRIGHT_seatStatusIndex 7 "RELATIVE_POSITION" 6 "OFFSETS" 5 "POSITION" 4 "LUMBAR" 3 "TILT" 2 "LIFT" 1 "BACK" 0 "TRACK" ;
VAL_ 1251 VCRIGHT_frontSeatTrackState 5 "SEAT_STATE_UNDEFINED" 4 "SEAT_STATE_CALIBRATING" 3 "SEAT_STATE_RECALLING" 2 "SEAT_STATE_MOVING_DOWN" 1 "SEAT_STATE_MOVING_UP" 0 "SEAT_STATE_STOPPED" ;
VAL_ 1251 VCRIGHT_frontSeatTrackBridgeSt 3 "IO_BRIDGE_STATE_COAST" 2 "IO_BRIDGE_STATE_BRAKE" 1 "IO_BRIDGE_STATE_ENABLED" 0 "IO_BRIDGE_STATE_DISABLED" ;
VAL_ 1251 VCRIGHT_frontSeatBackState 5 "SEAT_STATE_UNDEFINED" 4 "SEAT_STATE_CALIBRATING" 3 "SEAT_STATE_RECALLING" 2 "SEAT_STATE_MOVING_DOWN" 1 "SEAT_STATE_MOVING_UP" 0 "SEAT_STATE_STOPPED" ;
VAL_ 1251 VCRIGHT_frontSeatBackBridgeSt 3 "IO_BRIDGE_STATE_COAST" 2 "IO_BRIDGE_STATE_BRAKE" 1 "IO_BRIDGE_STATE_ENABLED" 0 "IO_BRIDGE_STATE_DISABLED" ;
VAL_ 1251 VCRIGHT_frontSeatLiftState 5 "SEAT_STATE_UNDEFINED" 4 "SEAT_STATE_CALIBRATING" 3 "SEAT_STATE_RECALLING" 2 "SEAT_STATE_MOVING_DOWN" 1 "SEAT_STATE_MOVING_UP" 0 "SEAT_STATE_STOPPED" ;
VAL_ 1251 VCRIGHT_frontSeatLiftBridgeSt 3 "IO_BRIDGE_STATE_COAST" 2 "IO_BRIDGE_STATE_BRAKE" 1 "IO_BRIDGE_STATE_ENABLED" 0 "IO_BRIDGE_STATE_DISABLED" ;
VAL_ 1251 VCRIGHT_frontSeatTiltState 5 "SEAT_STATE_UNDEFINED" 4 "SEAT_STATE_CALIBRATING" 3 "SEAT_STATE_RECALLING" 2 "SEAT_STATE_MOVING_DOWN" 1 "SEAT_STATE_MOVING_UP" 0 "SEAT_STATE_STOPPED" ;
VAL_ 1251 VCRIGHT_frontSeatTiltBridgeSt 3 "IO_BRIDGE_STATE_COAST" 2 "IO_BRIDGE_STATE_BRAKE" 1 "IO_BRIDGE_STATE_ENABLED" 0 "IO_BRIDGE_STATE_DISABLED" ;
VAL_ 1251 VCRIGHT_lumbarAState 5 "SEAT_STATE_UNDEFINED" 4 "SEAT_STATE_CALIBRATING" 3 "SEAT_STATE_RECALLING" 2 "SEAT_STATE_MOVING_DOWN" 1 "SEAT_STATE_MOVING_UP" 0 "SEAT_STATE_STOPPED" ;
VAL_ 1251 VCRIGHT_lumbarBState 5 "SEAT_STATE_UNDEFINED" 4 "SEAT_STATE_CALIBRATING" 3 "SEAT_STATE_RECALLING" 2 "SEAT_STATE_MOVING_DOWN" 1 "SEAT_STATE_MOVING_UP" 0 "SEAT_STATE_STOPPED" ;
VAL_ 739 VCRIGHT_seatStatus2Index 12 "SEAT_2ROW_ADJUSTABLE_FOLD_FLAT_2" 11 "SEAT_2ROW_ADJUSTABLE_FOLD_FLAT" 10 "OCS_IEE" 9 "SEAT_2ROW_EASY_ENTRY" 8 "SEAT_SWITCH_VOLTAGES_2" 7 "SEAT_SWITCH_VOLTAGES_1" 6 "SEAT_2ROW_ACTUATOR" 5 "SEAT_HEAT_REARR_BACKREST" 4 "OCCUPANCY" 3 "SEAT_HEAT_REARR" 2 "SEAT_HEAT_REARC" 1 "SEAT_HEAT_REARL_CUSHION" 0 "SEAT_HEAT_FRONT" ;
VAL_ 739 VCRIGHT_frontSeatHeatCurrent 12 "SNA" ;
VAL_ 739 VCRIGHT_2RowSeatReclineState 15 "SEAT_ADJUSTABLE_FOLD_FLAT_STATE_SNA" 12 "SEAT_ADJUSTABLE_FOLD_FLAT_STATE_CALIBRATING_ABSOLUTE_SENSOR" 11 "SEAT_ADJUSTABLE_FOLD_FLAT_STATE_CALIBRATING_ZERO_POSITION" 10 "SEAT_ADJUSTABLE_FOLD_FLAT_STATE_WAITING_TO_CLEAR_FOR_UNFOLD" 9 "SEAT_ADJUSTABLE_FOLD_FLAT_STATE_WAITING_TO_CLEAR_FOR_FOLD" 8 "SEAT_ADJUSTABLE_FOLD_FLAT_STATE_MOVING_REARWARD_TO_POSITION" 7 "SEAT_ADJUSTABLE_FOLD_FLAT_STATE_MOVING_FORWARD_TO_POSITION" 6 "SEAT_ADJUSTABLE_FOLD_FLAT_STATE_UNFOLDING" 5 "SEAT_ADJUSTABLE_FOLD_FLAT_STATE_FOLDING" 4 "SEAT_ADJUSTABLE_FOLD_FLAT_STATE_ADJUSTING_REARWARD_FAST" 3 "SEAT_ADJUSTABLE_FOLD_FLAT_STATE_ADJUSTING_FORWARD_FAST" 2 "SEAT_ADJUSTABLE_FOLD_FLAT_STATE_ADJUSTING_REARWARD_COMFORT" 1 "SEAT_ADJUSTABLE_FOLD_FLAT_STATE_ADJUSTING_FORWARD_COMFORT" 0 "SEAT_ADJUSTABLE_FOLD_FLAT_STATE_STOPPED" ;
VAL_ 739 VCRIGHT_2RowSeatReclineAbsPosSwi 3 "SWITCH_FAULT" 2 "SWITCH_ON" 1 "SWITCH_OFF" 0 "SWITCH_SNA" ;
VAL_ 739 VCRIGHT_2RowSeatReclinePositionS 4 "SEAT_ADJUSTABLE_FOLD_FLAT_POSITION_STATE_SNA" 3 "SEAT_ADJUSTABLE_FOLD_FLAT_POSITION_STATE_UNKNOWN" 2 "SEAT_ADJUSTABLE_FOLD_FLAT_POSITION_STATE_UNSAFE_INTERMEDIATE" 1 "SEAT_ADJUSTABLE_FOLD_FLAT_POSITION_STATE_UNFOLDED" 0 "SEAT_ADJUSTABLE_FOLD_FLAT_POSITION_STATE_FOLDED" ;
VAL_ 739 VCRIGHT_2RowSeatReclineNextToggl 2 "SEAT_ADJUSTABLE_FOLD_FLAT_NEXT_TOGGLE_DIRECTION_SNA" 1 "SEAT_ADJUSTABLE_FOLD_FLAT_NEXT_TOGGLE_DIRECTION_UNFOLD" 0 "SEAT_ADJUSTABLE_FOLD_FLAT_NEXT_TOGGLE_DIRECTION_FOLD" ;
VAL_ 739 VCRIGHT_2RowSeat1RClashAvoidance 6 "SEAT_FOLD_FLAT_CLASH_AVOIDANCE_REASON_FRONT_SEAT_OCCUPANCY" 5 "SEAT_FOLD_FLAT_CLASH_AVOIDANCE_REASON_FRONT_SEAT_MOVING" 4 "SEAT_FOLD_FLAT_CLASH_AVOIDANCE_REASON_FRONT_SEAT_PROFILE_RECALL" 3 "SEAT_FOLD_FLAT_CLASH_AVOIDANCE_REASON_REAR_SEAT_UNCALIBRATED" 2 "SEAT_FOLD_FLAT_CLASH_AVOIDANCE_REASON_FRONT_SEAT_UNCALIBRATED" 1 "SEAT_FOLD_FLAT_CLASH_AVOIDANCE_REASON_VEHICLE_IN_MOTION" 0 "SEAT_FOLD_FLAT_CLASH_AVOIDANCE_REASON_NONE" ;
VAL_ 739 VCRIGHT_2RowSeat1RClashAvoi_0001 3 "SEAT_FOLD_FLAT_CLASH_AVOIDANCE_STATE_RESTORING_FRONT_SEAT" 2 "SEAT_FOLD_FLAT_CLASH_AVOIDANCE_STATE_WAITING_TO_RESTORE_FRONT_SEAT" 1 "SEAT_FOLD_FLAT_CLASH_AVOIDANCE_STATE_FRONT_SEAT_CLEARING" 0 "SEAT_FOLD_FLAT_CLASH_AVOIDANCE_STATE_IDLE" ;
VAL_ 835 VCRIGHT_LVBatteryTypeDBG 5 "LV_BATTERY_TYPE_TESLA_48V_LI_ION" 4 "LV_BATTERY_TYPE_TESLA_16V_LI_ION" 3 "LV_BATTERY_TYPE_CATL_LI_ION" 2 "LV_BATTERY_TYPE_CLARIOS_B24_FLOODED" 1 "LV_BATTERY_TYPE_ATLASBX_B24_FLOODED" 0 "LV_BATTERY_TYPE_UNKNOWN" ;
VAL_ 835 VCRIGHT_rearDefrostState 4 "HEATER_STATE_FAULT" 3 "HEATER_STATE_OFF_UNAVAILABLE" 2 "HEATER_STATE_OFF" 1 "HEATER_STATE_ON" 0 "HEATER_STATE_SNA" ;
VAL_ 835 VCRIGHT_mirrorHeatState 4 "HEATER_STATE_FAULT" 3 "HEATER_STATE_OFF_UNAVAILABLE" 2 "HEATER_STATE_OFF" 1 "HEATER_STATE_ON" 0 "HEATER_STATE_SNA" ;
VAL_ 835 VCRIGHT_steeringWheelHeaterDCTgt 127 "SNA" ;
VAL_ 963 VCRIGHT_switchStatusIndex 1 "1" 0 "0" ;
VAL_ 963 VCRIGHT_frontBuckleSwitch 3 "SWITCH_FAULT" 2 "SWITCH_ON" 1 "SWITCH_OFF" 0 "SWITCH_SNA" ;
VAL_ 963 VCRIGHT_rearCenterBuckleSwitch 3 "SWITCH_FAULT" 2 "SWITCH_ON" 1 "SWITCH_OFF" 0 "SWITCH_SNA" ;
VAL_ 963 VCRIGHT_rearRightBuckleSwitch 3 "SWITCH_FAULT" 2 "SWITCH_ON" 1 "SWITCH_OFF" 0 "SWITCH_SNA" ;
VAL_ 963 VCRIGHT_frontSeatTrackBack 3 "SWITCH_FAULT" 2 "SWITCH_ON" 1 "SWITCH_OFF" 0 "SWITCH_SNA" ;
VAL_ 963 VCRIGHT_frontSeatTrackForward 3 "SWITCH_FAULT" 2 "SWITCH_ON" 1 "SWITCH_OFF" 0 "SWITCH_SNA" ;
VAL_ 963 VCRIGHT_frontSeatTiltDown 3 "SWITCH_FAULT" 2 "SWITCH_ON" 1 "SWITCH_OFF" 0 "SWITCH_SNA" ;
VAL_ 963 VCRIGHT_frontSeatTiltUp 3 "SWITCH_FAULT" 2 "SWITCH_ON" 1 "SWITCH_OFF" 0 "SWITCH_SNA" ;
VAL_ 963 VCRIGHT_frontSeatLiftDown 3 "SWITCH_FAULT" 2 "SWITCH_ON" 1 "SWITCH_OFF" 0 "SWITCH_SNA" ;
VAL_ 963 VCRIGHT_frontSeatLiftUp 3 "SWITCH_FAULT" 2 "SWITCH_ON" 1 "SWITCH_OFF" 0 "SWITCH_SNA" ;
VAL_ 963 VCRIGHT_frontSeatBackrestBack 3 "SWITCH_FAULT" 2 "SWITCH_ON" 1 "SWITCH_OFF" 0 "SWITCH_SNA" ;
VAL_ 963 VCRIGHT_frontSeatBackrestForward 3 "SWITCH_FAULT" 2 "SWITCH_ON" 1 "SWITCH_OFF" 0 "SWITCH_SNA" ;
VAL_ 963 VCRIGHT_frontSeatLumbarDown 3 "SWITCH_FAULT" 2 "SWITCH_ON" 1 "SWITCH_OFF" 0 "SWITCH_SNA" ;
VAL_ 963 VCRIGHT_frontSeatLumbarUp 3 "SWITCH_FAULT" 2 "SWITCH_ON" 1 "SWITCH_OFF" 0 "SWITCH_SNA" ;
VAL_ 963 VCRIGHT_frontSeatLumbarIn 3 "SWITCH_FAULT" 2 "SWITCH_ON" 1 "SWITCH_OFF" 0 "SWITCH_SNA" ;
VAL_ 963 VCRIGHT_frontSeatLumbarOut 3 "SWITCH_FAULT" 2 "SWITCH_ON" 1 "SWITCH_OFF" 0 "SWITCH_SNA" ;
VAL_ 963 VCRIGHT_frontSeatALR 3 "SWITCH_FAULT" 2 "SWITCH_ON" 1 "SWITCH_OFF" 0 "SWITCH_SNA" ;
VAL_ 963 VCRIGHT_frontSeatResistiveOccupa 3 "SWITCH_FAULT" 2 "SWITCH_ON" 1 "SWITCH_OFF" 0 "SWITCH_SNA" ;
VAL_ 963 VCRIGHT_2RowSeatReclineSwitchpac 6 "FAULT" 5 "REARWARD_FAST" 4 "REARWARD_SLOW" 3 "FORWARD_FAST" 2 "FORWARD_SLOW" 1 "INACTIVE" 0 "DISCONNECTED" ;
VAL_ 537 VCSEC_TPMSDataIndex 4 "RCP" 3 "Sensor3" 2 "Sensor2" 1 "Sensor1" 0 "Sensor0" ;
VAL_ 537 VCSEC_TPMSPressure0 511 "SNA" 510 "OVER_RANGE" ;
VAL_ 537 VCSEC_TPMSTemperature0 255 "SNA" ;
VAL_ 537 VCSEC_TPMSBatVoltage0 255 "SNA" ;
VAL_ 537 VCSEC_TPMSLocation0 4 "LOCATION_UNKNOWN" 3 "LOCATION_RR" 2 "LOCATION_RL" 1 "LOCATION_FR" 0 "LOCATION_FL" ;
VAL_ 537 VCSEC_TPMSTemperatureCompensated 511 "SNA" 510 "OVER_RANGE" ;
VAL_ 537 VCSEC_TPMSPressure1 511 "SNA" 510 "OVER_RANGE" ;
VAL_ 537 VCSEC_TPMSTemperature1 255 "SNA" ;
VAL_ 537 VCSEC_TPMSBatVoltage1 255 "SNA" ;
VAL_ 537 VCSEC_TPMSLocation1 4 "LOCATION_UNKNOWN" 3 "LOCATION_RR" 2 "LOCATION_RL" 1 "LOCATION_FR" 0 "LOCATION_FL" ;
VAL_ 537 VCSEC_TPMSTemperatureCompen_0001 511 "SNA" 510 "OVER_RANGE" ;
VAL_ 537 VCSEC_TPMSPressure2 511 "SNA" 510 "OVER_RANGE" ;
VAL_ 537 VCSEC_TPMSTemperature2 255 "SNA" ;
VAL_ 537 VCSEC_TPMSBatVoltage2 255 "SNA" ;
VAL_ 537 VCSEC_TPMSLocation2 4 "LOCATION_UNKNOWN" 3 "LOCATION_RR" 2 "LOCATION_RL" 1 "LOCATION_FR" 0 "LOCATION_FL" ;
VAL_ 537 VCSEC_TPMSTemperatureCompen_0002 511 "SNA" 510 "OVER_RANGE" ;
VAL_ 537 VCSEC_TPMSPressure3 511 "SNA" 510 "OVER_RANGE" ;
VAL_ 537 VCSEC_TPMSTemperature3 255 "SNA" ;
VAL_ 537 VCSEC_TPMSBatVoltage3 255 "SNA" ;
VAL_ 537 VCSEC_TPMSLocation3 4 "LOCATION_UNKNOWN" 3 "LOCATION_RR" 2 "LOCATION_RL" 1 "LOCATION_FR" 0 "LOCATION_FL" ;
VAL_ 537 VCSEC_TPMSTemperatureCompen_0003 511 "SNA" 510 "OVER_RANGE" ;
VAL_ 537 VCSEC_TPMSRecommendedColdPressur 255 "SNA" 254 "OVER_RANGE" ;
VAL_ 537 VCSEC_TPMSRecommendedColdPr_0001 255 "SNA" 254 "OVER_RANGE" ;
VAL_ 537 VCSEC_TPMSFeature0 6 "FEATURE_0_BLOCKED" 5 "FEATURE_0_ACTIVE" 4 "FEATURE_0_READY" 3 "FEATURE_0_WAIT_FOR_STATIONARY" 2 "FEATURE_0_UNAVAILABLE_2" 1 "FEATURE_0_UNAVAILABLE_1" 0 "FEATURE_0_NOT_SUPPORTED" ;
VAL_ 537 VCSEC_TPMSFeature1 5 "FEATURE_1_CLOSE" 4 "FEATURE_1_MEDIUM" 3 "FEATURE_1_FAR_AWAY" 2 "FEATURE_1_INCORRECT" 1 "FEATURE_1_REACHED" 0 "FEATURE_1_NONE" ;
VAL_ 570 VCSEC_TPMSStatusIndex 28 "SensorConfiguration" 27 "ResetCountsContinuedSensor3" 26 "ResetCountsSensor3" 25 "ResetCountsContinuedSensor2" 24 "ResetCountsSensor2" 23 "ResetCountsContinuedSensor1" 22 "ResetCountsSensor1" 21 "ResetCountsContinuedSensor0" 20 "ResetCountsSensor0" 19 "SleepStatsSensor3" 18 "SleepStatsSensor2" 17 "SleepStatsSensor1" 16 "SleepStatsSensor0" 15 "CPUTimeSensor3" 14 "CPUTimeSensor2" 13 "CPUTimeSensor1" 12 "CPUTimeSensor0" 11 "CRCSensor3" 10 "CRCSensor2" 9 "CRCSensor1" 8 "CRCSensor0" 7 "ConnMetricsSensor3" 6 "ConnMetricsSensor2" 5 "ConnMetricsSensor1" 4 "ConnMetricsSensor0" 3 "MACAddressSensor3" 2 "MACAddressSensor2" 1 "MACAddressSensor1" 0 "MACAddressSensor0" ;
VAL_ 570 VCSEC_TPMSSystemState 1 "TPMS_SYSTEM_STATE_ACTIVE" 0 "TPMS_SYSTEM_STATE_IDLE" ;
VAL_ 570 VCSEC_BLEUnsuccessfulConnEventRa 1023 "SNA" ;
VAL_ 570 VCSEC_BLEUnsuccessfulConnEv_0001 1023 "SNA" ;
VAL_ 570 VCSEC_BLEUnsuccessfulConnEv_0002 1023 "SNA" ;
VAL_ 570 VCSEC_BLEUnsuccessfulConnEv_0003 1023 "SNA" ;
VAL_ 570 VCSEC_TPMSSensorTIAppCRC0 0 "TPMS_CRC_SNA" ;
VAL_ 570 VCSEC_TPMSSensorMLXAppCRC0 0 "TPMS_CRC_SNA" ;
VAL_ 570 VCSEC_TPMSSensorTIAppCRC1 0 "TPMS_CRC_SNA" ;
VAL_ 570 VCSEC_TPMSSensorMLXAppCRC1 0 "TPMS_CRC_SNA" ;
VAL_ 570 VCSEC_TPMSSensorTIAppCRC2 0 "TPMS_CRC_SNA" ;
VAL_ 570 VCSEC_TPMSSensorMLXAppCRC2 0 "TPMS_CRC_SNA" ;
VAL_ 570 VCSEC_TPMSSensorTIAppCRC3 0 "TPMS_CRC_SNA" ;
VAL_ 570 VCSEC_TPMSSensorMLXAppCRC3 0 "TPMS_CRC_SNA" ;
VAL_ 570 VCSEC_TPMSGenealogySensorState0 7 "SENSOR_STATE_DONE" 6 "SENSOR_STATE_WAIT_FOR_CAPABILITIES_RESPONSE" 5 "SENSOR_STATE_SEND_CAPABILITIES_REQUEST" 4 "SENSOR_STATE_WAIT_FOR_GENEALOGY_RESPONSE" 3 "SENSOR_STATE_SEND_GENEALOGY_REQUEST" 2 "SENSOR_STATE_WAIT_FOR_CODE_DESCRIPTOR_RESPONSE" 1 "SENSOR_STATE_SEND_CODE_DESCRIPTOR_REQUEST" 0 "SENSOR_STATE_WAIT_FOR_CONNECTION" ;
VAL_ 570 VCSEC_TPMSSensorType0 6 "SENSOR_TYPE_V5" 5 "SENSOR_TYPE_V4" 4 "SENSOR_TYPE_V3" 3 "SENSOR_TYPE_V2" 2 "SENSOR_TYPE_V1" 1 "SENSOR_TYPE_UNKNOWN" 0 "SENSOR_TYPE_NOT_IDENTIFIED" ;
VAL_ 570 VCSEC_TPMSGenealogySensorState1 7 "SENSOR_STATE_DONE" 6 "SENSOR_STATE_WAIT_FOR_CAPABILITIES_RESPONSE" 5 "SENSOR_STATE_SEND_CAPABILITIES_REQUEST" 4 "SENSOR_STATE_WAIT_FOR_GENEALOGY_RESPONSE" 3 "SENSOR_STATE_SEND_GENEALOGY_REQUEST" 2 "SENSOR_STATE_WAIT_FOR_CODE_DESCRIPTOR_RESPONSE" 1 "SENSOR_STATE_SEND_CODE_DESCRIPTOR_REQUEST" 0 "SENSOR_STATE_WAIT_FOR_CONNECTION" ;
VAL_ 570 VCSEC_TPMSSensorType1 6 "SENSOR_TYPE_V5" 5 "SENSOR_TYPE_V4" 4 "SENSOR_TYPE_V3" 3 "SENSOR_TYPE_V2" 2 "SENSOR_TYPE_V1" 1 "SENSOR_TYPE_UNKNOWN" 0 "SENSOR_TYPE_NOT_IDENTIFIED" ;
VAL_ 570 VCSEC_TPMSGenealogySensorState2 7 "SENSOR_STATE_DONE" 6 "SENSOR_STATE_WAIT_FOR_CAPABILITIES_RESPONSE" 5 "SENSOR_STATE_SEND_CAPABILITIES_REQUEST" 4 "SENSOR_STATE_WAIT_FOR_GENEALOGY_RESPONSE" 3 "SENSOR_STATE_SEND_GENEALOGY_REQUEST" 2 "SENSOR_STATE_WAIT_FOR_CODE_DESCRIPTOR_RESPONSE" 1 "SENSOR_STATE_SEND_CODE_DESCRIPTOR_REQUEST" 0 "SENSOR_STATE_WAIT_FOR_CONNECTION" ;
VAL_ 570 VCSEC_TPMSSensorType2 6 "SENSOR_TYPE_V5" 5 "SENSOR_TYPE_V4" 4 "SENSOR_TYPE_V3" 3 "SENSOR_TYPE_V2" 2 "SENSOR_TYPE_V1" 1 "SENSOR_TYPE_UNKNOWN" 0 "SENSOR_TYPE_NOT_IDENTIFIED" ;
VAL_ 570 VCSEC_TPMSGenealogySensorState3 7 "SENSOR_STATE_DONE" 6 "SENSOR_STATE_WAIT_FOR_CAPABILITIES_RESPONSE" 5 "SENSOR_STATE_SEND_CAPABILITIES_REQUEST" 4 "SENSOR_STATE_WAIT_FOR_GENEALOGY_RESPONSE" 3 "SENSOR_STATE_SEND_GENEALOGY_REQUEST" 2 "SENSOR_STATE_WAIT_FOR_CODE_DESCRIPTOR_RESPONSE" 1 "SENSOR_STATE_SEND_CODE_DESCRIPTOR_REQUEST" 0 "SENSOR_STATE_WAIT_FOR_CONNECTION" ;
VAL_ 570 VCSEC_TPMSSensorType3 6 "SENSOR_TYPE_V5" 5 "SENSOR_TYPE_V4" 4 "SENSOR_TYPE_V3" 3 "SENSOR_TYPE_V2" 2 "SENSOR_TYPE_V1" 1 "SENSOR_TYPE_UNKNOWN" 0 "SENSOR_TYPE_NOT_IDENTIFIED" ;
VAL_ 1067 VCSEC_UWBEndpointIndex 3 "UWBDistance0" 2 "UWBDistance1" 1 "UWBDistance2" 0 "UWBRearRightDistance" ;
VAL_ 1067 VCSEC_UWBRearRightDistance0 4095 "SNA" 4094 "NOT_ENABLED" 4093 "INITIATOR_TIMEOUT" 4092 "RESPONDER_TIMEOUT" 4091 "INVALID_DISTANCE" 4090 "HCI_TIMEOUT" 4089 "RESPONDER_ERROR" 4088 "KEYFOB_DIDNT_RESPOND" 4087 "TX_FAILED" 4086 "RX_TIMEOUT" 4085 "PHY_DEC_FAILED" 4084 "TOA_FAILED" 4083 "STS_FAILED" 4082 "MAC_DEC_FAILED" 4081 "IE_DEC_FAILED" 4080 "IE_MISSING" ;
VAL_ 1067 VCSEC_UWBRearRightDistance1 4095 "SNA" 4094 "NOT_ENABLED" 4093 "INITIATOR_TIMEOUT" 4092 "RESPONDER_TIMEOUT" 4091 "INVALID_DISTANCE" 4090 "HCI_TIMEOUT" 4089 "RESPONDER_ERROR" 4088 "KEYFOB_DIDNT_RESPOND" 4087 "TX_FAILED" 4086 "RX_TIMEOUT" 4085 "PHY_DEC_FAILED" 4084 "TOA_FAILED" 4083 "STS_FAILED" 4082 "MAC_DEC_FAILED" 4081 "IE_DEC_FAILED" 4080 "IE_MISSING" ;
VAL_ 1067 VCSEC_UWBRearRightDistance2 4095 "SNA" 4094 "NOT_ENABLED" 4093 "INITIATOR_TIMEOUT" 4092 "RESPONDER_TIMEOUT" 4091 "INVALID_DISTANCE" 4090 "HCI_TIMEOUT" 4089 "RESPONDER_ERROR" 4088 "KEYFOB_DIDNT_RESPOND" 4087 "TX_FAILED" 4086 "RX_TIMEOUT" 4085 "PHY_DEC_FAILED" 4084 "TOA_FAILED" 4083 "STS_FAILED" 4082 "MAC_DEC_FAILED" 4081 "IE_DEC_FAILED" 4080 "IE_MISSING" ;
VAL_ 1067 VCSEC_UWBLeftDistance2 4095 "SNA" 4094 "NOT_ENABLED" 4093 "INITIATOR_TIMEOUT" 4092 "RESPONDER_TIMEOUT" 4091 "INVALID_DISTANCE" 4090 "HCI_TIMEOUT" 4089 "RESPONDER_ERROR" 4088 "KEYFOB_DIDNT_RESPOND" 4087 "TX_FAILED" 4086 "RX_TIMEOUT" 4085 "PHY_DEC_FAILED" 4084 "TOA_FAILED" 4083 "STS_FAILED" 4082 "MAC_DEC_FAILED" 4081 "IE_DEC_FAILED" 4080 "IE_MISSING" ;
VAL_ 1067 VCSEC_UWBRightDistance2 4095 "SNA" 4094 "NOT_ENABLED" 4093 "INITIATOR_TIMEOUT" 4092 "RESPONDER_TIMEOUT" 4091 "INVALID_DISTANCE" 4090 "HCI_TIMEOUT" 4089 "RESPONDER_ERROR" 4088 "KEYFOB_DIDNT_RESPOND" 4087 "TX_FAILED" 4086 "RX_TIMEOUT" 4085 "PHY_DEC_FAILED" 4084 "TOA_FAILED" 4083 "STS_FAILED" 4082 "MAC_DEC_FAILED" 4081 "IE_DEC_FAILED" 4080 "IE_MISSING" ;
VAL_ 1067 VCSEC_UWBRearDistance2 4095 "SNA" 4094 "NOT_ENABLED" 4093 "INITIATOR_TIMEOUT" 4092 "RESPONDER_TIMEOUT" 4091 "INVALID_DISTANCE" 4090 "HCI_TIMEOUT" 4089 "RESPONDER_ERROR" 4088 "KEYFOB_DIDNT_RESPOND" 4087 "TX_FAILED" 4086 "RX_TIMEOUT" 4085 "PHY_DEC_FAILED" 4084 "TOA_FAILED" 4083 "STS_FAILED" 4082 "MAC_DEC_FAILED" 4081 "IE_DEC_FAILED" 4080 "IE_MISSING" ;
VAL_ 1067 VCSEC_UWBRearLeftDistance2 4095 "SNA" 4094 "NOT_ENABLED" 4093 "INITIATOR_TIMEOUT" 4092 "RESPONDER_TIMEOUT" 4091 "INVALID_DISTANCE" 4090 "HCI_TIMEOUT" 4089 "RESPONDER_ERROR" 4088 "KEYFOB_DIDNT_RESPOND" 4087 "TX_FAILED" 4086 "RX_TIMEOUT" 4085 "PHY_DEC_FAILED" 4084 "TOA_FAILED" 4083 "STS_FAILED" 4082 "MAC_DEC_FAILED" 4081 "IE_DEC_FAILED" 4080 "IE_MISSING" ;
VAL_ 1067 VCSEC_UWBCenterDistance2 4095 "SNA" 4094 "NOT_ENABLED" 4093 "INITIATOR_TIMEOUT" 4092 "RESPONDER_TIMEOUT" 4091 "INVALID_DISTANCE" 4090 "HCI_TIMEOUT" 4089 "RESPONDER_ERROR" 4088 "KEYFOB_DIDNT_RESPOND" 4087 "TX_FAILED" 4086 "RX_TIMEOUT" 4085 "PHY_DEC_FAILED" 4084 "TOA_FAILED" 4083 "STS_FAILED" 4082 "MAC_DEC_FAILED" 4081 "IE_DEC_FAILED" 4080 "IE_MISSING" ;
VAL_ 1067 VCSEC_UWBLeftDistance1 4095 "SNA" 4094 "NOT_ENABLED" 4093 "INITIATOR_TIMEOUT" 4092 "RESPONDER_TIMEOUT" 4091 "INVALID_DISTANCE" 4090 "HCI_TIMEOUT" 4089 "RESPONDER_ERROR" 4088 "KEYFOB_DIDNT_RESPOND" 4087 "TX_FAILED" 4086 "RX_TIMEOUT" 4085 "PHY_DEC_FAILED" 4084 "TOA_FAILED" 4083 "STS_FAILED" 4082 "MAC_DEC_FAILED" 4081 "IE_DEC_FAILED" 4080 "IE_MISSING" ;
VAL_ 1067 VCSEC_UWBRightDistance1 4095 "SNA" 4094 "NOT_ENABLED" 4093 "INITIATOR_TIMEOUT" 4092 "RESPONDER_TIMEOUT" 4091 "INVALID_DISTANCE" 4090 "HCI_TIMEOUT" 4089 "RESPONDER_ERROR" 4088 "KEYFOB_DIDNT_RESPOND" 4087 "TX_FAILED" 4086 "RX_TIMEOUT" 4085 "PHY_DEC_FAILED" 4084 "TOA_FAILED" 4083 "STS_FAILED" 4082 "MAC_DEC_FAILED" 4081 "IE_DEC_FAILED" 4080 "IE_MISSING" ;
VAL_ 1067 VCSEC_UWBRearDistance1 4095 "SNA" 4094 "NOT_ENABLED" 4093 "INITIATOR_TIMEOUT" 4092 "RESPONDER_TIMEOUT" 4091 "INVALID_DISTANCE" 4090 "HCI_TIMEOUT" 4089 "RESPONDER_ERROR" 4088 "KEYFOB_DIDNT_RESPOND" 4087 "TX_FAILED" 4086 "RX_TIMEOUT" 4085 "PHY_DEC_FAILED" 4084 "TOA_FAILED" 4083 "STS_FAILED" 4082 "MAC_DEC_FAILED" 4081 "IE_DEC_FAILED" 4080 "IE_MISSING" ;
VAL_ 1067 VCSEC_UWBRearLeftDistance1 4095 "SNA" 4094 "NOT_ENABLED" 4093 "INITIATOR_TIMEOUT" 4092 "RESPONDER_TIMEOUT" 4091 "INVALID_DISTANCE" 4090 "HCI_TIMEOUT" 4089 "RESPONDER_ERROR" 4088 "KEYFOB_DIDNT_RESPOND" 4087 "TX_FAILED" 4086 "RX_TIMEOUT" 4085 "PHY_DEC_FAILED" 4084 "TOA_FAILED" 4083 "STS_FAILED" 4082 "MAC_DEC_FAILED" 4081 "IE_DEC_FAILED" 4080 "IE_MISSING" ;
VAL_ 1067 VCSEC_UWBCenterDistance1 4095 "SNA" 4094 "NOT_ENABLED" 4093 "INITIATOR_TIMEOUT" 4092 "RESPONDER_TIMEOUT" 4091 "INVALID_DISTANCE" 4090 "HCI_TIMEOUT" 4089 "RESPONDER_ERROR" 4088 "KEYFOB_DIDNT_RESPOND" 4087 "TX_FAILED" 4086 "RX_TIMEOUT" 4085 "PHY_DEC_FAILED" 4084 "TOA_FAILED" 4083 "STS_FAILED" 4082 "MAC_DEC_FAILED" 4081 "IE_DEC_FAILED" 4080 "IE_MISSING" ;
VAL_ 1067 VCSEC_UWBLeftDistance0 4095 "SNA" 4094 "NOT_ENABLED" 4093 "INITIATOR_TIMEOUT" 4092 "RESPONDER_TIMEOUT" 4091 "INVALID_DISTANCE" 4090 "HCI_TIMEOUT" 4089 "RESPONDER_ERROR" 4088 "KEYFOB_DIDNT_RESPOND" 4087 "TX_FAILED" 4086 "RX_TIMEOUT" 4085 "PHY_DEC_FAILED" 4084 "TOA_FAILED" 4083 "STS_FAILED" 4082 "MAC_DEC_FAILED" 4081 "IE_DEC_FAILED" 4080 "IE_MISSING" ;
VAL_ 1067 VCSEC_UWBRightDistance0 4095 "SNA" 4094 "NOT_ENABLED" 4093 "INITIATOR_TIMEOUT" 4092 "RESPONDER_TIMEOUT" 4091 "INVALID_DISTANCE" 4090 "HCI_TIMEOUT" 4089 "RESPONDER_ERROR" 4088 "KEYFOB_DIDNT_RESPOND" 4087 "TX_FAILED" 4086 "RX_TIMEOUT" 4085 "PHY_DEC_FAILED" 4084 "TOA_FAILED" 4083 "STS_FAILED" 4082 "MAC_DEC_FAILED" 4081 "IE_DEC_FAILED" 4080 "IE_MISSING" ;
VAL_ 1067 VCSEC_UWBRearDistance0 4095 "SNA" 4094 "NOT_ENABLED" 4093 "INITIATOR_TIMEOUT" 4092 "RESPONDER_TIMEOUT" 4091 "INVALID_DISTANCE" 4090 "HCI_TIMEOUT" 4089 "RESPONDER_ERROR" 4088 "KEYFOB_DIDNT_RESPOND" 4087 "TX_FAILED" 4086 "RX_TIMEOUT" 4085 "PHY_DEC_FAILED" 4084 "TOA_FAILED" 4083 "STS_FAILED" 4082 "MAC_DEC_FAILED" 4081 "IE_DEC_FAILED" 4080 "IE_MISSING" ;
VAL_ 1067 VCSEC_UWBRearLeftDistance0 4095 "SNA" 4094 "NOT_ENABLED" 4093 "INITIATOR_TIMEOUT" 4092 "RESPONDER_TIMEOUT" 4091 "INVALID_DISTANCE" 4090 "HCI_TIMEOUT" 4089 "RESPONDER_ERROR" 4088 "KEYFOB_DIDNT_RESPOND" 4087 "TX_FAILED" 4086 "RX_TIMEOUT" 4085 "PHY_DEC_FAILED" 4084 "TOA_FAILED" 4083 "STS_FAILED" 4082 "MAC_DEC_FAILED" 4081 "IE_DEC_FAILED" 4080 "IE_MISSING" ;
VAL_ 1067 VCSEC_UWBCenterDistance0 4095 "SNA" 4094 "NOT_ENABLED" 4093 "INITIATOR_TIMEOUT" 4092 "RESPONDER_TIMEOUT" 4091 "INVALID_DISTANCE" 4090 "HCI_TIMEOUT" 4089 "RESPONDER_ERROR" 4088 "KEYFOB_DIDNT_RESPOND" 4087 "TX_FAILED" 4086 "RX_TIMEOUT" 4085 "PHY_DEC_FAILED" 4084 "TOA_FAILED" 4083 "STS_FAILED" 4082 "MAC_DEC_FAILED" 4081 "IE_DEC_FAILED" 4080 "IE_MISSING" ;
VAL_ 761 VCSEC_bleDisconnectionReason 255 "UNKNOWN_REASON_FF" 62 "CONNECTION_FAILED_TO_ESTABLISH" 61 "MIC_FAILURE" 59 "UNACCEPTABLE_CONNECTION_INTERVAL" 41 "KEY_PAIRING_NOT_SUPPORTED" 40 "CONTROL_PACKET_INSTANT_PASSED" 34 "CONTROL_PACKET_TIMEOUT" 26 "UNSUPPORTED_REMOTE_FEATURE" 22 "HOST_REQUESTED_TERMINATION" 21 "REMOTE_DEVICE_POWER_OFF" 20 "REMOTE_DEVICE_LOW_RESOURCES" 19 "REMOTE_USER_TERMINATED" 8 "CONNECTION_SUPERVISION_TIMEOUT" 5 "AUTHENTICATION_FAILURE" 0 "UNKNOWN_REASON_0" ;
VAL_ 761 VCSEC_AdditionalAuthInfoIndex 5 "WALKUP_UNLOCK_BEHAVIOR" 4 "UNKNOWN_BLE_DEVICE_WITH_IN_SUMMON_RANGE" 3 "KEY_WITH_IN_SUMMON_RANGE_2" 2 "KEY_WITH_IN_SUMMON_RANGE_1" 1 "KEY_WITH_IN_SUMMON_RANGE_0" 0 "ACTIVE_KEY_SHA1" ;
VAL_ 761 VCSEC_unsecureNotificationStatus 2 "INHIBITED" 1 "NOTIFY_DOOR_OPEN" 0 "NONE" ;
VAL_ 761 VCSEC_activeKeyReason 7 "ACTIVE_KEY_SELECTION_REASON_UWB_DEVICE_CLOSEST_TO_DOOR" 6 "ACTIVE_KEY_SELECTION_REASON_AUTO_PRESENT_DOOR_COMMAND" 5 "ACTIVE_KEY_SELECTION_REASON_ONLY_AUTHED_DEVICE" 4 "ACTIVE_KEY_SELECTION_REASON_RKE_ACTION" 3 "ACTIVE_KEY_SELECTION_REASON_BLE_DEVICE_CLOSEST_TO_DOOR" 2 "ACTIVE_KEY_SELECTION_REASON_RKE_AUTH" 1 "ACTIVE_KEY_SELECTION_REASON_NFC_AUTH" 0 "ACTIVE_KEY_SELECTION_REASON_NONE" ;
VAL_ 761 VCSEC_algoUsedForSummonRange0 1 "SUMMON_RANGE_ALGO_USED_UWB" 0 "SUMMON_RANGE_ALGO_USED_BLE" ;
VAL_ 761 VCSEC_algoUsedForSummonRange1 1 "SUMMON_RANGE_ALGO_USED_UWB" 0 "SUMMON_RANGE_ALGO_USED_BLE" ;
VAL_ 761 VCSEC_algoUsedForSummonRange2 1 "SUMMON_RANGE_ALGO_USED_UWB" 0 "SUMMON_RANGE_ALGO_USED_BLE" ;
VAL_ 761 VCSEC_WalkupUnlockMitigationDesi 2 "ON" 1 "OFF" 0 "NONE" ;
VAL_ 761 VCSEC_WalkupUnlockMitigationReas 1 "REASON_DISABLE_FOR_FREQUENT_FALSE_UNLOCKS" 0 "CONTROL_REASON_NONE" ;
VAL_ 761 VCSEC_WalkupUnlockMitigatio_0001 2 "ON" 1 "OFF" 0 "NONE" ;
VAL_ 761 VCSEC_WalkupUnlockMitigatio_0005 1 "REASON_DISABLE_FOR_FREQUENT_FALSE_UNLOCKS" 0 "CONTROL_REASON_NONE" ;
VAL_ 761 VCSEC_WalkupUnlockMitigatio_0002 2 "ON" 1 "OFF" 0 "NONE" ;
VAL_ 761 VCSEC_WalkupUnlockMitigatio_0006 1 "REASON_DISABLE_FOR_FREQUENT_FALSE_UNLOCKS" 0 "CONTROL_REASON_NONE" ;
VAL_ 761 VCSEC_NFCAuthFromBPillarFormFact 4 "KEY_FORM_FACTOR_COARSE_UNKNOWN" 3 "KEY_FORM_FACTOR_COARSE_ANDROID" 2 "KEY_FORM_FACTOR_COARSE_KEYFOB" 1 "KEY_FORM_FACTOR_COARSE_NFC_CARD" 0 "KEY_FORM_FACTOR_COARSE_NONE" ;
VAL_ 761 VCSEC_NFCAuthFromCenterConsoleFo 4 "KEY_FORM_FACTOR_COARSE_UNKNOWN" 3 "KEY_FORM_FACTOR_COARSE_ANDROID" 2 "KEY_FORM_FACTOR_COARSE_KEYFOB" 1 "KEY_FORM_FACTOR_COARSE_NFC_CARD" 0 "KEY_FORM_FACTOR_COARSE_NONE" ;
